VERSION ""

NS_ :

BS_:

BU_: TM

BO_ 579 VCU5: 8 Vector__XXX
 SG_ VcuHazardLampReqStatus : 50|2@0+ (1,0) [0|3] ""  TM
 SG_ VcuHazardLampReq : 51|1@0+ (1,0) [0|1] ""  TM
 SG_ VCuPresence : 0|1@0+ (1,0) [0|1] ""  TM
 SG_ BrkVacPumpStatus : 40|1@0+ (1,0) [0|1] ""  TM
 SG_ DriveMotorStatus : 53|1@0+ (1,0) [0|1] ""  TM
 SG_ HvBattSoh : 52|1@0+ (1,0) [0|1] ""  TM
 SG_ RegenAmpHr : 29|8@0+ (0.5,0) [0|125] ""  TM
 SG_ HvBattPackVolStatus : 55|2@0+ (1,0) [0|3] ""  TM
 SG_ HvBattPackVol : 37|13@0+ (0.1,0) [0|500] ""  TM
 SG_ AvgEnergyConsmption : 48|9@0+ (1,0) [0|511] "kwH/Km"  TM
 SG_ AvgEnergyConsmptionStatus : 17|2@0+ (1,0) [0|3] ""  TM
 SG_ MotorHightempStatus : 19|2@0+ (1,0) [0|3] ""  TM
 SG_ MotorHightemp : 31|2@0+ (1,0) [0|3] ""  TM
 SG_ VcuGearSelectionChangeTxt : 21|2@0+ (1,0) [0|3] ""  TM
 SG_ ImmoStatusVcu : 8|1@0+ (1,0) [0|1] ""  TM
 SG_ ClntTempVcuStatus : 23|2@0+ (1,0) [0|3] ""  TM
 SG_ ClntTempVcu : 15|7@0+ (1,-10) [-10|80] "deg"  TM
 SG_ GearForDisplayVcu : 7|4@0+ (1,0) [0|15] ""  TM
 SG_ GearForDisplayVcuStatus : 3|2@0+ (1,0) [0|3] ""  TM

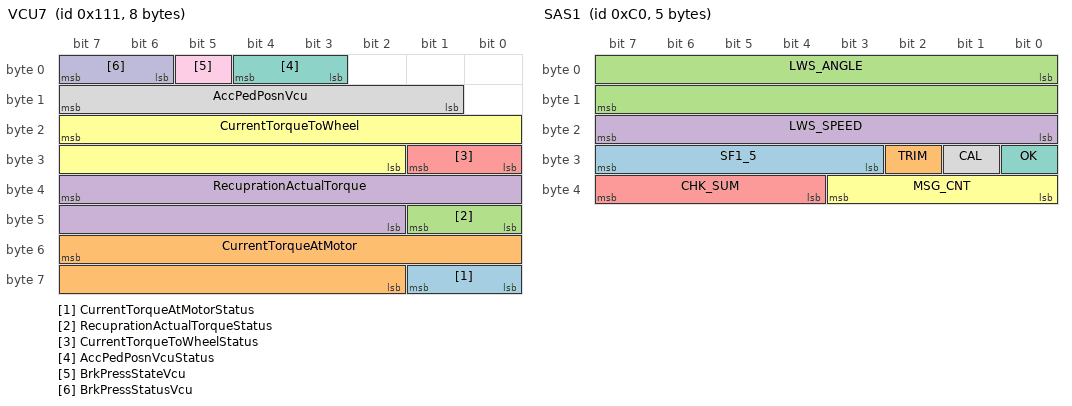
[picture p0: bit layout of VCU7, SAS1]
BO_ 273 VCU7: 8 Vector__XXX
 SG_ CurrentTorqueAtMotorStatus : 57|2@0+ (1,0) [0|3] ""  TM
 SG_ CurrentTorqueAtMotor : 55|14@0+ (0.25,-2048) [-2048|2047.75] ""  TM
 SG_ RecuprationActualTorqueStatus : 41|2@0+ (1,0) [0|3] ""  TM
 SG_ RecuprationActualTorque : 39|14@0+ (0.25,-2048) [-2048|2047.75] ""  TM
 SG_ CurrentTorqueToWheelStatus : 25|2@0+ (1,0) [0|3] ""  TM
 SG_ CurrentTorqueToWheel : 23|14@0+ (0.25,-2048) [-2048|2047.75] ""  TM
 SG_ AccPedPosnVcuStatus : 4|2@0+ (1,0) [0|3] ""  TM
 SG_ AccPedPosnVcu : 15|7@0+ (1,0) [0|100] "%"  TM
 SG_ BrkPressStateVcu : 5|1@0+ (1,0) [0|1] ""  TM
 SG_ BrkPressStatusVcu : 7|2@0+ (1,0) [0|3] ""  TM

BO_ 192 SAS1: 5 Vector__XXX
 SG_ SF1_5 : 27|5@1+ (1,0) [0|31] ""  TM
 SG_ TRIM : 26|1@1+ (1,0) [0|1] ""  TM
 SG_ LWS_ANGLE : 0|16@1- (0.1,0) [-780|779.9] "degree"  TM
 SG_ LWS_SPEED : 16|8@1+ (4,0) [0|1016] "deg /sec"  TM
 SG_ CHK_SUM : 36|4@1+ (1,0) [0|15] ""  TM
 SG_ MSG_CNT : 32|4@1+ (1,0) [0|15] ""  TM
 SG_ OK : 24|1@1+ (1,0) [0|1] ""  TM
 SG_ CAL : 25|1@1+ (1,0) [0|1] ""  TM

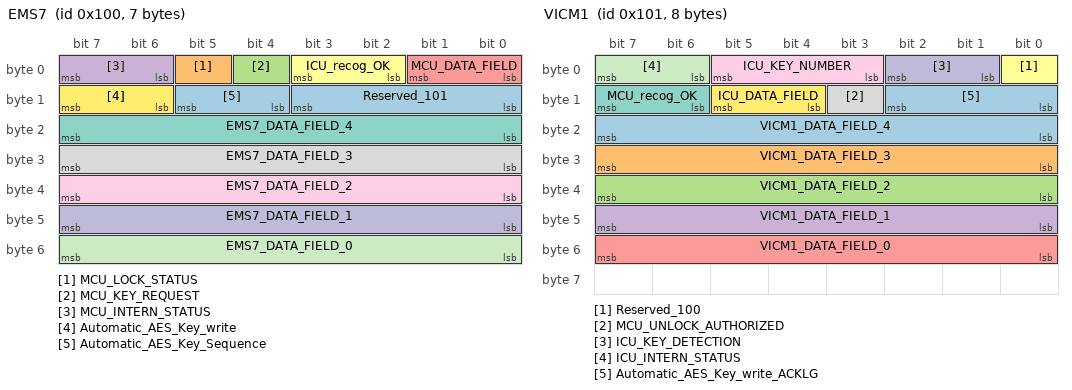
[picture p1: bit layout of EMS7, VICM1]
BO_ 256 EMS7: 7 Vector__XXX
 SG_ Reserved_101 : 11|4@0+ (1,0) [0|0] ""  TM
 SG_ MCU_LOCK_STATUS : 5|1@0+ (1,0) [0|0] ""  TM
 SG_ MCU_KEY_REQUEST : 4|1@0+ (1,0) [0|0] ""  TM
 SG_ MCU_INTERN_STATUS : 7|2@0+ (1,0) [0|0] ""  TM
 SG_ MCU_DATA_FIELD : 1|2@0+ (1,0) [0|0] ""  TM
 SG_ ICU_recog_OK : 3|2@0+ (1,0) [0|0] ""  TM
 SG_ EMS7_DATA_FIELD_4 : 23|8@0+ (1,0) [0|0] ""  TM
 SG_ EMS7_DATA_FIELD_3 : 31|8@0+ (1,0) [0|0] ""  TM
 SG_ EMS7_DATA_FIELD_2 : 39|8@0+ (1,0) [0|0] ""  TM
 SG_ EMS7_DATA_FIELD_1 : 47|8@0+ (1,0) [0|0] ""  TM
 SG_ EMS7_DATA_FIELD_0 : 55|8@0+ (1,0) [0|0] ""  TM
 SG_ Automatic_AES_Key_write : 15|2@0+ (1,0) [0|0] ""  TM
 SG_ Automatic_AES_Key_Sequence : 13|2@0+ (1,0) [0|0] ""  TM

BO_ 257 VICM1: 8 Vector__XXX
 SG_ VICM1_DATA_FIELD_4 : 23|8@0+ (1,0) [0|0] ""  TM
 SG_ VICM1_DATA_FIELD_3 : 31|8@0+ (1,0) [0|0] ""  TM
 SG_ VICM1_DATA_FIELD_2 : 39|8@0+ (1,0) [0|0] ""  TM
 SG_ VICM1_DATA_FIELD_1 : 47|8@0+ (1,0) [0|0] ""  TM
 SG_ VICM1_DATA_FIELD_0 : 55|8@0+ (1,0) [0|0] ""  TM
 SG_ Reserved_100 : 0|1@0+ (1,0) [0|0] ""  TM
 SG_ MCU_recog_OK : 15|2@0+ (1,0) [0|0] ""  TM
 SG_ MCU_UNLOCK_AUTHORIZED : 11|1@0+ (1,0) [0|0] ""  TM
 SG_ ICU_KEY_NUMBER : 5|3@0+ (1,0) [0|0] ""  TM
 SG_ ICU_KEY_DETECTION : 2|2@0+ (1,0) [0|0] ""  TM
 SG_ ICU_INTERN_STATUS : 7|2@0+ (1,0) [0|0] ""  TM
 SG_ ICU_DATA_FIELD : 13|2@0+ (1,0) [0|0] ""  TM
 SG_ Automatic_AES_Key_write_ACKLG : 10|3@0+ (1,0) [0|0] ""  TM

BO_ 259 SRS1: 8 Vector__XXX
 SG_ CrashOutputSignalStatus : 31|2@0+ (1,0) [0|3] ""  TM
 SG_ MSG_CNT_5 : 51|4@0+ (1,0) [0|15] ""  TM
 SG_ CRC_5 : 63|8@0+ (1,0) [0|255] ""  TM
 SG_ RrMiddleSeatBeltSwitchState : 28|1@0+ (1,0) [0|1] ""  TM
 SG_ RrDrvSeatBeltSwitchState : 27|1@0+ (1,0) [0|1] ""  TM
 SG_ RrPassSeatBeltSwitchState : 29|1@0+ (1,0) [0|1] ""  TM
 SG_ FrPassSeatBeltSwitchState : 26|1@0+ (1,0) [0|1] ""  TM
 SG_ FrDrvSeatBeltSwitchState : 25|1@0+ (1,0) [0|1] ""  TM
 SG_ FrDrvSBRChime : 23|2@0+ (1,0) [0|3] ""  TM
 SG_ FrDrvSBRIndication : 24|1@0+ (1,0) [0|1] ""  TM
 SG_ CrashoutputSignal : 7|8@0+ (1,0) [0|255] ""  TM
 SG_ RearDrvSBRChime : 9|2@0+ (1,0) [0|3] ""  TM
 SG_ RearmiddlePassSBRChime : 11|2@0+ (1,0) [0|3] ""  TM
 SG_ FrPassSBRChime : 13|2@0+ (1,0) [0|3] ""  TM
 SG_ RearPassSBRChime : 15|2@0+ (1,0) [0|3] ""  TM
 SG_ RearDrvSBRIndication : 16|1@0+ (1,0) [0|1] ""  TM
 SG_ RearmiddlePassSBRIndication : 17|1@0+ (1,0) [0|1] ""  TM
 SG_ RearPassSBRIndication : 18|1@0+ (1,0) [0|1] ""  TM
 SG_ FrPassSBRIndication : 19|1@0+ (1,0) [0|1] ""  TM
 SG_ SRSWarningLamp : 20|1@0+ (1,0) [0|1] ""  TM
 SG_ PassAirbagDeActIndi : 21|1@0+ (1,0) [0|0] ""  TM

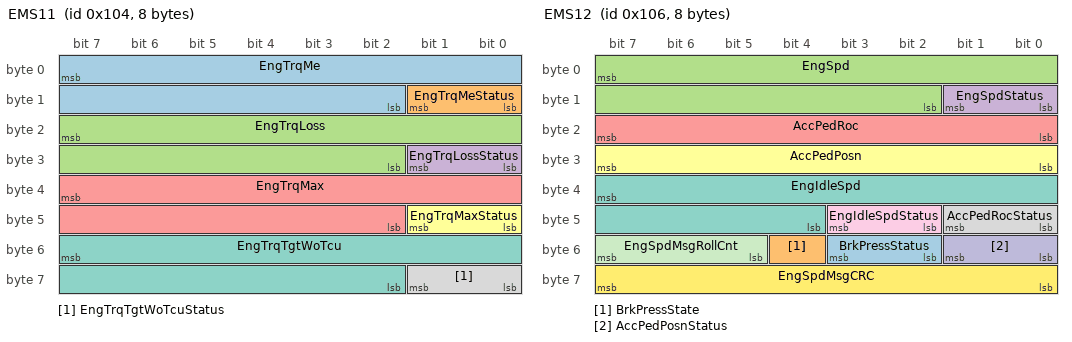
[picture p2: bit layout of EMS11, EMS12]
BO_ 260 EMS11: 8 Vector__XXX
 SG_ EngTrqMe : 7|14@0+ (0.25,-2048) [-2048|2047.75] "Nm"  TM
 SG_ EngTrqMeStatus : 9|2@0+ (1,0) [0|3] ""  TM
 SG_ EngTrqLoss : 23|14@0+ (0.25,-2048) [-2048|2047.75] "Nm"  TM
 SG_ EngTrqLossStatus : 25|2@0+ (1,0) [0|3] ""  TM
 SG_ EngTrqMax : 39|14@0+ (0.25,-2048) [-2048|2047.75] "Nm"  TM
 SG_ EngTrqMaxStatus : 41|2@0+ (1,0) [0|3] ""  TM
 SG_ EngTrqTgtWoTcu : 55|14@0+ (0.25,-2048) [-2048|2047.75] "Nm"  TM
 SG_ EngTrqTgtWoTcuStatus : 57|2@0+ (1,0) [0|3] ""  TM

BO_ 262 EMS12: 8 Vector__XXX
 SG_ BrkPressStatus : 51|2@0+ (1,0) [0|3] ""  TM
 SG_ BrkPressState : 52|1@0+ (1,0) [0|1] ""  TM
 SG_ EngSpd : 7|14@0+ (1,0) [0|16383] "rpm"  TM
 SG_ EngSpdStatus : 9|2@0+ (1,0) [0|3] ""  TM
 SG_ AccPedRoc : 23|8@0+ (16,-2000) [-2000|2000] "% / s"  TM
 SG_ AccPedPosn : 31|8@0+ (0.5,0) [0|100] "%"  TM
 SG_ EngIdleSpd : 39|12@0+ (1,0) [0|3000] "rpm"  TM
 SG_ AccPedRocStatus : 41|2@0+ (1,0) [0|3] ""  TM
 SG_ EngIdleSpdStatus : 43|2@0+ (1,0) [0|3] ""  TM
 SG_ AccPedPosnStatus : 49|2@0+ (1,0) [0|3] ""  TM
 SG_ EngSpdMsgRollCnt : 55|3@0+ (1,0) [0|7] ""  TM
 SG_ EngSpdMsgCRC : 63|8@0+ (1,0) [0|255] ""  TM

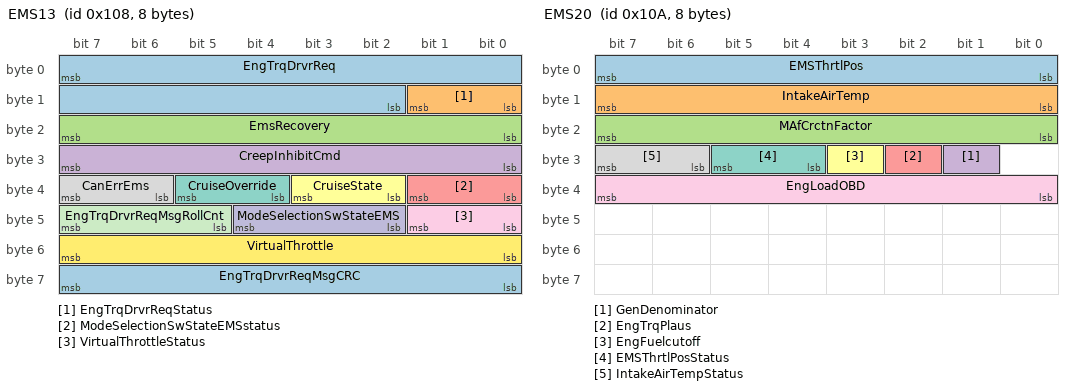
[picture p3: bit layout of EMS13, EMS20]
BO_ 264 EMS13: 8 Vector__XXX
 SG_ EngTrqDrvrReq : 7|14@0+ (0.25,-2048) [-2048|2047.75] "Nm"  TM
 SG_ EngTrqDrvrReqStatus : 9|2@0+ (1,0) [0|3] ""  TM
 SG_ EmsRecovery : 23|8@0+ (1,0) [0|255] ""  TM
 SG_ CreepInhibitCmd : 31|8@0+ (1,0) [0|255] ""  TM
 SG_ ModeSelectionSwStateEMSstatus : 33|2@0+ (1,0) [0|3] ""  TM
 SG_ CruiseState : 35|2@0+ (1,0) [0|3] ""  TM
 SG_ CruiseOverride : 37|2@0+ (1,0) [0|3] ""  TM
 SG_ CanErrEms : 39|2@0+ (1,0) [0|3] ""  TM
 SG_ VirtualThrottleStatus : 41|2@0+ (1,0) [0|3] ""  TM
 SG_ ModeSelectionSwStateEMS : 44|3@0+ (1,0) [0|7] ""  TM
 SG_ EngTrqDrvrReqMsgRollCnt : 47|3@0+ (1,0) [0|7] ""  TM
 SG_ VirtualThrottle : 55|8@0+ (0.5,0) [0|100] "%"  TM
 SG_ EngTrqDrvrReqMsgCRC : 63|8@0+ (1,0) [0|255] ""  TM

BO_ 266 EMS20: 8 Vector__XXX
 SG_ EMSThrtlPos : 7|8@0+ (0.4694836,-15.0234752) [-15.0234752|104.694843] "%"  TM
 SG_ IntakeAirTemp : 15|8@0+ (0.75,-48) [-48|143.25] "DegC"  TM
 SG_ MAfCrctnFactor : 23|8@0+ (0.00781,0) [0|1.99155] ""  TM
 SG_ GenDenominator : 25|1@0+ (1,0) [0|1] ""  TM
 SG_ EngTrqPlaus : 26|1@0+ (1,0) [0|1] ""  TM
 SG_ EngFuelcutoff : 27|1@0+ (1,0) [0|1] ""  TM
 SG_ EMSThrtlPosStatus : 29|2@0+ (1,0) [0|3] ""  TM
 SG_ IntakeAirTempStatus : 31|2@0+ (1,0) [0|3] ""  TM
 SG_ EngLoadOBD : 39|8@0+ (0.3922,0) [0|100] "%"  TM

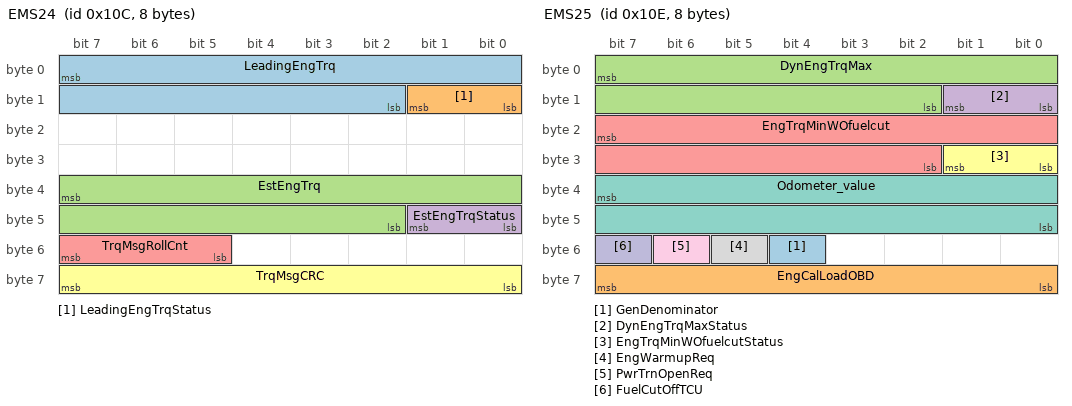
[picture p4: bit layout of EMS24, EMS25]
BO_ 268 EMS24: 8 Vector__XXX
 SG_ LeadingEngTrq : 7|14@0+ (0.25,-2048) [-2048|2047.75] "Nm"  TM
 SG_ LeadingEngTrqStatus : 9|2@0+ (1,0) [0|3] ""  TM
 SG_ EstEngTrq : 39|14@0+ (0.25,-2048) [-2048|2047.75] "Nm"  TM
 SG_ EstEngTrqStatus : 41|2@0+ (1,0) [0|3] ""  TM
 SG_ TrqMsgRollCnt : 55|3@0+ (1,0) [0|7] ""  TM
 SG_ TrqMsgCRC : 63|8@0+ (1,0) [0|255] ""  TM

BO_ 270 EMS25: 8 Vector__XXX
 SG_ GenDenominator : 52|1@0+ (1,0) [0|1] ""  TM
 SG_ EngCalLoadOBD : 63|8@0+ (0.75,0) [0|191.25] ""  TM
 SG_ DynEngTrqMax : 7|14@0+ (0.25,-2048) [-2048|2047.75] "Nm"  TM
 SG_ DynEngTrqMaxStatus : 9|2@0+ (1,0) [0|3] ""  TM
 SG_ EngTrqMinWOfuelcut : 23|14@0+ (0.25,0) [-2048|2047.75] "Nm"  TM
 SG_ EngTrqMinWOfuelcutStatus : 25|2@0+ (1,0) [0|3] ""  TM
 SG_ Odometer_value : 39|16@0+ (1,0) [0|65535] "km/Count"  TM
 SG_ EngWarmupReq : 53|1@0+ (1,0) [0|1] ""  TM
 SG_ PwrTrnOpenReq : 54|1@0+ (1,0) [0|1] ""  TM
 SG_ FuelCutOffTCU : 55|1@0+ (1,0) [0|1] ""  TM

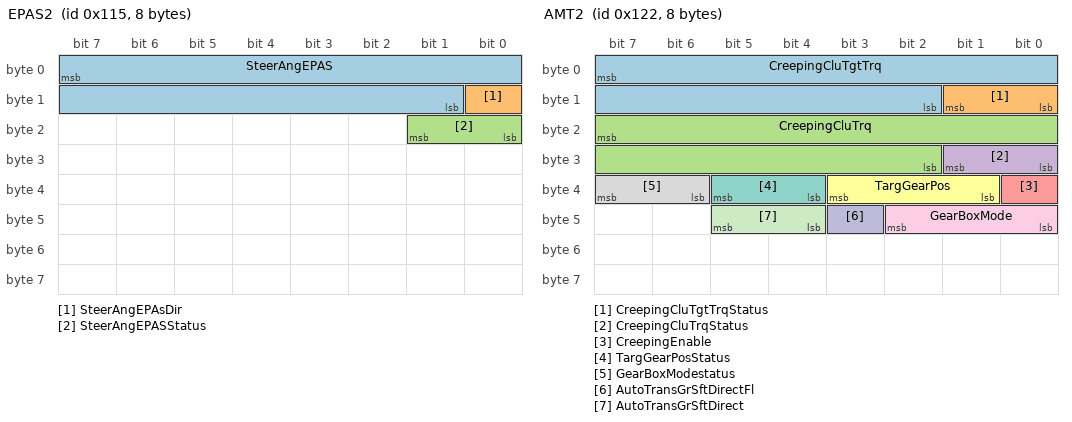
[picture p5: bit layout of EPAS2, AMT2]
BO_ 277 EPAS2: 8 Vector__XXX
 SG_ SteerAngEPAS : 7|15@0+ (0.04375,0) [0|1433.55625] " deg"  TM
 SG_ SteerAngEPAsDir : 8|1@0+ (1,0) [0|1] ""  TM
 SG_ SteerAngEPASStatus : 17|2@0+ (1,0) [0|3] ""  TM

BO_ 279 BRAKE4: 8 Vector__XXX
 SG_ SAsCcw : 20|4@0+ (1,0) [0|15] ""  TM

BO_ 288 AMT1: 8 Vector__XXX
 SG_ RESSEnableStatus : 55|2@0+ (1,0) [0|3] ""  TM
 SG_ RESSEnable : 24|1@0+ (1,0) [0|1] ""  TM
 SG_ EngTrqReq : 7|14@0+ (0.25,-2048) [-2048|2047.75] "Nm"  TM
 SG_ EngTrqReqStatus : 9|2@0+ (1,0) [0|3] ""  TM
 SG_ EngTrqReqComplement : 23|14@0+ (0.25,-2048) [-2048|2047.75] "Nm"  TM
 SG_ CluEngagedStatus : 33|2@0+ (1,0) [0|3] ""  TM
 SG_ CluEngagedTCU : 35|2@0+ (1,0) [0|3] ""  TM
 SG_ MessageCounterAmt : 39|4@0+ (1,0) [0|15] ""  TM
 SG_ TransLimpHomeActive : 40|1@0+ (1,0) [0|1] ""  TM
 SG_ EngStopReq : 41|1@0+ (1,0) [0|1] ""  TM
 SG_ CrnkEnable : 42|1@0+ (1,0) [0|1] ""  TM
 SG_ EngTrqCtrlActive : 43|1@0+ (1,0) [0|1] ""  TM
 SG_ HydraulicPumpActive : 44|1@0+ (1,0) [0|1] ""  TM
 SG_ ReqTrqValueActive : 45|1@0+ (1,0) [0|1] ""  TM
 SG_ EngTrqIncActive : 46|1@0+ (1,0) [0|1] ""  TM
 SG_ EngTrqRednActive : 47|1@0+ (1,0) [0|1] ""  TM
 SG_ CurGearTcuStatus : 49|2@0+ (1,0) [0|3] ""  TM
 SG_ CurGearTcu : 53|4@0+ (1,0) [0|15] ""  TM
 SG_ EngStopReqComplement : 63|8@0+ (1,0) [0|255] ""  TM

BO_ 290 AMT2: 8 Vector__XXX
 SG_ CreepingCluTgtTrq : 7|14@0+ (0.25,-2048) [-2048|2047.75] "Nm"  TM
 SG_ CreepingCluTgtTrqStatus : 9|2@0+ (1,0) [0|3] ""  TM
 SG_ CreepingCluTrq : 23|14@0+ (0.25,-2048) [-2048|2047.75] "Nm"  TM
 SG_ CreepingCluTrqStatus : 25|2@0+ (1,0) [0|3] ""  TM
 SG_ CreepingEnable : 32|1@0+ (1,0) [0|1] ""  TM
 SG_ TargGearPos : 35|3@0+ (1,0) [0|7] ""  TM
 SG_ TargGearPosStatus : 37|2@0+ (1,0) [0|3] ""  TM
 SG_ GearBoxModestatus : 39|2@0+ (1,0) [0|3] ""  TM
 SG_ GearBoxMode : 42|3@0+ (1,0) [0|7] ""  TM
 SG_ AutoTransGrSftDirectFl : 43|1@0+ (1,0) [0|1] ""  TM
 SG_ AutoTransGrSftDirect : 45|2@0+ (1,0) [0|3] ""  TM

BO_ 291 DCT4: 8 Vector__XXX
 SG_ ReserveTorqueRequestIntervention : 42|1@0+ (1,0) [0|1] ""  TM
 SG_ ReserveTorqueRequest : 41|6@0+ (1,0) [0|50] "Nm"  TM
 SG_ DctPepsLockState : 44|2@0+ (1,0) [0|3] ""  TM
 SG_ RESSEnableDctStatus : 46|2@0+ (1,0) [0|3] ""  TM
 SG_ RESSEnableDct : 47|1@0+ (1,0) [0|1] ""  TM
 SG_ CreepState : 32|1@0+ (1,0) [0|1] ""  TM
 SG_ TCUTxFastTrqMsgRollCnt : 51|4@0+ (1,0) [0|15] ""  TM
 SG_ TCUTxFastTrqMsgCRC : 63|8@0+ (1,0) [0|255] ""  TM
 SG_ TxmnGearRatio : 7|15@0+ (0.001,0) [0|32.767] ""  TM
 SG_ TransLimpHomeActive : 8|1@0+ (1,0) [0|1] ""  TM
 SG_ FastTrqIntrvntnStatus : 17|2@0+ (1,0) [0|3] ""  TM
 SG_ FastTrqIntrvntn : 19|2@0+ (1,0) [0|3] ""  TM
 SG_ SlowTrqIntrvntnStatus : 21|2@0+ (1,0) [0|3] ""  TM
 SG_ SlowTrqIntrvntn : 23|2@0+ (1,0) [0|3] ""  TM
 SG_ AutoTransGrSftDirect : 25|2@0+ (1,0) [0|3] ""  TM
 SG_ CurGearDctStatus : 27|2@0+ (1,0) [0|3] ""  TM
 SG_ CurGearDct : 31|4@0+ (1,0) [0|15] ""  TM
 SG_ TargGearPosDctStatus : 34|2@0+ (1,0) [0|3] ""  TM
 SG_ TargGearPosDct : 38|4@0+ (1,0) [0|15] ""  TM
 SG_ AutoTransGrSftDirectFl : 39|1@0+ (1,0) [0|1] ""  TM

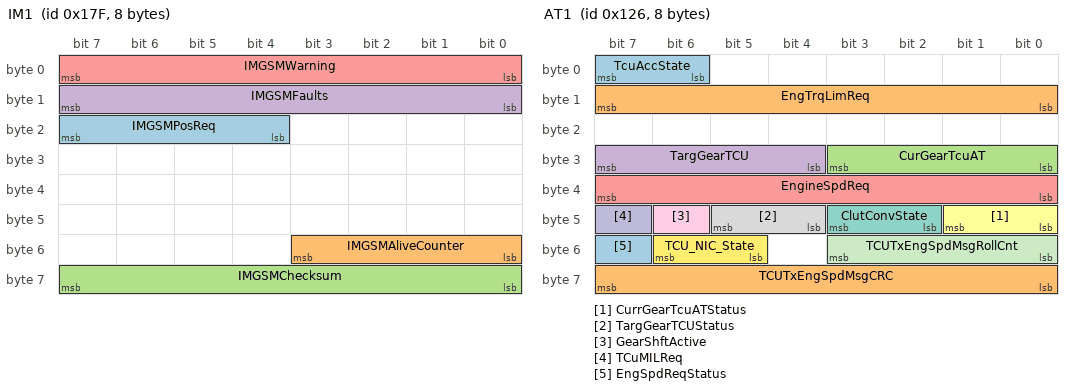
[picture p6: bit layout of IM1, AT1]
BO_ 383 IM1: 8 Vector__XXX
 SG_ IMGSMPosReq : 23|4@0+ (1,0) [0|15] ""  TM
 SG_ IMGSMAliveCounter : 51|4@0+ (1,0) [0|15] ""  TM
 SG_ IMGSMChecksum : 63|8@0+ (1,0) [0|255] ""  TM
 SG_ IMGSMFaults : 15|8@0+ (1,0) [0|255] ""  TM
 SG_ IMGSMWarning : 7|8@0+ (1,0) [0|255] ""  TM

BO_ 294 AT1: 8 Vector__XXX
 SG_ TcuAccState : 7|2@0+ (1,0) [0|3] ""  TM
 SG_ EngTrqLimReq : 15|8@0+ (3,0) [0|765] "Nm"  TM
 SG_ CurGearTcuAT : 27|4@0+ (1,0) [0|15] ""  TM
 SG_ TargGearTCU : 31|4@0+ (1,0) [0|15] ""  TM
 SG_ EngineSpdReq : 39|8@0+ (10,500) [500|3050] "RPM"  TM
 SG_ CurrGearTcuATStatus : 41|2@0+ (1,0) [0|3] ""  TM
 SG_ ClutConvState : 43|2@0+ (1,0) [0|3] ""  TM
 SG_ TargGearTCUStatus : 45|2@0+ (1,0) [0|3] ""  TM
 SG_ GearShftActive : 46|1@0+ (1,0) [0|1] ""  TM
 SG_ TCuMILReq : 47|1@0+ (1,0) [0|1] ""  TM
 SG_ TCUTxEngSpdMsgRollCnt : 51|4@0+ (1,0) [0|15] ""  TM
 SG_ TCU_NIC_State : 54|2@0+ (1,0) [0|3] ""  TM
 SG_ EngSpdReqStatus : 55|1@0+ (1,0) [0|1] ""  TM
 SG_ TCUTxEngSpdMsgCRC : 63|8@0+ (1,0) [0|255] ""  TM

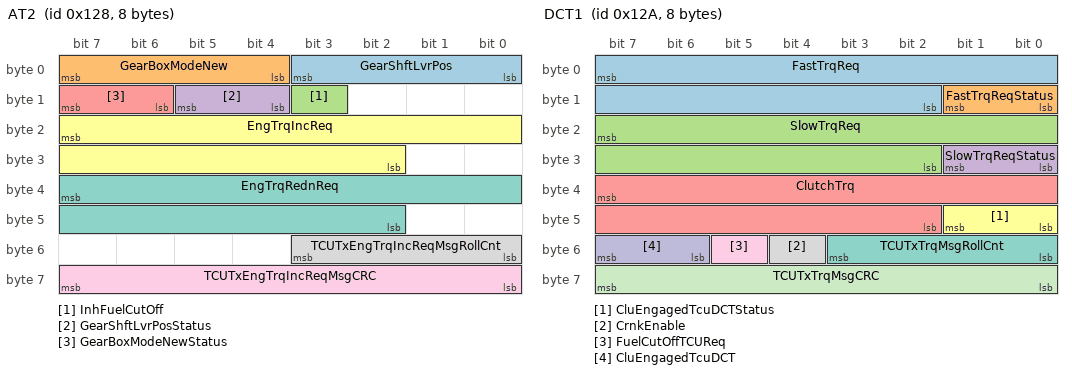
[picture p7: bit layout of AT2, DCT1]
BO_ 296 AT2: 8 Vector__XXX
 SG_ GearShftLvrPos : 3|4@0+ (1,0) [0|15] ""  TM
 SG_ GearBoxModeNew : 7|4@0+ (1,0) [0|15] ""  TM
 SG_ InhFuelCutOff : 11|1@0+ (1,0) [0|1] ""  TM
 SG_ GearShftLvrPosStatus : 13|2@0+ (1,0) [0|3] ""  TM
 SG_ GearBoxModeNewStatus : 15|2@0+ (1,0) [0|3] ""  TM
 SG_ EngTrqIncReq : 23|14@0+ (0.25,-2048) [-2048|2047.75] "Nm"  TM
 SG_ EngTrqRednReq : 39|14@0+ (0.25,-2048) [-2048|2047.75] "Nm"  TM
 SG_ TCUTxEngTrqIncReqMsgRollCnt : 51|4@0+ (1,0) [0|15] ""  TM
 SG_ TCUTxEngTrqIncReqMsgCRC : 63|8@0+ (1,0) [0|255] ""  TM

BO_ 298 DCT1: 8 Vector__XXX
 SG_ FastTrqReq : 7|14@0+ (0.25,-2048) [-2048|2047.75] "Nm"  TM
 SG_ FastTrqReqStatus : 9|2@0+ (1,0) [0|3] ""  TM
 SG_ SlowTrqReq : 23|14@0+ (0.25,-2048) [-2048|2047.75] "Nm"  TM
 SG_ SlowTrqReqStatus : 25|2@0+ (1,0) [0|3] ""  TM
 SG_ ClutchTrq : 39|14@0+ (0.25,-2048) [-2048|2047.75] "Nm"  TM
 SG_ CluEngagedTcuDCTStatus : 41|2@0+ (1,0) [0|3] ""  TM
 SG_ TCUTxTrqMsgRollCnt : 51|4@0+ (1,0) [0|15] ""  TM
 SG_ CrnkEnable : 52|1@0+ (1,0) [0|1] ""  TM
 SG_ FuelCutOffTCUReq : 53|1@0+ (1,0) [0|1] ""  TM
 SG_ CluEngagedTcuDCT : 55|2@0+ (1,0) [0|3] ""  TM
 SG_ TCUTxTrqMsgCRC : 63|8@0+ (1,0) [0|255] ""  TM

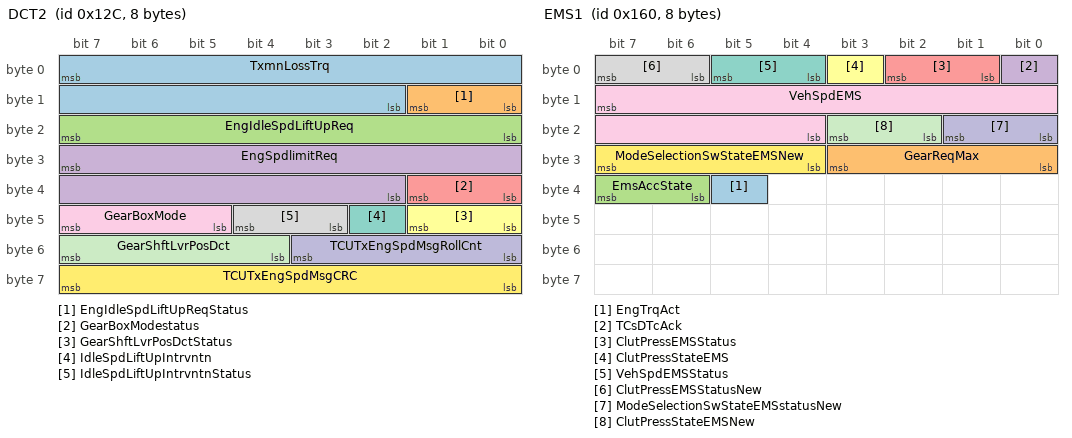
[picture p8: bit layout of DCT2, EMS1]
BO_ 300 DCT2: 8 Vector__XXX
 SG_ TxmnLossTrq : 7|14@0+ (0.25,-2048) [-2048|2047.75] "Nm"  TM
 SG_ EngIdleSpdLiftUpReqStatus : 9|2@0+ (1,0) [0|3] ""  TM
 SG_ EngIdleSpdLiftUpReq : 23|8@0+ (10,0) [0|2000] "rpm"  TM
 SG_ EngSpdlimitReq : 31|14@0+ (1,0) [0|16383] "rpm"  TM
 SG_ GearBoxModestatus : 33|2@0+ (1,0) [0|3] ""  TM
 SG_ GearShftLvrPosDctStatus : 41|2@0+ (1,0) [0|3] ""  TM
 SG_ IdleSpdLiftUpIntrvntn : 42|1@0+ (1,0) [0|1] ""  TM
 SG_ IdleSpdLiftUpIntrvntnStatus : 44|2@0+ (1,0) [0|3] ""  TM
 SG_ GearBoxMode : 47|3@0+ (1,0) [0|7] ""  TM
 SG_ TCUTxEngSpdMsgRollCnt : 51|4@0+ (1,0) [0|15] ""  TM
 SG_ GearShftLvrPosDct : 55|4@0+ (1,0) [0|15] ""  TM
 SG_ TCUTxEngSpdMsgCRC : 63|8@0+ (1,0) [0|255] ""  TM

BO_ 352 EMS1: 8 Vector__XXX
 SG_ EngTrqAct : 37|1@0+ (1,0) [0|1] ""  TM
 SG_ GearReqMax : 27|4@0+ (1,0) [0|15] ""  TM
 SG_ EmsAccState : 39|2@0+ (1,0) [0|3] ""  TM
 SG_ TCsDTcAck : 0|1@0+ (1,0) [0|1] ""  TM
 SG_ ClutPressEMSStatus : 2|2@0+ (1,0) [0|3] ""  TM
 SG_ ClutPressStateEMS : 3|1@0+ (1,0) [0|1] ""  TM
 SG_ VehSpdEMSStatus : 5|2@0+ (1,0) [0|3] ""  TM
 SG_ ClutPressEMSStatusNew : 7|2@0+ (1,0) [0|3] ""  TM
 SG_ VehSpdEMS : 15|12@0+ (0.03125,0) [0|127.96875] "m/s"  TM
 SG_ ModeSelectionSwStateEMSstatusNew : 17|2@0+ (1,0) [0|3] ""  TM
 SG_ ClutPressStateEMSNew : 19|2@0+ (1,0) [0|3] ""  TM
 SG_ ModeSelectionSwStateEMSNew : 31|4@0+ (1,0) [0|15] ""  TM

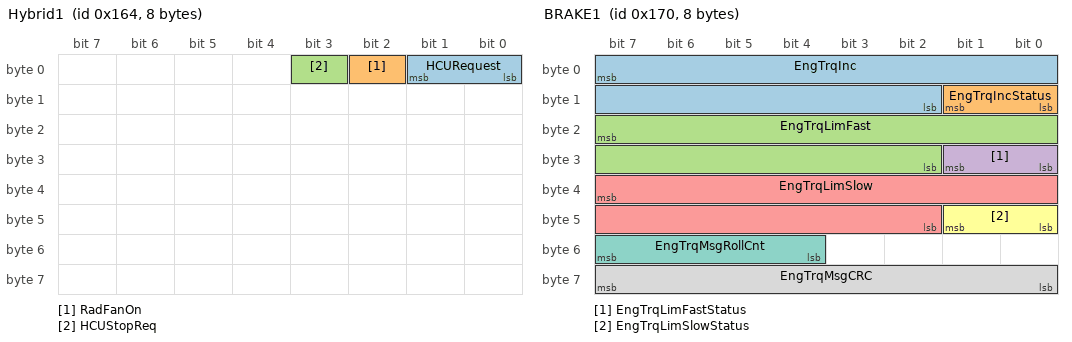
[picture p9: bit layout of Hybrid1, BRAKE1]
BO_ 356 Hybrid1: 8 Vector__XXX
 SG_ HCURequest : 1|2@0+ (1,0) [0|3] ""  TM
 SG_ RadFanOn : 2|1@0+ (1,0) [0|1] ""  TM
 SG_ HCUStopReq : 3|1@0+ (1,0) [0|1] ""  TM

BO_ 359 EEM1: 8 Vector__XXX
 SG_ AltTrq : 7|8@0+ (0.1,0) [0|20] "Nm"  TM

BO_ 368 BRAKE1: 8 Vector__XXX
 SG_ EngTrqInc : 7|14@0+ (0.25,-2048) [-2048|2047.75] "Nm"  TM
 SG_ EngTrqIncStatus : 9|2@0+ (1,0) [0|3] ""  TM
 SG_ EngTrqLimFast : 23|14@0+ (0.25,-2048) [-2048|2047.75] "Nm"  TM
 SG_ EngTrqLimFastStatus : 25|2@0+ (1,0) [0|3] ""  TM
 SG_ EngTrqLimSlow : 39|14@0+ (0.25,-2048) [-2048|2047.75] "Nm"  TM
 SG_ EngTrqLimSlowStatus : 41|2@0+ (1,0) [0|3] ""  TM
 SG_ EngTrqMsgRollCnt : 55|4@0+ (1,0) [0|15] ""  TM
 SG_ EngTrqMsgCRC : 63|8@0+ (1,0) [0|255] ""  TM

CM_ SG_ 579 VcuHazardLampReqStatus "Hazard lamp operation status from VCU to BCM";
CM_ SG_ 579 VcuHazardLampReq "Hazard lamp operation request from VCU to BCM";
CM_ SG_ 579 VCuPresence "ECU presence signal to the partner ECU";
CM_ SG_ 579 BrkVacPumpStatus "This function displays status of the Brake Vaccum Pump Malfunctioning";
CM_ SG_ 579 DriveMotorStatus "This function displays status of the Drive Motor Malfunctioning";
CM_ SG_ 579 HvBattSoh "HV Battery State of Health";
CM_ SG_ 579 RegenAmpHr "Regeneration Battery Charge";
CM_ SG_ 579 HvBattPackVolStatus "HV Battery Pack Voltage Status";
CM_ SG_ 579 HvBattPackVol "HV Battery Pack Voltage";
CM_ SG_ 579 AvgEnergyConsmption "Average Energy Consumption";
CM_ SG_ 579 AvgEnergyConsmptionStatus "Average Energy Consumption Status";
CM_ SG_ 579 MotorHightempStatus "This information is used to determine the Motor High Temp Status";
CM_ SG_ 579 MotorHightemp "This feature provides the traction motor High Temperature Status to the user.";
CM_ SG_ 579 VcuGearSelectionChangeTxt "Indicate the VCU Gear Selection Message";
CM_ SG_ 579 ImmoStatusVcu "This gives status of VCU whether mobilized or immobilized.";
CM_ SG_ 579 ClntTempVcuStatus "This information is used to determine the  Battery coolant temperature signal status. 
";
CM_ SG_ 579 ClntTempVcu "This information is used   to display or indicate the coolant temperature 
";
CM_ SG_ 579 GearForDisplayVcu "Gear For Display";
CM_ SG_ 579 GearForDisplayVcuStatus "Gear For Display Status";
CM_ SG_ 273 CurrentTorqueAtMotorStatus "Status signal of Current Torque At Motor";
CM_ SG_ 273 CurrentTorqueAtMotor "Current Torque At Motor values";
CM_ SG_ 273 RecuprationActualTorqueStatus "Recupration Request Status";
CM_ SG_ 273 RecuprationActualTorque "Recupration Torque values";
CM_ SG_ 273 CurrentTorqueToWheelStatus "Status signal of Current Torque To Wheel signal";
CM_ SG_ 273 CurrentTorqueToWheel "Current Torque To Wheel values";
CM_ SG_ 273 AccPedPosnVcuStatus "This information is used to determine the accelerator pedal position signal status";
CM_ SG_ 273 AccPedPosnVcu "This information is used to determine the accelerator pedal position";
CM_ SG_ 273 BrkPressStateVcu "This inofmation tells whether brake is pressed  or not ";
CM_ SG_ 273 BrkPressStatusVcu "This information is used to determine the  Brake press status signal status. ";
CM_ SG_ 192 SF1_5 "Bosch Internal";
CM_ SG_ 192 TRIM "Triming status of steering angle sensor [Bosch internal]";
CM_ SG_ 192 LWS_ANGLE "Current steering wheel angle
";
CM_ SG_ 192 LWS_SPEED "Steering wheel rotation speed
";
CM_ SG_ 192 CHK_SUM "Check sum for SAS Messages
";
CM_ SG_ 192 MSG_CNT "Message Counter for SAS Message
";
CM_ SG_ 192 OK "The signal indicates the failure status of the steering angle sensor
";
CM_ SG_ 192 CAL "Calibration status of the steering angle sensor
";
CM_ SG_ 256 MCU_LOCK_STATUS "MCU_LOCK_STATUS is given for information.
The MCU repeats the Immobiliser Authentication process every TDelayStopped but MCU will stay in UNLOCKED state (only when the previous authentication is successful)";
CM_ SG_ 256 MCU_KEY_REQUEST "MCU_KEY_REQUEST is checked by ICU
This data is set to force a new key detection by immobilizer ICU.
At IGN ON, this data is not expected as the ICU will directly start key detection before MCU is awake.";
CM_ SG_ 256 MCU_INTERN_STATUS "MCU_INTERN_STATUS is checked by ICU.
Only the value 11b and 01b are allowed to perform MCU-ICU authentication. Other value means
that the MCU is blank or not OK to work.";
CM_ SG_ 256 MCU_DATA_FIELD "MCU_DATA_FIELD is checked by ICU
2 values indicate which of the 2 expected frames is sent, RNmcu or R5icu.
1 value indicates that the field is empty because in CAN frames, no data relative to a running authentication is sent.
";
CM_ SG_ 256 ICU_recog_OK "ICU_recog_OK is for information.
It is not available before end of authentication.
ICU won’t manage this information during authentication.";
CM_ SG_ 256 EMS7_DATA_FIELD_4 "(DATA_FIELD_4 : RNmcu_4 or R5icu _4 or Sk0- Sk3 else blanked)";
CM_ SG_ 256 EMS7_DATA_FIELD_3 "(DATA_FIELD_3: RNmcu _3 or R5icu _3 or Sk4-Sk7 else blanked)";
CM_ SG_ 256 EMS7_DATA_FIELD_2 "(DATA_FIELD_2: RNmcu _2 or R5icu _2 or Sk8-Sk11 else blanked)";
CM_ SG_ 256 EMS7_DATA_FIELD_1 "(DATA_FIELD_1: RNmcu _1 or R5icu _1 or Sk12-Sk15 else blanked)";
CM_ SG_ 256 EMS7_DATA_FIELD_0 "(DATA_FIELD_0: RNmcu _0 or R5icu _0 or else blanked conditions)";
CM_ SG_ 257 VICM1_DATA_FIELD_4 "(DATA_FIELD_4 : RNicu _4 or R5mcu_4 or Sk0- Sk3 else blanked)";
CM_ SG_ 257 VICM1_DATA_FIELD_3 "(DATA_FIELD_3: RNicu _3 or R5mcu _3 or Sk4-Sk7 else blanked)";
CM_ SG_ 257 VICM1_DATA_FIELD_2 "(DATA_FIELD_2: RNicu _2 or R5mcu _2 or Sk8-Sk11 else blanked)";
CM_ SG_ 257 VICM1_DATA_FIELD_1 "(DATA_FIELD_1: RNicu _1 or R5mcu _1 or Sk12-Sk15 else blanked)";
CM_ SG_ 257 VICM1_DATA_FIELD_0 "(DATA_FIELD_0: RNicu _0 or R5mcu _0 or else blanked conditions)";
CM_ SG_ 257 MCU_recog_OK "MCU_recog_OK is checked by MCU
This information is used in 2nd frame to confirm that MCU answer for authentication was ok
(equivalent to R5icu was the one expected by ICU).
If ICU is not ok, its final answer won’t allow mutual authentication for MCU.";
CM_ SG_ 257 MCU_UNLOCK_AUTHORIZED "MCU_UNLOCK_AUTHORIZED is checked by MCU
This information is used in 2nd frame to confirm that MCU is allowed to be unlocked.
It can be considerate as the main answer from the ICU to authentication request.
DATA_FIELD are checked by MCU";
CM_ SG_ 257 ICU_KEY_NUMBER "ICU_KEY_NUMBER is given for information.MCU is allowed to test immobilizer number of learned key.Value higher or equal to 1 is expected to be sure that the immobilizer is in a proper status.";
CM_ SG_ 257 ICU_KEY_DETECTION "ICU_KEY_DETECTION, in second ICU frame, is checked by MCU
When MCU_ICU authentication started, key detection can be already performed or still running.";
CM_ SG_ 257 ICU_INTERN_STATUS "ICU_INTERN_STATUS is checked by MCU.
Only the value 11b and 01b are allowed for the MCU-ICU authentication. Other value means
that the ICU is blank or not ok to work.";
CM_ SG_ 257 ICU_DATA_FIELD "ICU_DATA_FIELD is checked by MCU
2 values indicate which of the 2 expected frames is sent (RNicu or R5mcu).
value (00b) indicates that the field is empty because authentication failed,";
CM_ SG_ 259 CrashOutputSignalStatus "Plausibility status of signal 'CrashOutputSignal'";
CM_ SG_ 259 MSG_CNT_5 "MRC for CrashOutputSignals";
CM_ SG_ 259 CRC_5 "CRC for CrashOutput signals";
CM_ SG_ 259 RrMiddleSeatBeltSwitchState "This function displays status of Rear Middle seatbelt buckle switch";
CM_ SG_ 259 RrDrvSeatBeltSwitchState "This function displays status of Rear Driver seatbelt buckle switch";
CM_ SG_ 259 RrPassSeatBeltSwitchState "This function displays status of Rear Passenger seatbelt buckle switch";
CM_ SG_ 259 FrPassSeatBeltSwitchState "This function displays status of Front Passenger seatbelt buckle switch";
CM_ SG_ 259 FrDrvSeatBeltSwitchState "This function displays status of Front Driver seatbelt buckle switch";
CM_ SG_ 259 FrDrvSBRChime "Chime request signal  to IC Display for driver";
CM_ SG_ 259 FrDrvSBRIndication "Visual Indication request signal to SBR Display  for driver";
CM_ SG_ 259 CrashoutputSignal "CrashOutput signal in the event of no Crash";
CM_ SG_ 259 RearDrvSBRChime "Chime request signal to IC Display for Rear Driver passenger";
CM_ SG_ 259 RearmiddlePassSBRChime "Chime request signal  to IC Display for rear middle passenger";
CM_ SG_ 259 FrPassSBRChime "Chime request signal to IC Display  for passenger";
CM_ SG_ 259 RearPassSBRChime "Chime request signal to IC Display for rear passenger";
CM_ SG_ 259 RearDrvSBRIndication "Visual Indication request signal to SBR Display for Rear Driver passengerr";
CM_ SG_ 259 RearmiddlePassSBRIndication "Visual Indication request signal to SBR Display for Rear middle Driver passengerr";
CM_ SG_ 259 RearPassSBRIndication "Visual Indication request signal to SBR Display for rear passenger";
CM_ SG_ 259 FrPassSBRIndication "Visual indication request signal to SBR display for passenger.";
CM_ SG_ 259 SRSWarningLamp "AWL Warning Lamp signal Request to IC";
CM_ SG_ 259 PassAirbagDeActIndi "PAD Indication signal request to SBR Display";
CM_ SG_ 260 EngTrqMe "Current engine torque, reduced by engine drag torque (friction) and torque consumption of auxiliary devices, but without inertia correction.
";
CM_ SG_ 260 EngTrqMeStatus "Current engine torque, status info";
CM_ SG_ 260 EngTrqLoss "used to know torque loss by accessories";
CM_ SG_ 260 EngTrqLossStatus "Engine torque requested by driver, status info
";
CM_ SG_ 260 EngTrqMax "allowable maximum torque at flywheel at specific operating point, delivered by the engine";
CM_ SG_ 260 EngTrqMaxStatus "quality/status information to EngTrqLimSlow";
CM_ SG_ 260 EngTrqTgtWoTcu "This signal indicates what should be the target torque after the gear shift.";
CM_ SG_ 260 EngTrqTgtWoTcuStatus "quality/status information to EngTrqTgtWoTcu";
CM_ SG_ 262 BrkPressStatus "status information of Brake pedal";
CM_ SG_ 262 BrkPressState "This inofmation tells whether brake is pressed  or not ";
CM_ SG_ 262 EngSpd "Crank shaft speed of engine";
CM_ SG_ 262 EngSpdStatus "Crank shaft speed of engine, status
";
CM_ SG_ 262 AccPedRoc "accelerator pedal position rate of change
gradient of APM signal";
CM_ SG_ 262 AccPedPosn "accelerator pedal position.";
CM_ SG_ 262 EngIdleSpd "engine idle speed is Engine RPM signal at 0% acclerator pedal condition";
CM_ SG_ 262 AccPedRocStatus "Accelerator pedal rate of change, status
";
CM_ SG_ 262 EngIdleSpdStatus "Crank shaft speed of engine status
";
CM_ SG_ 262 AccPedPosnStatus "Accelerator pedal position, status info
";
CM_ SG_ 262 EngSpdMsgRollCnt "rolling counter for message 0x106";
CM_ SG_ 262 EngSpdMsgCRC "CRC for the message 0x106";
CM_ SG_ 264 EngTrqDrvrReq "engine torque at flywheel, requested by driver";
CM_ SG_ 264 EngTrqDrvrReqStatus "engine torque at flywheel, requested by driver ,status information";
CM_ SG_ 264 EmsRecovery "EMS recovery command ";
CM_ SG_ 264 CreepInhibitCmd " Inhibit creeping function under certain conditions";
CM_ SG_ 264 ModeSelectionSwStateEMSstatus "Status of ModeSelectionSwStateEMS";
CM_ SG_ 264 CruiseState "Cruise control active / Cruise control failed";
CM_ SG_ 264 CruiseOverride "cruise override command ";
CM_ SG_ 264 CanErrEms "EMS CAN error state";
CM_ SG_ 264 VirtualThrottleStatus "This information is used to determine the virtual throttle position status";
CM_ SG_ 264 ModeSelectionSwStateEMS "User Selected Drive Mode Switch information for Latchable &  Non Latchable Switch type Interface for drive mode function";
CM_ SG_ 264 EngTrqDrvrReqMsgRollCnt "rolling counter for message 0x108";
CM_ SG_ 264 VirtualThrottle "This information is used to determine the virtual throttle position";
CM_ SG_ 264 EngTrqDrvrReqMsgCRC "CRC for the message 0x108";
CM_ SG_ 266 EMSThrtlPos "This Signal specifies the Intake Throttle Position";
CM_ SG_ 266 IntakeAirTemp "This Signal specifies the Intake Air Temperature";
CM_ SG_ 266 MAfCrctnFactor "Air Mass flow correction factor for Altitude";
CM_ SG_ 266 GenDenominator "This signal is used for IUPR calculation on TCU side";
CM_ SG_ 266 EngTrqPlaus "This Signal specifies whether there is any error in the Troque measurement / Calculation or not";
CM_ SG_ 266 EngFuelcutoff "Indication that Engine is fuel cut off state";
CM_ SG_ 266 EMSThrtlPosStatus "This Signal specifies the Intake throttle position status";
CM_ SG_ 266 IntakeAirTempStatus "This Signal specifies the Intake Air Temperature";
CM_ SG_ 266 EngLoadOBD "Engine calculated load";
CM_ SG_ 268 LeadingEngTrq "Leading torque mainly includes driver demand , cruise control ,creep torque and shall exculde TCU torque request.";
CM_ SG_ 268 LeadingEngTrqStatus "status information to LeadingEngTrq";
CM_ SG_ 268 EstEngTrq "estimated effective torque  based on current airpath conditions , applied ignition angle and current engine losses";
CM_ SG_ 268 EstEngTrqStatus "status information of EstEngTrq";
CM_ SG_ 268 TrqMsgRollCnt "rolling counter to monitor message (number will be finalised after discussion)";
CM_ SG_ 268 TrqMsgCRC "CRC for the message (number will be finalised after discussion)";
CM_ SG_ 270 GenDenominator "This signal is used for IUPR calculation on TCU side";
CM_ SG_ 270 EngCalLoadOBD "Engine calculated load";
CM_ SG_ 270 DynEngTrqMax "the maximum engine effective torque at crankshaft taking into account current environmental conditions and engine conditions but also the air path dynamic and considering the optimal ignition angle";
CM_ SG_ 270 DynEngTrqMaxStatus "status information";
CM_ SG_ 270 EngTrqMinWOfuelcut "minimum engine torque  with Out fuel cutoff";
CM_ SG_ 270 EngTrqMinWOfuelcutStatus "status information";
CM_ SG_ 270 Odometer_value "This signal is used for to compute distance (e.g. distance travelled with MIL on, distance traveled since last clear DTC)";
CM_ SG_ 270 EngWarmupReq "Engine warm support from EMS";
CM_ SG_ 270 PwrTrnOpenReq " EMS request to open drivetrain (Open clutch or clutches ) ,In case of ?Start and Stop? functionality,";
CM_ SG_ 270 FuelCutOffTCU "flag authorizing the TCU to request a fuel cut-off";
CM_ BO_ 277 "Frame to be enabled through DID for X0,X1 ";
CM_ SG_ 277 SteerAngEPAS "Steering Angle information can be used only for comfort function";
CM_ SG_ 277 SteerAngEPAsDir "Steering wheel angle direction";
CM_ SG_ 277 SteerAngEPASStatus "Steering Angle information can be used only for comfort function,Status info";
CM_ SG_ 279 SAsCcw "The signal indicates SAS command code word.
";
CM_ SG_ 288 RESSEnableStatus "Indicate the status";
CM_ SG_ 288 RESSEnable "This signal indicates that the from TCU point of viewit is ok start engine in remote condition";
CM_ SG_ 288 EngTrqReq "Requested engine torque ";
CM_ SG_ 288 EngTrqReqStatus "Requested engine torque ,status information";
CM_ SG_ 288 EngTrqReqComplement "Complement of the requested engine torque value";
CM_ SG_ 288 CluEngagedStatus "Clutch engaged,Status info";
CM_ SG_ 288 CluEngagedTCU "This signal is used to prevent  jerk ";
CM_ SG_ 288 MessageCounterAmt "Message counter from 0-15
";
CM_ SG_ 288 TransLimpHomeActive "System limp home mode state";
CM_ SG_ 288 EngStopReq "engine stop request ";
CM_ SG_ 288 CrnkEnable "cranking enable flag";
CM_ SG_ 288 EngTrqCtrlActive "engine torque control flag";
CM_ SG_ 288 HydraulicPumpActive "hydraulic pump relay flag";
CM_ SG_ 288 ReqTrqValueActive "request torque value in phase 2 during gearshift";
CM_ SG_ 288 EngTrqIncActive "engine torque request in gearshift phase 3";
CM_ SG_ 288 EngTrqRednActive "engine torque request in gearshift phase 1";
CM_ SG_ 288 CurGearTcuStatus "Indicates the gear engaged,Status";
CM_ SG_ 288 CurGearTcu "indicates the gear engaged
This signal is sent when the gear in the transmission is actually engaged. This signal is used in the EMS to prevent jerk aged. This signal is used in the EMS to prevent jerk ";
CM_ SG_ 288 EngStopReqComplement "Complement of Engine stop request signal";
CM_ SG_ 290 CreepingCluTgtTrq "creeping clutch target torqus";
CM_ SG_ 290 CreepingCluTgtTrqStatus "creeping clutch target torque,Status";
CM_ SG_ 290 CreepingCluTrq "creeping clutch torque";
CM_ SG_ 290 CreepingCluTrqStatus "creeping clutch torque,Status";
CM_ SG_ 290 CreepingEnable "creeping phase state";
CM_ SG_ 290 TargGearPos "This signal indicates that Target gear the AT will use next 
";
CM_ SG_ 290 TargGearPosStatus "status information of TargGearPos
";
CM_ SG_ 290 GearBoxModestatus "Status Information of GearBoxMode Signal";
CM_ SG_ 290 GearBoxMode "automatic gear shift program active for EMS";
CM_ SG_ 290 AutoTransGrSftDirectFl "Automatic Transmission Gear Shift Direction Failure.";
CM_ SG_ 290 AutoTransGrSftDirect "Automatic Transmission Gear Shift Direction";
CM_ SG_ 291 ReserveTorqueRequestIntervention "Torque reserve request Intervention";
CM_ SG_ 291 ReserveTorqueRequest "Torque reserve request functionality";
CM_ SG_ 291 DctPepsLockState "new signal with information about TCU lock status";
CM_ SG_ 291 RESSEnableDctStatus "Indicate the status";
CM_ SG_ 291 RESSEnableDct "This signal indicates that the from TCU point of viewit is ok start engine in remote condition";
CM_ SG_ 291 CreepState "This is required for EMS to understand creep is active or inactive.";
CM_ SG_ 291 TCUTxFastTrqMsgRollCnt "Rolling counter for the entire TCU Tx torque messages  which consists of  FastTrqReq, SlowTrqReq,  ClutchTrq,  TxmnLossTrq";
CM_ SG_ 291 TCUTxFastTrqMsgCRC "CRC for entire TCU Tx torque messages  which consists of  FastTrqReq, SlowTrqReq,  ClutchTrq,  TxmnLossTrq";
CM_ SG_ 291 TxmnGearRatio "Current overall Gear Ratio";
CM_ SG_ 291 TransLimpHomeActive "System limp home mode state";
CM_ SG_ 291 FastTrqIntrvntnStatus "status information";
CM_ SG_ 291 FastTrqIntrvntn "indicates the type of 'Fast torque intervention' requested by TCU ";
CM_ SG_ 291 SlowTrqIntrvntnStatus "status information";
CM_ SG_ 291 SlowTrqIntrvntn "indicates the type of 'Slow  torque intervention' requested by TCU ";
CM_ SG_ 291 AutoTransGrSftDirect "Automatic Transmission Gear Shift Direction";
CM_ SG_ 291 CurGearDctStatus "Indicates the gear engaged,Status";
CM_ SG_ 291 CurGearDct "indicates the gear engaged
This signal is sent when the gear in the transmission is actually engaged. This signal is used in the EMS to prevent jerk";
CM_ SG_ 291 TargGearPosDctStatus "status information of TargGearPos
";
CM_ SG_ 291 TargGearPosDct "indicates the target gear in which DCT will shift engaged. This signal is used in the EMS to prevent jerk 
";
CM_ SG_ 291 AutoTransGrSftDirectFl "Automatic Transmission Gear Shift Direction Failure.";
CM_ SG_ 383 IMGSMPosReq "Driver Transmission Range Request made via the Gear Selector (GSM)";
CM_ SG_ 383 IMGSMAliveCounter "Rolling counter for the entire GSM Tx messages";
CM_ SG_ 383 IMGSMChecksum "CRC for entire GSM Tx messages";
CM_ SG_ 383 IMGSMFaults "Refer FN/FD for bit-mapped signals";
CM_ SG_ 383 IMGSMWarning "Refer FN/FD for bit-mapped signals";
CM_ SG_ 294 TcuAccState "It indicates status of TCU for ACC functionality";
CM_ SG_ 294 EngTrqLimReq "TCU Engine Torque Limit";
CM_ SG_ 294 CurGearTcuAT "indicates the gear engaged
This signal is sent when the gear in the transmission is actually engaged. This signal is used in the EMS to prevent jerk ";
CM_ SG_ 294 TargGearTCU "indicates the gear engaged
This signal is sent when the gear in the transmission is actually engaged. This signal is used in the EMS to prevent jerk ";
CM_ SG_ 294 EngineSpdReq "Engine speed target value";
CM_ SG_ 294 ClutConvState "Clutch Converter State";
CM_ SG_ 294 GearShftActive "Gear Shift in Progress";
CM_ SG_ 294 TCuMILReq "MIL on request";
CM_ SG_ 294 TCUTxEngSpdMsgRollCnt "Rolloing counter for the entire message in AT1";
CM_ SG_ 294 TCU_NIC_State "This signal provides TCU Neutral control  State";
CM_ SG_ 294 EngSpdReqStatus "Engine speed Request Status";
CM_ SG_ 294 TCUTxEngSpdMsgCRC "CRC for the entire message of AT1";
CM_ SG_ 296 GearShftLvrPos "Gear Shifter position";
CM_ SG_ 296 GearBoxModeNew "TCU Active Drive Mode feedback Signal for drive mode";
CM_ SG_ 296 InhFuelCutOff "Engine Fuel Cut Off Status";
CM_ SG_ 296 GearShftLvrPosStatus "Gear Shifter position Status";
CM_ SG_ 296 GearBoxModeNewStatus "Status of TCU Active Drive Mode feedback Signal";
CM_ SG_ 296 EngTrqIncReq "Engine Torque Increment Request";
CM_ SG_ 296 EngTrqRednReq "TCU Engine Torque Reduction Request";
CM_ SG_ 296 TCUTxEngTrqIncReqMsgRollCnt "Rolling counter for entire message of AT2
";
CM_ SG_ 296 TCUTxEngTrqIncReqMsgCRC "CRC for entire message of AT2";
CM_ SG_ 298 FastTrqReq "requested engine torque (by TCU to adjust gear shift)";
CM_ SG_ 298 FastTrqReqStatus "status information";
CM_ SG_ 298 SlowTrqReq "requested engine torque (by TCU to adjust gear shift)";
CM_ SG_ 298 SlowTrqReqStatus "status information";
CM_ SG_ 298 ClutchTrq "synthesis of clutches transmittted torque .";
CM_ SG_ 298 CluEngagedTcuDCTStatus "This CAN signal is used to indicate clutch state status ";
CM_ SG_ 298 TCUTxTrqMsgRollCnt "Rolling counter for the entire TCU Tx torque messages  which consists of  FastTrqReq, 
 SlowTrqReq,  ClutchTrq,  TxmnLossTrq";
CM_ SG_ 298 CrnkEnable "TCU will send this signal when transmission is ok to crank the vehicle. This will use by EMS to crank  the vehicle.";
CM_ SG_ 298 FuelCutOffTCUReq "The TCU  providing a flag explicitly requesting a fuel cut-off.";
CM_ SG_ 298 CluEngagedTcuDCT "This CAN signal is used to indicate clutch state.";
CM_ SG_ 298 TCUTxTrqMsgCRC "CRC for entire TCU Tx torque messages  which consists of  FastTrqReq, 
 SlowTrqReq,  ClutchTrq,  TxmnLossTrq";
CM_ SG_ 300 TxmnLossTrq "information about addition load on engine due to transmission";
CM_ SG_ 300 EngIdleSpdLiftUpReqStatus "status information";
CM_ SG_ 300 EngIdleSpdLiftUpReq "Engine idle speed lift up request";
CM_ SG_ 300 EngSpdlimitReq " Engine speed limitation request from TCU";
CM_ SG_ 300 GearBoxModestatus "Status Information of GearBoxMode Signal";
CM_ SG_ 300 GearShftLvrPosDctStatus "Gear Shifter position Status";
CM_ SG_ 300 IdleSpdLiftUpIntrvntn "Idle speed lift up intervention information";
CM_ SG_ 300 IdleSpdLiftUpIntrvntnStatus "status information";
CM_ SG_ 300 GearBoxMode "automatic gear shift program active for EMS";
CM_ SG_ 300 TCUTxEngSpdMsgRollCnt "CRC for entire message which consists of Engine idle speed lift up request EngIdleSpdLiftUpReq and status EngIdleSpdLiftUpReqStatus, Engine speed limitation request  EngSpdlimitReq";
CM_ SG_ 300 GearShftLvrPosDct "Gear Shifter position";
CM_ SG_ 300 TCUTxEngSpdMsgCRC "CRC for entire message which consists of Engine idle speed lift up request EngIdleSpdLiftUpReq and status EngIdleSpdLiftUpReqStatus, Engine speed limitation request  EngSpdlimitReq";
CM_ SG_ 352 EngTrqAct "Engine Torque Acknowledgement";
CM_ SG_ 352 GearReqMax "this signal is used to request a downshift during cruise control if the vehicle speed error becomes too large";
CM_ SG_ 352 EmsAccState "It indicates status of EMS for ACC functionality";
CM_ SG_ 352 TCsDTcAck "TCS/DTC Acknowledgement to indicate Torque control by EMS is possible or not";
CM_ SG_ 352 ClutPressEMSStatus "status information of ClutchEngaged";
CM_ SG_ 352 ClutPressStateEMS "This inofmation tells whether clutch is pressed (90%) or not ";
CM_ SG_ 352 VehSpdEMSStatus "VehSpdEMSStatusIt indicates the vehicle speed status information";
CM_ SG_ 352 ClutPressEMSStatusNew "status information of ClutchEngaged";
CM_ SG_ 352 VehSpdEMS "This information is the vehicle speed information from EMS";
CM_ SG_ 352 ModeSelectionSwStateEMSstatusNew "Status of ModeSelectionSwStateEMS";
CM_ SG_ 352 ClutPressStateEMSNew "This inofmation tells whether clutch is pressed (90%) or not ";
CM_ SG_ 352 ModeSelectionSwStateEMSNew "User Selected Drive Mode Switch information for Latchable &  Non Latchable Switch type Interface for drive mode function";
CM_ SG_ 356 HCURequest "Hybrid control ECU status";
CM_ SG_ 356 RadFanOn "This signal will help HCU to control motor temperature, if it exceddes set limit (above 105degC)";
CM_ SG_ 356 HCUStopReq "This information is used  to indicate whether request from Hybrid ECU for Engine stop reques";
CM_ SG_ 359 AltTrq "Altrnator Torque Limit Input Signal from EEM ecu";
CM_ SG_ 368 EngTrqInc "Target engine torque increases in Nm.
Signal will be used by EMS ECU for DTC function from ABS and ESP
";
CM_ SG_ 368 EngTrqIncStatus "status information of EngTrqInc
";
CM_ SG_ 368 EngTrqLimFast "target engine torque limit (fast) in NM.
Signal will be used by EMS ECU for ESP/TCS function from ESP
";
CM_ SG_ 368 EngTrqLimFastStatus "status information of EngTrqLimFast
";
CM_ SG_ 368 EngTrqLimSlow "target engine torque limit (slow) in NM.
Signal will be used by EMS ECU for ESP/TCS function from ESP
";
CM_ SG_ 368 EngTrqLimSlowStatus "status information of EngTrqLimSlow
";
CM_ SG_ 368 EngTrqMsgRollCnt "Rolling counter for the message which consists of EngTrqInc, EngTrqLimFast, EngTrqLimSlow";
CM_ SG_ 368 EngTrqMsgCRC "CRC for entire message which consists of EngTrqInc, EngTrqLimFast, EngTrqLimSlo";
BA_DEF_ SG_  "Remarks" STRING ;
BA_DEF_ SG_  "NWM_WakeupAllowed" ENUM  "No","Yes";
BA_DEF_ SG_  "GenSigTimeoutTime_HU_Mid_X451" INT 0 65535;
BA_DEF_ SG_  "GenSigTimeoutTime_HU_High_X451" INT 0 65535;
BA_DEF_ SG_  "GenSigTimeoutTime_HU_B" INT 0 65535;
BA_DEF_ SG_  "GenSigTimeoutTime_HU_A" INT 0 65535;
BA_DEF_ SG_  "GenSigTimeoutTime_BCM_Mid" INT 0 65535;
BA_DEF_ SG_  "GenSigTimeoutMsg_HU_Mid_X451" INT 0 65535;
BA_DEF_ SG_  "GenSigTimeoutMsg_HU_High_X451" INT 0 65535;
BA_DEF_ SG_  "GenSigTimeoutMsg_HU_B" INT 0 65535;
BA_DEF_ SG_  "GenSigTimeoutMsg_HU_A" INT 0 65535;
BA_DEF_ SG_  "GenSigStartValue" INT 0 0;
BA_DEF_ SG_  "GenSigSendType" ENUM  "Cyclic","OnWrite","OnWriteWithRepetition","OnChange","OnChangeWithRepetition","IfActive","IfActiveWithRepetition","NoSigSendType","NotUsed","NotUsed","NotUsed","NotUsed","NotUsed";
BA_DEF_ SG_  "GenSigInactiveValue" INT 0 0;
BA_DEF_ SG_  "GenSigEnvVarType" ENUM  "int","float","undef";
BA_DEF_ SG_  "GenSigCycleTimeActive" INT 0 0;
BA_DEF_ SG_  "GenSigCycleTime" INT 0 0;
BA_DEF_ SG_  "GenSigTimeoutMsg_HU_High_X445" INT 0 65535;
BA_DEF_ SG_  "GenSigTimeoutMsg_HU_Mid_X445" INT 0 65535;
BA_DEF_ SG_  "GenSigTimeoutTime_HU_High_X445" INT 0 65535;
BA_DEF_ SG_  "GenSigTimeoutTime_HU_Mid_X445" INT 0 65535;
BA_DEF_ SG_  "GenSigTimeoutMsg_IVI" INT 0 65535;
BA_DEF_ SG_  "GenSigTimeoutTime_IVI" INT 0 65535;
BA_DEF_ BO_  "NmMessage" ENUM  "no","yes";
BA_DEF_ BO_  "NmAsrMessage" ENUM  "<n.a.>","No","Yes";
BA_DEF_ BO_  "MessageTimeout" INT 0 65535;
BA_DEF_ BO_  "Me" INT 0 0;
BA_DEF_ BO_  "GenMsgStartDelayTime" INT 0 0;
BA_DEF_ BO_  "GenMsgSendType" ENUM  "Cyclic","NotUsed","NotUsed","NotUsed","NotUsed","NotUsed","NotUsed","IfActive","NoMsgSendType","NotUsed";
BA_DEF_ BO_  "GenMsgNrOfRepetition" INT 0 0;
BA_DEF_ BO_  "GenMsgILSupport" ENUM  "No","Yes";
BA_DEF_ BO_  "GenMsgDelayTime" INT 0 0;
BA_DEF_ BO_  "GenMsgCycleTimeFast" INT 0 0;
BA_DEF_ BO_  "GenMsgCycleTime" INT 0 0;
BA_DEF_ BO_  "DiagUudtResponse" ENUM  "false","true";
BA_DEF_ BO_  "DiagUsdtResponse" ENUM  "false","true";
BA_DEF_ BO_  "DiagState" ENUM  "No","Yes";
BA_DEF_ BO_  "DiagResponse" ENUM  "No","Yes";
BA_DEF_ BO_  "DiagRequest" ENUM  "No","Yes";
BA_DEF_ BO_  "MsgType" ENUM  "Application","NM","NMH";
BA_DEF_ SG_  "SystemSignalLongSymbol" STRING ;
BA_DEF_DEF_  "Remarks" "null";
BA_DEF_DEF_  "NWM_WakeupAllowed" "No";
BA_DEF_DEF_  "GenSigTimeoutTime_HU_Mid_X451" 500;
BA_DEF_DEF_  "GenSigTimeoutTime_HU_High_X451" 500;
BA_DEF_DEF_  "GenSigTimeoutTime_HU_B" 500;
BA_DEF_DEF_  "GenSigTimeoutTime_HU_A" 500;
BA_DEF_DEF_  "GenSigTimeoutTime_BCM_Mid" 0;
BA_DEF_DEF_  "GenSigTimeoutMsg_HU_Mid_X451" 500;
BA_DEF_DEF_  "GenSigTimeoutMsg_HU_High_X451" 500;
BA_DEF_DEF_  "GenSigTimeoutMsg_HU_B" 500;
BA_DEF_DEF_  "GenSigTimeoutMsg_HU_A" 500;
BA_DEF_DEF_  "GenSigStartValue" 0;
BA_DEF_DEF_  "GenSigSendType" "Cyclic";
BA_DEF_DEF_  "GenSigInactiveValue" 0;
BA_DEF_DEF_  "GenSigEnvVarType" "undef";
BA_DEF_DEF_  "GenSigCycleTimeActive" 0;
BA_DEF_DEF_  "GenSigCycleTime" 0;
BA_DEF_DEF_  "GenSigTimeoutMsg_HU_High_X445" 500;
BA_DEF_DEF_  "GenSigTimeoutMsg_HU_Mid_X445" 500;
BA_DEF_DEF_  "GenSigTimeoutTime_HU_High_X445" 500;
BA_DEF_DEF_  "GenSigTimeoutTime_HU_Mid_X445" 500;
BA_DEF_DEF_  "GenSigTimeoutMsg_IVI" 500;
BA_DEF_DEF_  "GenSigTimeoutTime_IVI" 500;
BA_DEF_DEF_  "NmMessage" "no";
BA_DEF_DEF_  "NmAsrMessage" "<n.a.>";
BA_DEF_DEF_  "MessageTimeout" 500;
BA_DEF_DEF_  "Me" 0;
BA_DEF_DEF_  "GenMsgStartDelayTime" 0;
BA_DEF_DEF_  "GenMsgSendType" "Cyclic";
BA_DEF_DEF_  "GenMsgNrOfRepetition" 0;
BA_DEF_DEF_  "GenMsgILSupport" "Yes";
BA_DEF_DEF_  "GenMsgDelayTime" 0;
BA_DEF_DEF_  "GenMsgCycleTimeFast" 0;
BA_DEF_DEF_  "GenMsgCycleTime" 0;
BA_DEF_DEF_  "DiagUudtResponse" "false";
BA_DEF_DEF_  "DiagUsdtResponse" "false";
BA_DEF_DEF_  "DiagState" "No";
BA_DEF_DEF_  "DiagResponse" "No";
BA_DEF_DEF_  "DiagRequest" "No";
BA_DEF_DEF_  "MsgType" "Application";
BA_DEF_DEF_  "SystemSignalLongSymbol" "";
BA_ "GenMsgCycleTime" BO_ 579 100;
BA_ "GenMsgCycleTime" BO_ 273 10;
BA_ "GenMsgCycleTime" BO_ 192 10;
BA_ "MessageTimeout" BO_ 256 0;
BA_ "GenMsgSendType" BO_ 256 8;
BA_ "MessageTimeout" BO_ 257 0;
BA_ "GenMsgSendType" BO_ 257 8;
BA_ "GenMsgNrOfRepetition" BO_ 259 4;
BA_ "GenMsgCycleTimeFast" BO_ 259 20;
BA_ "GenMsgCycleTime" BO_ 259 100;
BA_ "GenMsgCycleTime" BO_ 260 10;
BA_ "GenMsgStartDelayTime" BO_ 262 3;
BA_ "GenMsgCycleTime" BO_ 262 10;
BA_ "GenMsgStartDelayTime" BO_ 264 6;
BA_ "GenMsgCycleTime" BO_ 264 10;
BA_ "GenMsgCycleTime" BO_ 266 10;
BA_ "GenMsgCycleTime" BO_ 268 10;
BA_ "GenMsgCycleTime" BO_ 270 10;
BA_ "GenMsgCycleTime" BO_ 277 10;
BA_ "GenMsgCycleTime" BO_ 279 10;
BA_ "GenMsgCycleTime" BO_ 288 10;
BA_ "GenMsgStartDelayTime" BO_ 290 5;
BA_ "GenMsgCycleTime" BO_ 290 10;
BA_ "GenMsgCycleTime" BO_ 291 10;
BA_ "GenMsgCycleTime" BO_ 383 20;
BA_ "GenMsgCycleTime" BO_ 294 10;
BA_ "GenMsgCycleTime" BO_ 296 10;
BA_ "GenMsgCycleTime" BO_ 298 10;
BA_ "GenMsgCycleTime" BO_ 300 10;
BA_ "GenMsgStartDelayTime" BO_ 352 9;
BA_ "GenMsgCycleTime" BO_ 352 20;
BA_ "GenMsgCycleTime" BO_ 356 20;
BA_ "GenMsgCycleTime" BO_ 359 20;
BA_ "GenMsgCycleTime" BO_ 368 20;
BA_ "GenSigSendType" SG_ 579 VcuHazardLampReqStatus 7;
BA_ "GenSigCycleTimeActive" SG_ 579 VcuHazardLampReqStatus 100;
BA_ "GenSigCycleTime" SG_ 579 VcuHazardLampReqStatus 100;
BA_ "GenSigSendType" SG_ 579 VcuHazardLampReq 7;
BA_ "GenSigCycleTimeActive" SG_ 579 VcuHazardLampReq 100;
BA_ "GenSigCycleTime" SG_ 579 VcuHazardLampReq 100;
BA_ "GenSigSendType" SG_ 579 VCuPresence 7;
BA_ "GenSigCycleTimeActive" SG_ 579 VCuPresence 100;
BA_ "GenSigCycleTime" SG_ 579 VCuPresence 100;
BA_ "GenSigTimeoutTime_HU_Mid_X451" SG_ 579 BrkVacPumpStatus 0;
BA_ "GenSigTimeoutTime_HU_High_X451" SG_ 579 BrkVacPumpStatus 0;
BA_ "GenSigTimeoutTime_HU_B" SG_ 579 BrkVacPumpStatus 0;
BA_ "GenSigTimeoutTime_HU_A" SG_ 579 BrkVacPumpStatus 0;
BA_ "GenSigTimeoutMsg_HU_Mid_X451" SG_ 579 BrkVacPumpStatus 0;
BA_ "GenSigTimeoutMsg_HU_High_X451" SG_ 579 BrkVacPumpStatus 0;
BA_ "GenSigTimeoutMsg_HU_B" SG_ 579 BrkVacPumpStatus 0;
BA_ "GenSigTimeoutMsg_HU_A" SG_ 579 BrkVacPumpStatus 0;
BA_ "GenSigSendType" SG_ 579 BrkVacPumpStatus 7;
BA_ "GenSigCycleTimeActive" SG_ 579 BrkVacPumpStatus 100;
BA_ "GenSigCycleTime" SG_ 579 BrkVacPumpStatus 100;
BA_ "GenSigTimeoutMsg_HU_High_X445" SG_ 579 BrkVacPumpStatus 0;
BA_ "GenSigTimeoutMsg_HU_Mid_X445" SG_ 579 BrkVacPumpStatus 0;
BA_ "GenSigTimeoutTime_HU_High_X445" SG_ 579 BrkVacPumpStatus 0;
BA_ "GenSigTimeoutTime_HU_Mid_X445" SG_ 579 BrkVacPumpStatus 0;
BA_ "GenSigSendType" SG_ 579 DriveMotorStatus 7;
BA_ "GenSigCycleTimeActive" SG_ 579 DriveMotorStatus 100;
BA_ "GenSigCycleTime" SG_ 579 DriveMotorStatus 100;
BA_ "GenSigSendType" SG_ 579 HvBattSoh 7;
BA_ "GenSigCycleTimeActive" SG_ 579 HvBattSoh 100;
BA_ "GenSigCycleTime" SG_ 579 HvBattSoh 100;
BA_ "GenSigTimeoutTime_HU_Mid_X451" SG_ 579 RegenAmpHr 0;
BA_ "GenSigTimeoutTime_HU_High_X451" SG_ 579 RegenAmpHr 0;
BA_ "GenSigTimeoutTime_HU_B" SG_ 579 RegenAmpHr 0;
BA_ "GenSigTimeoutTime_HU_A" SG_ 579 RegenAmpHr 0;
BA_ "GenSigTimeoutMsg_HU_Mid_X451" SG_ 579 RegenAmpHr 0;
BA_ "GenSigTimeoutMsg_HU_High_X451" SG_ 579 RegenAmpHr 0;
BA_ "GenSigTimeoutMsg_HU_B" SG_ 579 RegenAmpHr 0;
BA_ "GenSigTimeoutMsg_HU_A" SG_ 579 RegenAmpHr 0;
BA_ "GenSigSendType" SG_ 579 RegenAmpHr 7;
BA_ "GenSigCycleTimeActive" SG_ 579 RegenAmpHr 100;
BA_ "GenSigCycleTime" SG_ 579 RegenAmpHr 100;
BA_ "GenSigTimeoutMsg_HU_High_X445" SG_ 579 RegenAmpHr 0;
BA_ "GenSigTimeoutMsg_HU_Mid_X445" SG_ 579 RegenAmpHr 0;
BA_ "GenSigTimeoutTime_HU_High_X445" SG_ 579 RegenAmpHr 0;
BA_ "GenSigTimeoutTime_HU_Mid_X445" SG_ 579 RegenAmpHr 0;
BA_ "GenSigSendType" SG_ 579 HvBattPackVolStatus 7;
BA_ "GenSigCycleTimeActive" SG_ 579 HvBattPackVolStatus 100;
BA_ "GenSigCycleTime" SG_ 579 HvBattPackVolStatus 100;
BA_ "GenSigSendType" SG_ 579 HvBattPackVol 7;
BA_ "GenSigCycleTimeActive" SG_ 579 HvBattPackVol 100;
BA_ "GenSigCycleTime" SG_ 579 HvBattPackVol 100;
BA_ "GenSigTimeoutTime_HU_Mid_X451" SG_ 579 AvgEnergyConsmption 0;
BA_ "GenSigTimeoutTime_HU_High_X451" SG_ 579 AvgEnergyConsmption 0;
BA_ "GenSigTimeoutTime_HU_B" SG_ 579 AvgEnergyConsmption 0;
BA_ "GenSigTimeoutTime_HU_A" SG_ 579 AvgEnergyConsmption 0;
BA_ "GenSigTimeoutMsg_HU_Mid_X451" SG_ 579 AvgEnergyConsmption 0;
BA_ "GenSigTimeoutMsg_HU_High_X451" SG_ 579 AvgEnergyConsmption 0;
BA_ "GenSigTimeoutMsg_HU_B" SG_ 579 AvgEnergyConsmption 0;
BA_ "GenSigTimeoutMsg_HU_A" SG_ 579 AvgEnergyConsmption 0;
BA_ "GenSigSendType" SG_ 579 AvgEnergyConsmption 7;
BA_ "GenSigCycleTimeActive" SG_ 579 AvgEnergyConsmption 100;
BA_ "GenSigCycleTime" SG_ 579 AvgEnergyConsmption 100;
BA_ "GenSigTimeoutTime_HU_Mid_X451" SG_ 579 AvgEnergyConsmptionStatus 0;
BA_ "GenSigTimeoutTime_HU_High_X451" SG_ 579 AvgEnergyConsmptionStatus 0;
BA_ "GenSigTimeoutTime_HU_B" SG_ 579 AvgEnergyConsmptionStatus 0;
BA_ "GenSigTimeoutTime_HU_A" SG_ 579 AvgEnergyConsmptionStatus 0;
BA_ "GenSigTimeoutMsg_HU_Mid_X451" SG_ 579 AvgEnergyConsmptionStatus 0;
BA_ "GenSigTimeoutMsg_HU_High_X451" SG_ 579 AvgEnergyConsmptionStatus 0;
BA_ "GenSigTimeoutMsg_HU_B" SG_ 579 AvgEnergyConsmptionStatus 0;
BA_ "GenSigTimeoutMsg_HU_A" SG_ 579 AvgEnergyConsmptionStatus 0;
BA_ "GenSigSendType" SG_ 579 AvgEnergyConsmptionStatus 7;
BA_ "GenSigCycleTimeActive" SG_ 579 AvgEnergyConsmptionStatus 100;
BA_ "GenSigCycleTime" SG_ 579 AvgEnergyConsmptionStatus 100;
BA_ "GenSigTimeoutTime_HU_Mid_X451" SG_ 579 MotorHightempStatus 0;
BA_ "GenSigTimeoutTime_HU_High_X451" SG_ 579 MotorHightempStatus 0;
BA_ "GenSigTimeoutTime_HU_B" SG_ 579 MotorHightempStatus 0;
BA_ "GenSigTimeoutTime_HU_A" SG_ 579 MotorHightempStatus 0;
BA_ "GenSigTimeoutMsg_HU_Mid_X451" SG_ 579 MotorHightempStatus 0;
BA_ "GenSigTimeoutMsg_HU_High_X451" SG_ 579 MotorHightempStatus 0;
BA_ "GenSigTimeoutMsg_HU_B" SG_ 579 MotorHightempStatus 0;
BA_ "GenSigTimeoutMsg_HU_A" SG_ 579 MotorHightempStatus 0;
BA_ "GenSigSendType" SG_ 579 MotorHightempStatus 7;
BA_ "GenSigCycleTimeActive" SG_ 579 MotorHightempStatus 100;
BA_ "GenSigCycleTime" SG_ 579 MotorHightempStatus 100;
BA_ "GenSigTimeoutTime_HU_Mid_X451" SG_ 579 MotorHightemp 0;
BA_ "GenSigTimeoutTime_HU_High_X451" SG_ 579 MotorHightemp 0;
BA_ "GenSigTimeoutTime_HU_B" SG_ 579 MotorHightemp 0;
BA_ "GenSigTimeoutTime_HU_A" SG_ 579 MotorHightemp 0;
BA_ "GenSigTimeoutMsg_HU_Mid_X451" SG_ 579 MotorHightemp 0;
BA_ "GenSigTimeoutMsg_HU_High_X451" SG_ 579 MotorHightemp 0;
BA_ "GenSigTimeoutMsg_HU_B" SG_ 579 MotorHightemp 0;
BA_ "GenSigTimeoutMsg_HU_A" SG_ 579 MotorHightemp 0;
BA_ "GenSigSendType" SG_ 579 MotorHightemp 7;
BA_ "GenSigCycleTimeActive" SG_ 579 MotorHightemp 100;
BA_ "GenSigCycleTime" SG_ 579 MotorHightemp 100;
BA_ "GenSigTimeoutTime_HU_Mid_X451" SG_ 579 VcuGearSelectionChangeTxt 0;
BA_ "GenSigTimeoutTime_HU_High_X451" SG_ 579 VcuGearSelectionChangeTxt 0;
BA_ "GenSigTimeoutTime_HU_B" SG_ 579 VcuGearSelectionChangeTxt 0;
BA_ "GenSigTimeoutTime_HU_A" SG_ 579 VcuGearSelectionChangeTxt 0;
BA_ "GenSigTimeoutMsg_HU_Mid_X451" SG_ 579 VcuGearSelectionChangeTxt 0;
BA_ "GenSigTimeoutMsg_HU_High_X451" SG_ 579 VcuGearSelectionChangeTxt 0;
BA_ "GenSigTimeoutMsg_HU_B" SG_ 579 VcuGearSelectionChangeTxt 0;
BA_ "GenSigTimeoutMsg_HU_A" SG_ 579 VcuGearSelectionChangeTxt 0;
BA_ "GenSigStartValue" SG_ 579 VcuGearSelectionChangeTxt 1;
BA_ "GenSigSendType" SG_ 579 VcuGearSelectionChangeTxt 7;
BA_ "GenSigCycleTimeActive" SG_ 579 VcuGearSelectionChangeTxt 100;
BA_ "GenSigCycleTime" SG_ 579 VcuGearSelectionChangeTxt 100;
BA_ "GenSigTimeoutTime_HU_Mid_X451" SG_ 579 ImmoStatusVcu 0;
BA_ "GenSigTimeoutTime_HU_High_X451" SG_ 579 ImmoStatusVcu 0;
BA_ "GenSigTimeoutTime_HU_B" SG_ 579 ImmoStatusVcu 0;
BA_ "GenSigTimeoutTime_HU_A" SG_ 579 ImmoStatusVcu 0;
BA_ "GenSigTimeoutMsg_HU_Mid_X451" SG_ 579 ImmoStatusVcu 0;
BA_ "GenSigTimeoutMsg_HU_High_X451" SG_ 579 ImmoStatusVcu 0;
BA_ "GenSigTimeoutMsg_HU_B" SG_ 579 ImmoStatusVcu 0;
BA_ "GenSigTimeoutMsg_HU_A" SG_ 579 ImmoStatusVcu 0;
BA_ "GenSigSendType" SG_ 579 ImmoStatusVcu 7;
BA_ "GenSigCycleTimeActive" SG_ 579 ImmoStatusVcu 100;
BA_ "GenSigCycleTime" SG_ 579 ImmoStatusVcu 100;
BA_ "GenSigTimeoutTime_HU_Mid_X451" SG_ 579 ClntTempVcuStatus 0;
BA_ "GenSigTimeoutTime_HU_High_X451" SG_ 579 ClntTempVcuStatus 0;
BA_ "GenSigTimeoutTime_HU_B" SG_ 579 ClntTempVcuStatus 0;
BA_ "GenSigTimeoutTime_HU_A" SG_ 579 ClntTempVcuStatus 0;
BA_ "GenSigTimeoutMsg_HU_Mid_X451" SG_ 579 ClntTempVcuStatus 0;
BA_ "GenSigTimeoutMsg_HU_High_X451" SG_ 579 ClntTempVcuStatus 0;
BA_ "GenSigTimeoutMsg_HU_B" SG_ 579 ClntTempVcuStatus 0;
BA_ "GenSigTimeoutMsg_HU_A" SG_ 579 ClntTempVcuStatus 0;
BA_ "GenSigSendType" SG_ 579 ClntTempVcuStatus 7;
BA_ "GenSigCycleTimeActive" SG_ 579 ClntTempVcuStatus 100;
BA_ "GenSigCycleTime" SG_ 579 ClntTempVcuStatus 100;
BA_ "GenSigTimeoutTime_HU_Mid_X451" SG_ 579 ClntTempVcu 0;
BA_ "GenSigTimeoutTime_HU_High_X451" SG_ 579 ClntTempVcu 0;
BA_ "GenSigTimeoutTime_HU_B" SG_ 579 ClntTempVcu 0;
BA_ "GenSigTimeoutTime_HU_A" SG_ 579 ClntTempVcu 0;
BA_ "GenSigTimeoutMsg_HU_Mid_X451" SG_ 579 ClntTempVcu 0;
BA_ "GenSigTimeoutMsg_HU_High_X451" SG_ 579 ClntTempVcu 0;
BA_ "GenSigTimeoutMsg_HU_B" SG_ 579 ClntTempVcu 0;
BA_ "GenSigTimeoutMsg_HU_A" SG_ 579 ClntTempVcu 0;
BA_ "GenSigStartValue" SG_ 579 ClntTempVcu 10;
BA_ "GenSigSendType" SG_ 579 ClntTempVcu 7;
BA_ "GenSigCycleTimeActive" SG_ 579 ClntTempVcu 100;
BA_ "GenSigCycleTime" SG_ 579 ClntTempVcu 100;
BA_ "GenSigTimeoutTime_HU_Mid_X451" SG_ 579 GearForDisplayVcu 0;
BA_ "GenSigTimeoutTime_HU_High_X451" SG_ 579 GearForDisplayVcu 0;
BA_ "GenSigTimeoutTime_HU_B" SG_ 579 GearForDisplayVcu 0;
BA_ "GenSigTimeoutTime_HU_A" SG_ 579 GearForDisplayVcu 0;
BA_ "GenSigTimeoutMsg_HU_Mid_X451" SG_ 579 GearForDisplayVcu 0;
BA_ "GenSigTimeoutMsg_HU_High_X451" SG_ 579 GearForDisplayVcu 0;
BA_ "GenSigTimeoutMsg_HU_B" SG_ 579 GearForDisplayVcu 0;
BA_ "GenSigTimeoutMsg_HU_A" SG_ 579 GearForDisplayVcu 0;
BA_ "GenSigStartValue" SG_ 579 GearForDisplayVcu 1;
BA_ "GenSigSendType" SG_ 579 GearForDisplayVcu 7;
BA_ "GenSigCycleTimeActive" SG_ 579 GearForDisplayVcu 100;
BA_ "GenSigCycleTime" SG_ 579 GearForDisplayVcu 100;
BA_ "GenSigTimeoutTime_HU_Mid_X451" SG_ 579 GearForDisplayVcuStatus 0;
BA_ "GenSigTimeoutTime_HU_High_X451" SG_ 579 GearForDisplayVcuStatus 0;
BA_ "GenSigTimeoutTime_HU_B" SG_ 579 GearForDisplayVcuStatus 0;
BA_ "GenSigTimeoutTime_HU_A" SG_ 579 GearForDisplayVcuStatus 0;
BA_ "GenSigTimeoutMsg_HU_Mid_X451" SG_ 579 GearForDisplayVcuStatus 0;
BA_ "GenSigTimeoutMsg_HU_High_X451" SG_ 579 GearForDisplayVcuStatus 0;
BA_ "GenSigTimeoutMsg_HU_B" SG_ 579 GearForDisplayVcuStatus 0;
BA_ "GenSigTimeoutMsg_HU_A" SG_ 579 GearForDisplayVcuStatus 0;
BA_ "GenSigSendType" SG_ 579 GearForDisplayVcuStatus 7;
BA_ "GenSigCycleTimeActive" SG_ 579 GearForDisplayVcuStatus 100;
BA_ "GenSigCycleTime" SG_ 579 GearForDisplayVcuStatus 100;
BA_ "GenSigTimeoutTime_HU_Mid_X451" SG_ 273 CurrentTorqueAtMotorStatus 0;
BA_ "GenSigTimeoutTime_HU_High_X451" SG_ 273 CurrentTorqueAtMotorStatus 0;
BA_ "GenSigTimeoutTime_HU_B" SG_ 273 CurrentTorqueAtMotorStatus 0;
BA_ "GenSigTimeoutTime_HU_A" SG_ 273 CurrentTorqueAtMotorStatus 0;
BA_ "GenSigTimeoutMsg_HU_Mid_X451" SG_ 273 CurrentTorqueAtMotorStatus 0;
BA_ "GenSigTimeoutMsg_HU_High_X451" SG_ 273 CurrentTorqueAtMotorStatus 0;
BA_ "GenSigTimeoutMsg_HU_B" SG_ 273 CurrentTorqueAtMotorStatus 0;
BA_ "GenSigTimeoutMsg_HU_A" SG_ 273 CurrentTorqueAtMotorStatus 0;
BA_ "GenSigSendType" SG_ 273 CurrentTorqueAtMotorStatus 7;
BA_ "GenSigCycleTimeActive" SG_ 273 CurrentTorqueAtMotorStatus 10;
BA_ "GenSigCycleTime" SG_ 273 CurrentTorqueAtMotorStatus 10;
BA_ "GenSigTimeoutTime_HU_Mid_X451" SG_ 273 CurrentTorqueAtMotor 0;
BA_ "GenSigTimeoutTime_HU_High_X451" SG_ 273 CurrentTorqueAtMotor 0;
BA_ "GenSigTimeoutTime_HU_B" SG_ 273 CurrentTorqueAtMotor 0;
BA_ "GenSigTimeoutTime_HU_A" SG_ 273 CurrentTorqueAtMotor 0;
BA_ "GenSigTimeoutMsg_HU_Mid_X451" SG_ 273 CurrentTorqueAtMotor 0;
BA_ "GenSigTimeoutMsg_HU_High_X451" SG_ 273 CurrentTorqueAtMotor 0;
BA_ "GenSigTimeoutMsg_HU_B" SG_ 273 CurrentTorqueAtMotor 0;
BA_ "GenSigTimeoutMsg_HU_A" SG_ 273 CurrentTorqueAtMotor 0;
BA_ "GenSigStartValue" SG_ 273 CurrentTorqueAtMotor 8192;
BA_ "GenSigSendType" SG_ 273 CurrentTorqueAtMotor 7;
BA_ "GenSigCycleTimeActive" SG_ 273 CurrentTorqueAtMotor 10;
BA_ "GenSigCycleTime" SG_ 273 CurrentTorqueAtMotor 10;
BA_ "GenSigTimeoutTime_HU_Mid_X451" SG_ 273 RecuprationActualTorqueStatus 0;
BA_ "GenSigTimeoutTime_HU_High_X451" SG_ 273 RecuprationActualTorqueStatus 0;
BA_ "GenSigTimeoutTime_HU_B" SG_ 273 RecuprationActualTorqueStatus 0;
BA_ "GenSigTimeoutTime_HU_A" SG_ 273 RecuprationActualTorqueStatus 0;
BA_ "GenSigTimeoutMsg_HU_Mid_X451" SG_ 273 RecuprationActualTorqueStatus 0;
BA_ "GenSigTimeoutMsg_HU_High_X451" SG_ 273 RecuprationActualTorqueStatus 0;
BA_ "GenSigTimeoutMsg_HU_B" SG_ 273 RecuprationActualTorqueStatus 0;
BA_ "GenSigTimeoutMsg_HU_A" SG_ 273 RecuprationActualTorqueStatus 0;
BA_ "GenSigSendType" SG_ 273 RecuprationActualTorqueStatus 7;
BA_ "GenSigCycleTimeActive" SG_ 273 RecuprationActualTorqueStatus 10;
BA_ "GenSigCycleTime" SG_ 273 RecuprationActualTorqueStatus 10;
BA_ "GenSigTimeoutTime_HU_Mid_X451" SG_ 273 RecuprationActualTorque 0;
BA_ "GenSigTimeoutTime_HU_High_X451" SG_ 273 RecuprationActualTorque 0;
BA_ "GenSigTimeoutTime_HU_B" SG_ 273 RecuprationActualTorque 0;
BA_ "GenSigTimeoutTime_HU_A" SG_ 273 RecuprationActualTorque 0;
BA_ "GenSigTimeoutMsg_HU_Mid_X451" SG_ 273 RecuprationActualTorque 0;
BA_ "GenSigTimeoutMsg_HU_High_X451" SG_ 273 RecuprationActualTorque 0;
BA_ "GenSigTimeoutMsg_HU_B" SG_ 273 RecuprationActualTorque 0;
BA_ "GenSigTimeoutMsg_HU_A" SG_ 273 RecuprationActualTorque 0;
BA_ "GenSigStartValue" SG_ 273 RecuprationActualTorque 8192;
BA_ "GenSigSendType" SG_ 273 RecuprationActualTorque 7;
BA_ "GenSigCycleTimeActive" SG_ 273 RecuprationActualTorque 10;
BA_ "GenSigCycleTime" SG_ 273 RecuprationActualTorque 10;
BA_ "GenSigTimeoutTime_HU_Mid_X451" SG_ 273 CurrentTorqueToWheelStatus 0;
BA_ "GenSigTimeoutTime_HU_High_X451" SG_ 273 CurrentTorqueToWheelStatus 0;
BA_ "GenSigTimeoutTime_HU_B" SG_ 273 CurrentTorqueToWheelStatus 0;
BA_ "GenSigTimeoutTime_HU_A" SG_ 273 CurrentTorqueToWheelStatus 0;
BA_ "GenSigTimeoutMsg_HU_Mid_X451" SG_ 273 CurrentTorqueToWheelStatus 0;
BA_ "GenSigTimeoutMsg_HU_High_X451" SG_ 273 CurrentTorqueToWheelStatus 0;
BA_ "GenSigTimeoutMsg_HU_B" SG_ 273 CurrentTorqueToWheelStatus 0;
BA_ "GenSigTimeoutMsg_HU_A" SG_ 273 CurrentTorqueToWheelStatus 0;
BA_ "GenSigSendType" SG_ 273 CurrentTorqueToWheelStatus 7;
BA_ "GenSigCycleTimeActive" SG_ 273 CurrentTorqueToWheelStatus 10;
BA_ "GenSigCycleTime" SG_ 273 CurrentTorqueToWheelStatus 10;
BA_ "GenSigTimeoutTime_HU_Mid_X451" SG_ 273 CurrentTorqueToWheel 0;
BA_ "GenSigTimeoutTime_HU_High_X451" SG_ 273 CurrentTorqueToWheel 0;
BA_ "GenSigTimeoutTime_HU_B" SG_ 273 CurrentTorqueToWheel 0;
BA_ "GenSigTimeoutTime_HU_A" SG_ 273 CurrentTorqueToWheel 0;
BA_ "GenSigTimeoutMsg_HU_Mid_X451" SG_ 273 CurrentTorqueToWheel 0;
BA_ "GenSigTimeoutMsg_HU_High_X451" SG_ 273 CurrentTorqueToWheel 0;
BA_ "GenSigTimeoutMsg_HU_B" SG_ 273 CurrentTorqueToWheel 0;
BA_ "GenSigTimeoutMsg_HU_A" SG_ 273 CurrentTorqueToWheel 0;
BA_ "GenSigStartValue" SG_ 273 CurrentTorqueToWheel 8192;
BA_ "GenSigSendType" SG_ 273 CurrentTorqueToWheel 7;
BA_ "GenSigCycleTimeActive" SG_ 273 CurrentTorqueToWheel 10;
BA_ "GenSigCycleTime" SG_ 273 CurrentTorqueToWheel 10;
BA_ "GenSigTimeoutTime_HU_Mid_X451" SG_ 273 AccPedPosnVcuStatus 0;
BA_ "GenSigTimeoutTime_HU_High_X451" SG_ 273 AccPedPosnVcuStatus 0;
BA_ "GenSigTimeoutTime_HU_B" SG_ 273 AccPedPosnVcuStatus 0;
BA_ "GenSigTimeoutTime_HU_A" SG_ 273 AccPedPosnVcuStatus 0;
BA_ "GenSigTimeoutMsg_HU_Mid_X451" SG_ 273 AccPedPosnVcuStatus 0;
BA_ "GenSigTimeoutMsg_HU_High_X451" SG_ 273 AccPedPosnVcuStatus 0;
BA_ "GenSigTimeoutMsg_HU_B" SG_ 273 AccPedPosnVcuStatus 0;
BA_ "GenSigTimeoutMsg_HU_A" SG_ 273 AccPedPosnVcuStatus 0;
BA_ "GenSigSendType" SG_ 273 AccPedPosnVcuStatus 7;
BA_ "GenSigCycleTimeActive" SG_ 273 AccPedPosnVcuStatus 10;
BA_ "GenSigCycleTime" SG_ 273 AccPedPosnVcuStatus 10;
BA_ "GenSigTimeoutTime_HU_Mid_X451" SG_ 273 AccPedPosnVcu 0;
BA_ "GenSigTimeoutTime_HU_High_X451" SG_ 273 AccPedPosnVcu 0;
BA_ "GenSigTimeoutTime_HU_B" SG_ 273 AccPedPosnVcu 0;
BA_ "GenSigTimeoutTime_HU_A" SG_ 273 AccPedPosnVcu 0;
BA_ "GenSigTimeoutMsg_HU_Mid_X451" SG_ 273 AccPedPosnVcu 0;
BA_ "GenSigTimeoutMsg_HU_High_X451" SG_ 273 AccPedPosnVcu 0;
BA_ "GenSigTimeoutMsg_HU_B" SG_ 273 AccPedPosnVcu 0;
BA_ "GenSigTimeoutMsg_HU_A" SG_ 273 AccPedPosnVcu 0;
BA_ "GenSigSendType" SG_ 273 AccPedPosnVcu 7;
BA_ "GenSigCycleTimeActive" SG_ 273 AccPedPosnVcu 10;
BA_ "GenSigCycleTime" SG_ 273 AccPedPosnVcu 10;
BA_ "GenSigTimeoutTime_HU_Mid_X451" SG_ 273 BrkPressStateVcu 0;
BA_ "GenSigTimeoutTime_HU_High_X451" SG_ 273 BrkPressStateVcu 0;
BA_ "GenSigTimeoutTime_HU_B" SG_ 273 BrkPressStateVcu 0;
BA_ "GenSigStartValue" SG_ 273 BrkPressStateVcu 1;
BA_ "GenSigSendType" SG_ 273 BrkPressStateVcu 7;
BA_ "GenSigCycleTimeActive" SG_ 273 BrkPressStateVcu 10;
BA_ "GenSigCycleTime" SG_ 273 BrkPressStateVcu 10;
BA_ "GenSigSendType" SG_ 273 BrkPressStatusVcu 7;
BA_ "GenSigCycleTimeActive" SG_ 273 BrkPressStatusVcu 10;
BA_ "GenSigCycleTime" SG_ 273 BrkPressStatusVcu 10;
BA_ "GenSigTimeoutTime_HU_B" SG_ 192 SF1_5 0;
BA_ "GenSigTimeoutTime_HU_A" SG_ 192 SF1_5 0;
BA_ "GenSigTimeoutMsg_HU_B" SG_ 192 SF1_5 0;
BA_ "GenSigTimeoutMsg_HU_A" SG_ 192 SF1_5 0;
BA_ "GenSigSendType" SG_ 192 SF1_5 7;
BA_ "GenSigCycleTimeActive" SG_ 192 SF1_5 10;
BA_ "GenSigCycleTime" SG_ 192 SF1_5 10;
BA_ "GenSigTimeoutTime_HU_B" SG_ 192 TRIM 0;
BA_ "GenSigTimeoutTime_HU_A" SG_ 192 TRIM 0;
BA_ "GenSigTimeoutMsg_HU_B" SG_ 192 TRIM 0;
BA_ "GenSigTimeoutMsg_HU_A" SG_ 192 TRIM 0;
BA_ "GenSigStartValue" SG_ 192 TRIM 1;
BA_ "GenSigSendType" SG_ 192 TRIM 7;
BA_ "GenSigCycleTimeActive" SG_ 192 TRIM 10;
BA_ "GenSigCycleTime" SG_ 192 TRIM 10;
BA_ "GenSigSendType" SG_ 192 LWS_ANGLE 7;
BA_ "GenSigCycleTimeActive" SG_ 192 LWS_ANGLE 10;
BA_ "GenSigCycleTime" SG_ 192 LWS_ANGLE 10;
BA_ "GenSigTimeoutTime_HU_B" SG_ 192 LWS_SPEED 0;
BA_ "GenSigTimeoutTime_HU_A" SG_ 192 LWS_SPEED 0;
BA_ "GenSigTimeoutMsg_HU_B" SG_ 192 LWS_SPEED 0;
BA_ "GenSigTimeoutMsg_HU_A" SG_ 192 LWS_SPEED 0;
BA_ "GenSigSendType" SG_ 192 LWS_SPEED 7;
BA_ "GenSigCycleTimeActive" SG_ 192 LWS_SPEED 10;
BA_ "GenSigCycleTime" SG_ 192 LWS_SPEED 10;
BA_ "GenSigTimeoutTime_HU_B" SG_ 192 CHK_SUM 0;
BA_ "GenSigTimeoutTime_HU_A" SG_ 192 CHK_SUM 0;
BA_ "GenSigTimeoutMsg_HU_B" SG_ 192 CHK_SUM 0;
BA_ "GenSigTimeoutMsg_HU_A" SG_ 192 CHK_SUM 0;
BA_ "GenSigSendType" SG_ 192 CHK_SUM 7;
BA_ "GenSigCycleTimeActive" SG_ 192 CHK_SUM 10;
BA_ "GenSigCycleTime" SG_ 192 CHK_SUM 10;
BA_ "GenSigTimeoutTime_HU_B" SG_ 192 MSG_CNT 0;
BA_ "GenSigTimeoutTime_HU_A" SG_ 192 MSG_CNT 0;
BA_ "GenSigTimeoutMsg_HU_B" SG_ 192 MSG_CNT 0;
BA_ "GenSigTimeoutMsg_HU_A" SG_ 192 MSG_CNT 0;
BA_ "GenSigSendType" SG_ 192 MSG_CNT 7;
BA_ "GenSigCycleTimeActive" SG_ 192 MSG_CNT 10;
BA_ "GenSigCycleTime" SG_ 192 MSG_CNT 10;
BA_ "GenSigTimeoutTime_HU_B" SG_ 192 OK 0;
BA_ "GenSigTimeoutTime_HU_A" SG_ 192 OK 0;
BA_ "GenSigTimeoutMsg_HU_B" SG_ 192 OK 0;
BA_ "GenSigTimeoutMsg_HU_A" SG_ 192 OK 0;
BA_ "GenSigSendType" SG_ 192 OK 7;
BA_ "GenSigCycleTimeActive" SG_ 192 OK 10;
BA_ "GenSigCycleTime" SG_ 192 OK 10;
BA_ "GenSigTimeoutTime_HU_B" SG_ 192 CAL 0;
BA_ "GenSigTimeoutTime_HU_A" SG_ 192 CAL 0;
BA_ "GenSigTimeoutMsg_HU_B" SG_ 192 CAL 0;
BA_ "GenSigTimeoutMsg_HU_A" SG_ 192 CAL 0;
BA_ "GenSigSendType" SG_ 192 CAL 7;
BA_ "GenSigCycleTimeActive" SG_ 192 CAL 10;
BA_ "GenSigCycleTime" SG_ 192 CAL 10;
BA_ "GenSigTimeoutTime_HU_Mid_X451" SG_ 256 Reserved_101 0;
BA_ "GenSigTimeoutTime_HU_High_X451" SG_ 256 Reserved_101 0;
BA_ "GenSigTimeoutTime_HU_B" SG_ 256 Reserved_101 0;
BA_ "GenSigTimeoutTime_HU_A" SG_ 256 Reserved_101 0;
BA_ "GenSigTimeoutMsg_HU_Mid_X451" SG_ 256 Reserved_101 0;
BA_ "GenSigTimeoutMsg_HU_High_X451" SG_ 256 Reserved_101 0;
BA_ "GenSigTimeoutMsg_HU_B" SG_ 256 Reserved_101 0;
BA_ "GenSigTimeoutMsg_HU_A" SG_ 256 Reserved_101 0;
BA_ "GenSigSendType" SG_ 256 Reserved_101 1;
BA_ "GenSigTimeoutMsg_HU_High_X445" SG_ 256 Reserved_101 0;
BA_ "GenSigTimeoutMsg_HU_Mid_X445" SG_ 256 Reserved_101 0;
BA_ "GenSigTimeoutTime_HU_High_X445" SG_ 256 Reserved_101 0;
BA_ "GenSigTimeoutTime_HU_Mid_X445" SG_ 256 Reserved_101 0;
BA_ "GenSigTimeoutMsg_IVI" SG_ 256 Reserved_101 0;
BA_ "GenSigTimeoutTime_IVI" SG_ 256 Reserved_101 0;
BA_ "GenSigTimeoutTime_HU_Mid_X451" SG_ 256 MCU_LOCK_STATUS 0;
BA_ "GenSigTimeoutTime_HU_High_X451" SG_ 256 MCU_LOCK_STATUS 0;
BA_ "GenSigTimeoutTime_HU_B" SG_ 256 MCU_LOCK_STATUS 0;
BA_ "GenSigTimeoutTime_HU_A" SG_ 256 MCU_LOCK_STATUS 0;
BA_ "GenSigTimeoutMsg_HU_Mid_X451" SG_ 256 MCU_LOCK_STATUS 0;
BA_ "GenSigTimeoutMsg_HU_High_X451" SG_ 256 MCU_LOCK_STATUS 0;
BA_ "GenSigTimeoutMsg_HU_B" SG_ 256 MCU_LOCK_STATUS 0;
BA_ "GenSigTimeoutMsg_HU_A" SG_ 256 MCU_LOCK_STATUS 0;
BA_ "GenSigSendType" SG_ 256 MCU_LOCK_STATUS 1;
BA_ "GenSigTimeoutMsg_HU_High_X445" SG_ 256 MCU_LOCK_STATUS 0;
BA_ "GenSigTimeoutMsg_HU_Mid_X445" SG_ 256 MCU_LOCK_STATUS 0;
BA_ "GenSigTimeoutTime_HU_High_X445" SG_ 256 MCU_LOCK_STATUS 0;
BA_ "GenSigTimeoutTime_HU_Mid_X445" SG_ 256 MCU_LOCK_STATUS 0;
BA_ "GenSigTimeoutMsg_IVI" SG_ 256 MCU_LOCK_STATUS 0;
BA_ "GenSigTimeoutTime_IVI" SG_ 256 MCU_LOCK_STATUS 0;
BA_ "GenSigTimeoutTime_HU_Mid_X451" SG_ 256 MCU_KEY_REQUEST 0;
BA_ "GenSigTimeoutTime_HU_High_X451" SG_ 256 MCU_KEY_REQUEST 0;
BA_ "GenSigTimeoutTime_HU_B" SG_ 256 MCU_KEY_REQUEST 0;
BA_ "GenSigTimeoutTime_HU_A" SG_ 256 MCU_KEY_REQUEST 0;
BA_ "GenSigTimeoutMsg_HU_Mid_X451" SG_ 256 MCU_KEY_REQUEST 0;
BA_ "GenSigTimeoutMsg_HU_High_X451" SG_ 256 MCU_KEY_REQUEST 0;
BA_ "GenSigTimeoutMsg_HU_B" SG_ 256 MCU_KEY_REQUEST 0;
BA_ "GenSigTimeoutMsg_HU_A" SG_ 256 MCU_KEY_REQUEST 0;
BA_ "GenSigSendType" SG_ 256 MCU_KEY_REQUEST 1;
BA_ "GenSigTimeoutMsg_HU_High_X445" SG_ 256 MCU_KEY_REQUEST 0;
BA_ "GenSigTimeoutMsg_HU_Mid_X445" SG_ 256 MCU_KEY_REQUEST 0;
BA_ "GenSigTimeoutTime_HU_High_X445" SG_ 256 MCU_KEY_REQUEST 0;
BA_ "GenSigTimeoutTime_HU_Mid_X445" SG_ 256 MCU_KEY_REQUEST 0;
BA_ "GenSigTimeoutMsg_IVI" SG_ 256 MCU_KEY_REQUEST 0;
BA_ "GenSigTimeoutTime_IVI" SG_ 256 MCU_KEY_REQUEST 0;
BA_ "GenSigTimeoutTime_HU_Mid_X451" SG_ 256 MCU_INTERN_STATUS 0;
BA_ "GenSigTimeoutTime_HU_High_X451" SG_ 256 MCU_INTERN_STATUS 0;
BA_ "GenSigTimeoutTime_HU_B" SG_ 256 MCU_INTERN_STATUS 0;
BA_ "GenSigTimeoutTime_HU_A" SG_ 256 MCU_INTERN_STATUS 0;
BA_ "GenSigTimeoutMsg_HU_Mid_X451" SG_ 256 MCU_INTERN_STATUS 0;
BA_ "GenSigTimeoutMsg_HU_High_X451" SG_ 256 MCU_INTERN_STATUS 0;
BA_ "GenSigTimeoutMsg_HU_B" SG_ 256 MCU_INTERN_STATUS 0;
BA_ "GenSigTimeoutMsg_HU_A" SG_ 256 MCU_INTERN_STATUS 0;
BA_ "GenSigSendType" SG_ 256 MCU_INTERN_STATUS 1;
BA_ "GenSigTimeoutMsg_HU_High_X445" SG_ 256 MCU_INTERN_STATUS 0;
BA_ "GenSigTimeoutMsg_HU_Mid_X445" SG_ 256 MCU_INTERN_STATUS 0;
BA_ "GenSigTimeoutTime_HU_High_X445" SG_ 256 MCU_INTERN_STATUS 0;
BA_ "GenSigTimeoutTime_HU_Mid_X445" SG_ 256 MCU_INTERN_STATUS 0;
BA_ "GenSigTimeoutMsg_IVI" SG_ 256 MCU_INTERN_STATUS 0;
BA_ "GenSigTimeoutTime_IVI" SG_ 256 MCU_INTERN_STATUS 0;
BA_ "GenSigTimeoutTime_HU_Mid_X451" SG_ 256 MCU_DATA_FIELD 0;
BA_ "GenSigTimeoutTime_HU_High_X451" SG_ 256 MCU_DATA_FIELD 0;
BA_ "GenSigTimeoutTime_HU_B" SG_ 256 MCU_DATA_FIELD 0;
BA_ "GenSigTimeoutTime_HU_A" SG_ 256 MCU_DATA_FIELD 0;
BA_ "GenSigTimeoutMsg_HU_Mid_X451" SG_ 256 MCU_DATA_FIELD 0;
BA_ "GenSigTimeoutMsg_HU_High_X451" SG_ 256 MCU_DATA_FIELD 0;
BA_ "GenSigTimeoutMsg_HU_B" SG_ 256 MCU_DATA_FIELD 0;
BA_ "GenSigTimeoutMsg_HU_A" SG_ 256 MCU_DATA_FIELD 0;
BA_ "GenSigSendType" SG_ 256 MCU_DATA_FIELD 1;
BA_ "GenSigTimeoutMsg_HU_High_X445" SG_ 256 MCU_DATA_FIELD 0;
BA_ "GenSigTimeoutMsg_HU_Mid_X445" SG_ 256 MCU_DATA_FIELD 0;
BA_ "GenSigTimeoutTime_HU_High_X445" SG_ 256 MCU_DATA_FIELD 0;
BA_ "GenSigTimeoutTime_HU_Mid_X445" SG_ 256 MCU_DATA_FIELD 0;
BA_ "GenSigTimeoutMsg_IVI" SG_ 256 MCU_DATA_FIELD 0;
BA_ "GenSigTimeoutTime_IVI" SG_ 256 MCU_DATA_FIELD 0;
BA_ "GenSigTimeoutTime_HU_Mid_X451" SG_ 256 ICU_recog_OK 0;
BA_ "GenSigTimeoutTime_HU_High_X451" SG_ 256 ICU_recog_OK 0;
BA_ "GenSigTimeoutTime_HU_B" SG_ 256 ICU_recog_OK 0;
BA_ "GenSigTimeoutTime_HU_A" SG_ 256 ICU_recog_OK 0;
BA_ "GenSigTimeoutMsg_HU_Mid_X451" SG_ 256 ICU_recog_OK 0;
BA_ "GenSigTimeoutMsg_HU_High_X451" SG_ 256 ICU_recog_OK 0;
BA_ "GenSigTimeoutMsg_HU_B" SG_ 256 ICU_recog_OK 0;
BA_ "GenSigTimeoutMsg_HU_A" SG_ 256 ICU_recog_OK 0;
BA_ "GenSigSendType" SG_ 256 ICU_recog_OK 1;
BA_ "GenSigTimeoutMsg_HU_High_X445" SG_ 256 ICU_recog_OK 0;
BA_ "GenSigTimeoutMsg_HU_Mid_X445" SG_ 256 ICU_recog_OK 0;
BA_ "GenSigTimeoutTime_HU_High_X445" SG_ 256 ICU_recog_OK 0;
BA_ "GenSigTimeoutTime_HU_Mid_X445" SG_ 256 ICU_recog_OK 0;
BA_ "GenSigTimeoutMsg_IVI" SG_ 256 ICU_recog_OK 0;
BA_ "GenSigTimeoutTime_IVI" SG_ 256 ICU_recog_OK 0;
BA_ "GenSigTimeoutTime_HU_Mid_X451" SG_ 256 EMS7_DATA_FIELD_4 0;
BA_ "GenSigTimeoutTime_HU_High_X451" SG_ 256 EMS7_DATA_FIELD_4 0;
BA_ "GenSigTimeoutTime_HU_B" SG_ 256 EMS7_DATA_FIELD_4 0;
BA_ "GenSigTimeoutTime_HU_A" SG_ 256 EMS7_DATA_FIELD_4 0;
BA_ "GenSigTimeoutMsg_HU_Mid_X451" SG_ 256 EMS7_DATA_FIELD_4 0;
BA_ "GenSigTimeoutMsg_HU_High_X451" SG_ 256 EMS7_DATA_FIELD_4 0;
BA_ "GenSigTimeoutMsg_HU_B" SG_ 256 EMS7_DATA_FIELD_4 0;
BA_ "GenSigTimeoutMsg_HU_A" SG_ 256 EMS7_DATA_FIELD_4 0;
BA_ "GenSigSendType" SG_ 256 EMS7_DATA_FIELD_4 1;
BA_ "GenSigTimeoutMsg_HU_High_X445" SG_ 256 EMS7_DATA_FIELD_4 0;
BA_ "GenSigTimeoutMsg_HU_Mid_X445" SG_ 256 EMS7_DATA_FIELD_4 0;
BA_ "GenSigTimeoutTime_HU_High_X445" SG_ 256 EMS7_DATA_FIELD_4 0;
BA_ "GenSigTimeoutTime_HU_Mid_X445" SG_ 256 EMS7_DATA_FIELD_4 0;
BA_ "GenSigTimeoutMsg_IVI" SG_ 256 EMS7_DATA_FIELD_4 0;
BA_ "GenSigTimeoutTime_IVI" SG_ 256 EMS7_DATA_FIELD_4 0;
BA_ "GenSigTimeoutTime_HU_Mid_X451" SG_ 256 EMS7_DATA_FIELD_3 0;
BA_ "GenSigTimeoutTime_HU_High_X451" SG_ 256 EMS7_DATA_FIELD_3 0;
BA_ "GenSigTimeoutTime_HU_B" SG_ 256 EMS7_DATA_FIELD_3 0;
BA_ "GenSigTimeoutTime_HU_A" SG_ 256 EMS7_DATA_FIELD_3 0;
BA_ "GenSigTimeoutMsg_HU_Mid_X451" SG_ 256 EMS7_DATA_FIELD_3 0;
BA_ "GenSigTimeoutMsg_HU_High_X451" SG_ 256 EMS7_DATA_FIELD_3 0;
BA_ "GenSigTimeoutMsg_HU_B" SG_ 256 EMS7_DATA_FIELD_3 0;
BA_ "GenSigTimeoutMsg_HU_A" SG_ 256 EMS7_DATA_FIELD_3 0;
BA_ "GenSigSendType" SG_ 256 EMS7_DATA_FIELD_3 1;
BA_ "GenSigTimeoutMsg_HU_High_X445" SG_ 256 EMS7_DATA_FIELD_3 0;
BA_ "GenSigTimeoutMsg_HU_Mid_X445" SG_ 256 EMS7_DATA_FIELD_3 0;
BA_ "GenSigTimeoutTime_HU_High_X445" SG_ 256 EMS7_DATA_FIELD_3 0;
BA_ "GenSigTimeoutTime_HU_Mid_X445" SG_ 256 EMS7_DATA_FIELD_3 0;
BA_ "GenSigTimeoutMsg_IVI" SG_ 256 EMS7_DATA_FIELD_3 0;
BA_ "GenSigTimeoutTime_IVI" SG_ 256 EMS7_DATA_FIELD_3 0;
BA_ "GenSigTimeoutTime_HU_Mid_X451" SG_ 256 EMS7_DATA_FIELD_2 0;
BA_ "GenSigTimeoutTime_HU_High_X451" SG_ 256 EMS7_DATA_FIELD_2 0;
BA_ "GenSigTimeoutTime_HU_B" SG_ 256 EMS7_DATA_FIELD_2 0;
BA_ "GenSigTimeoutTime_HU_A" SG_ 256 EMS7_DATA_FIELD_2 0;
BA_ "GenSigTimeoutMsg_HU_Mid_X451" SG_ 256 EMS7_DATA_FIELD_2 0;
BA_ "GenSigTimeoutMsg_HU_High_X451" SG_ 256 EMS7_DATA_FIELD_2 0;
BA_ "GenSigTimeoutMsg_HU_B" SG_ 256 EMS7_DATA_FIELD_2 0;
BA_ "GenSigTimeoutMsg_HU_A" SG_ 256 EMS7_DATA_FIELD_2 0;
BA_ "GenSigSendType" SG_ 256 EMS7_DATA_FIELD_2 1;
BA_ "GenSigTimeoutMsg_HU_High_X445" SG_ 256 EMS7_DATA_FIELD_2 0;
BA_ "GenSigTimeoutMsg_HU_Mid_X445" SG_ 256 EMS7_DATA_FIELD_2 0;
BA_ "GenSigTimeoutTime_HU_High_X445" SG_ 256 EMS7_DATA_FIELD_2 0;
BA_ "GenSigTimeoutTime_HU_Mid_X445" SG_ 256 EMS7_DATA_FIELD_2 0;
BA_ "GenSigTimeoutMsg_IVI" SG_ 256 EMS7_DATA_FIELD_2 0;
BA_ "GenSigTimeoutTime_IVI" SG_ 256 EMS7_DATA_FIELD_2 0;
BA_ "GenSigTimeoutTime_HU_Mid_X451" SG_ 256 EMS7_DATA_FIELD_1 0;
BA_ "GenSigTimeoutTime_HU_High_X451" SG_ 256 EMS7_DATA_FIELD_1 0;
BA_ "GenSigTimeoutTime_HU_B" SG_ 256 EMS7_DATA_FIELD_1 0;
BA_ "GenSigTimeoutTime_HU_A" SG_ 256 EMS7_DATA_FIELD_1 0;
BA_ "GenSigTimeoutMsg_HU_Mid_X451" SG_ 256 EMS7_DATA_FIELD_1 0;
BA_ "GenSigTimeoutMsg_HU_High_X451" SG_ 256 EMS7_DATA_FIELD_1 0;
BA_ "GenSigTimeoutMsg_HU_B" SG_ 256 EMS7_DATA_FIELD_1 0;
BA_ "GenSigTimeoutMsg_HU_A" SG_ 256 EMS7_DATA_FIELD_1 0;
BA_ "GenSigSendType" SG_ 256 EMS7_DATA_FIELD_1 1;
BA_ "GenSigTimeoutMsg_HU_High_X445" SG_ 256 EMS7_DATA_FIELD_1 0;
BA_ "GenSigTimeoutMsg_HU_Mid_X445" SG_ 256 EMS7_DATA_FIELD_1 0;
BA_ "GenSigTimeoutTime_HU_High_X445" SG_ 256 EMS7_DATA_FIELD_1 0;
BA_ "GenSigTimeoutTime_HU_Mid_X445" SG_ 256 EMS7_DATA_FIELD_1 0;
BA_ "GenSigTimeoutMsg_IVI" SG_ 256 EMS7_DATA_FIELD_1 0;
BA_ "GenSigTimeoutTime_IVI" SG_ 256 EMS7_DATA_FIELD_1 0;
BA_ "GenSigTimeoutTime_HU_Mid_X451" SG_ 256 EMS7_DATA_FIELD_0 0;
BA_ "GenSigTimeoutTime_HU_High_X451" SG_ 256 EMS7_DATA_FIELD_0 0;
BA_ "GenSigTimeoutTime_HU_B" SG_ 256 EMS7_DATA_FIELD_0 0;
BA_ "GenSigTimeoutTime_HU_A" SG_ 256 EMS7_DATA_FIELD_0 0;
BA_ "GenSigTimeoutMsg_HU_Mid_X451" SG_ 256 EMS7_DATA_FIELD_0 0;
BA_ "GenSigTimeoutMsg_HU_High_X451" SG_ 256 EMS7_DATA_FIELD_0 0;
BA_ "GenSigTimeoutMsg_HU_B" SG_ 256 EMS7_DATA_FIELD_0 0;
BA_ "GenSigTimeoutMsg_HU_A" SG_ 256 EMS7_DATA_FIELD_0 0;
BA_ "GenSigSendType" SG_ 256 EMS7_DATA_FIELD_0 1;
BA_ "GenSigTimeoutMsg_HU_High_X445" SG_ 256 EMS7_DATA_FIELD_0 0;
BA_ "GenSigTimeoutMsg_HU_Mid_X445" SG_ 256 EMS7_DATA_FIELD_0 0;
BA_ "GenSigTimeoutTime_HU_High_X445" SG_ 256 EMS7_DATA_FIELD_0 0;
BA_ "GenSigTimeoutTime_HU_Mid_X445" SG_ 256 EMS7_DATA_FIELD_0 0;
BA_ "GenSigTimeoutMsg_IVI" SG_ 256 EMS7_DATA_FIELD_0 0;
BA_ "GenSigTimeoutTime_IVI" SG_ 256 EMS7_DATA_FIELD_0 0;
BA_ "GenSigTimeoutTime_HU_Mid_X451" SG_ 256 Automatic_AES_Key_write 0;
BA_ "GenSigTimeoutTime_HU_High_X451" SG_ 256 Automatic_AES_Key_write 0;
BA_ "GenSigTimeoutTime_HU_B" SG_ 256 Automatic_AES_Key_write 0;
BA_ "GenSigTimeoutTime_HU_A" SG_ 256 Automatic_AES_Key_write 0;
BA_ "GenSigTimeoutMsg_HU_Mid_X451" SG_ 256 Automatic_AES_Key_write 0;
BA_ "GenSigTimeoutMsg_HU_High_X451" SG_ 256 Automatic_AES_Key_write 0;
BA_ "GenSigTimeoutMsg_HU_B" SG_ 256 Automatic_AES_Key_write 0;
BA_ "GenSigTimeoutMsg_HU_A" SG_ 256 Automatic_AES_Key_write 0;
BA_ "GenSigSendType" SG_ 256 Automatic_AES_Key_write 1;
BA_ "GenSigTimeoutMsg_HU_High_X445" SG_ 256 Automatic_AES_Key_write 0;
BA_ "GenSigTimeoutMsg_HU_Mid_X445" SG_ 256 Automatic_AES_Key_write 0;
BA_ "GenSigTimeoutTime_HU_High_X445" SG_ 256 Automatic_AES_Key_write 0;
BA_ "GenSigTimeoutTime_HU_Mid_X445" SG_ 256 Automatic_AES_Key_write 0;
BA_ "GenSigTimeoutMsg_IVI" SG_ 256 Automatic_AES_Key_write 0;
BA_ "GenSigTimeoutTime_IVI" SG_ 256 Automatic_AES_Key_write 0;
BA_ "GenSigTimeoutTime_HU_Mid_X451" SG_ 256 Automatic_AES_Key_Sequence 0;
BA_ "GenSigTimeoutTime_HU_High_X451" SG_ 256 Automatic_AES_Key_Sequence 0;
BA_ "GenSigTimeoutTime_HU_B" SG_ 256 Automatic_AES_Key_Sequence 0;
BA_ "GenSigTimeoutTime_HU_A" SG_ 256 Automatic_AES_Key_Sequence 0;
BA_ "GenSigTimeoutMsg_HU_Mid_X451" SG_ 256 Automatic_AES_Key_Sequence 0;
BA_ "GenSigTimeoutMsg_HU_High_X451" SG_ 256 Automatic_AES_Key_Sequence 0;
BA_ "GenSigTimeoutMsg_HU_B" SG_ 256 Automatic_AES_Key_Sequence 0;
BA_ "GenSigTimeoutMsg_HU_A" SG_ 256 Automatic_AES_Key_Sequence 0;
BA_ "GenSigSendType" SG_ 256 Automatic_AES_Key_Sequence 1;
BA_ "GenSigTimeoutMsg_HU_High_X445" SG_ 256 Automatic_AES_Key_Sequence 0;
BA_ "GenSigTimeoutMsg_HU_Mid_X445" SG_ 256 Automatic_AES_Key_Sequence 0;
BA_ "GenSigTimeoutTime_HU_High_X445" SG_ 256 Automatic_AES_Key_Sequence 0;
BA_ "GenSigTimeoutTime_HU_Mid_X445" SG_ 256 Automatic_AES_Key_Sequence 0;
BA_ "GenSigTimeoutMsg_IVI" SG_ 256 Automatic_AES_Key_Sequence 0;
BA_ "GenSigTimeoutTime_IVI" SG_ 256 Automatic_AES_Key_Sequence 0;
BA_ "GenSigTimeoutTime_HU_Mid_X451" SG_ 257 VICM1_DATA_FIELD_4 0;
BA_ "GenSigTimeoutTime_HU_High_X451" SG_ 257 VICM1_DATA_FIELD_4 0;
BA_ "GenSigTimeoutTime_HU_B" SG_ 257 VICM1_DATA_FIELD_4 0;
BA_ "GenSigTimeoutTime_HU_A" SG_ 257 VICM1_DATA_FIELD_4 0;
BA_ "GenSigTimeoutMsg_HU_Mid_X451" SG_ 257 VICM1_DATA_FIELD_4 0;
BA_ "GenSigTimeoutMsg_HU_High_X451" SG_ 257 VICM1_DATA_FIELD_4 0;
BA_ "GenSigTimeoutMsg_HU_B" SG_ 257 VICM1_DATA_FIELD_4 0;
BA_ "GenSigTimeoutMsg_HU_A" SG_ 257 VICM1_DATA_FIELD_4 0;
BA_ "GenSigSendType" SG_ 257 VICM1_DATA_FIELD_4 1;
BA_ "GenSigTimeoutMsg_HU_High_X445" SG_ 257 VICM1_DATA_FIELD_4 0;
BA_ "GenSigTimeoutMsg_HU_Mid_X445" SG_ 257 VICM1_DATA_FIELD_4 0;
BA_ "GenSigTimeoutTime_HU_High_X445" SG_ 257 VICM1_DATA_FIELD_4 0;
BA_ "GenSigTimeoutTime_HU_Mid_X445" SG_ 257 VICM1_DATA_FIELD_4 0;
BA_ "GenSigTimeoutMsg_IVI" SG_ 257 VICM1_DATA_FIELD_4 0;
BA_ "GenSigTimeoutTime_IVI" SG_ 257 VICM1_DATA_FIELD_4 0;
BA_ "GenSigTimeoutTime_HU_Mid_X451" SG_ 257 VICM1_DATA_FIELD_3 0;
BA_ "GenSigTimeoutTime_HU_High_X451" SG_ 257 VICM1_DATA_FIELD_3 0;
BA_ "GenSigTimeoutTime_HU_B" SG_ 257 VICM1_DATA_FIELD_3 0;
BA_ "GenSigTimeoutTime_HU_A" SG_ 257 VICM1_DATA_FIELD_3 0;
BA_ "GenSigTimeoutMsg_HU_Mid_X451" SG_ 257 VICM1_DATA_FIELD_3 0;
BA_ "GenSigTimeoutMsg_HU_High_X451" SG_ 257 VICM1_DATA_FIELD_3 0;
BA_ "GenSigTimeoutMsg_HU_B" SG_ 257 VICM1_DATA_FIELD_3 0;
BA_ "GenSigTimeoutMsg_HU_A" SG_ 257 VICM1_DATA_FIELD_3 0;
BA_ "GenSigSendType" SG_ 257 VICM1_DATA_FIELD_3 1;
BA_ "GenSigTimeoutMsg_HU_High_X445" SG_ 257 VICM1_DATA_FIELD_3 0;
BA_ "GenSigTimeoutMsg_HU_Mid_X445" SG_ 257 VICM1_DATA_FIELD_3 0;
BA_ "GenSigTimeoutTime_HU_High_X445" SG_ 257 VICM1_DATA_FIELD_3 0;
BA_ "GenSigTimeoutTime_HU_Mid_X445" SG_ 257 VICM1_DATA_FIELD_3 0;
BA_ "GenSigTimeoutMsg_IVI" SG_ 257 VICM1_DATA_FIELD_3 0;
BA_ "GenSigTimeoutTime_IVI" SG_ 257 VICM1_DATA_FIELD_3 0;
BA_ "GenSigTimeoutTime_HU_Mid_X451" SG_ 257 VICM1_DATA_FIELD_2 0;
BA_ "GenSigTimeoutTime_HU_High_X451" SG_ 257 VICM1_DATA_FIELD_2 0;
BA_ "GenSigTimeoutTime_HU_B" SG_ 257 VICM1_DATA_FIELD_2 0;
BA_ "GenSigTimeoutTime_HU_A" SG_ 257 VICM1_DATA_FIELD_2 0;
BA_ "GenSigTimeoutMsg_HU_Mid_X451" SG_ 257 VICM1_DATA_FIELD_2 0;
BA_ "GenSigTimeoutMsg_HU_High_X451" SG_ 257 VICM1_DATA_FIELD_2 0;
BA_ "GenSigTimeoutMsg_HU_B" SG_ 257 VICM1_DATA_FIELD_2 0;
BA_ "GenSigTimeoutMsg_HU_A" SG_ 257 VICM1_DATA_FIELD_2 0;
BA_ "GenSigSendType" SG_ 257 VICM1_DATA_FIELD_2 1;
BA_ "GenSigTimeoutMsg_HU_High_X445" SG_ 257 VICM1_DATA_FIELD_2 0;
BA_ "GenSigTimeoutMsg_HU_Mid_X445" SG_ 257 VICM1_DATA_FIELD_2 0;
BA_ "GenSigTimeoutTime_HU_High_X445" SG_ 257 VICM1_DATA_FIELD_2 0;
BA_ "GenSigTimeoutTime_HU_Mid_X445" SG_ 257 VICM1_DATA_FIELD_2 0;
BA_ "GenSigTimeoutMsg_IVI" SG_ 257 VICM1_DATA_FIELD_2 0;
BA_ "GenSigTimeoutTime_IVI" SG_ 257 VICM1_DATA_FIELD_2 0;
BA_ "GenSigTimeoutTime_HU_Mid_X451" SG_ 257 VICM1_DATA_FIELD_1 0;
BA_ "GenSigTimeoutTime_HU_High_X451" SG_ 257 VICM1_DATA_FIELD_1 0;
BA_ "GenSigTimeoutTime_HU_B" SG_ 257 VICM1_DATA_FIELD_1 0;
BA_ "GenSigTimeoutTime_HU_A" SG_ 257 VICM1_DATA_FIELD_1 0;
BA_ "GenSigTimeoutMsg_HU_Mid_X451" SG_ 257 VICM1_DATA_FIELD_1 0;
BA_ "GenSigTimeoutMsg_HU_High_X451" SG_ 257 VICM1_DATA_FIELD_1 0;
BA_ "GenSigTimeoutMsg_HU_B" SG_ 257 VICM1_DATA_FIELD_1 0;
BA_ "GenSigTimeoutMsg_HU_A" SG_ 257 VICM1_DATA_FIELD_1 0;
BA_ "GenSigSendType" SG_ 257 VICM1_DATA_FIELD_1 1;
BA_ "GenSigTimeoutMsg_HU_High_X445" SG_ 257 VICM1_DATA_FIELD_1 0;
BA_ "GenSigTimeoutMsg_HU_Mid_X445" SG_ 257 VICM1_DATA_FIELD_1 0;
BA_ "GenSigTimeoutTime_HU_High_X445" SG_ 257 VICM1_DATA_FIELD_1 0;
BA_ "GenSigTimeoutTime_HU_Mid_X445" SG_ 257 VICM1_DATA_FIELD_1 0;
BA_ "GenSigTimeoutMsg_IVI" SG_ 257 VICM1_DATA_FIELD_1 0;
BA_ "GenSigTimeoutTime_IVI" SG_ 257 VICM1_DATA_FIELD_1 0;
BA_ "GenSigTimeoutTime_HU_Mid_X451" SG_ 257 VICM1_DATA_FIELD_0 0;
BA_ "GenSigTimeoutTime_HU_High_X451" SG_ 257 VICM1_DATA_FIELD_0 0;
BA_ "GenSigTimeoutTime_HU_B" SG_ 257 VICM1_DATA_FIELD_0 0;
BA_ "GenSigTimeoutTime_HU_A" SG_ 257 VICM1_DATA_FIELD_0 0;
BA_ "GenSigTimeoutMsg_HU_Mid_X451" SG_ 257 VICM1_DATA_FIELD_0 0;
BA_ "GenSigTimeoutMsg_HU_High_X451" SG_ 257 VICM1_DATA_FIELD_0 0;
BA_ "GenSigTimeoutMsg_HU_B" SG_ 257 VICM1_DATA_FIELD_0 0;
BA_ "GenSigTimeoutMsg_HU_A" SG_ 257 VICM1_DATA_FIELD_0 0;
BA_ "GenSigSendType" SG_ 257 VICM1_DATA_FIELD_0 1;
BA_ "GenSigTimeoutMsg_HU_High_X445" SG_ 257 VICM1_DATA_FIELD_0 0;
BA_ "GenSigTimeoutMsg_HU_Mid_X445" SG_ 257 VICM1_DATA_FIELD_0 0;
BA_ "GenSigTimeoutTime_HU_High_X445" SG_ 257 VICM1_DATA_FIELD_0 0;
BA_ "GenSigTimeoutTime_HU_Mid_X445" SG_ 257 VICM1_DATA_FIELD_0 0;
BA_ "GenSigTimeoutMsg_IVI" SG_ 257 VICM1_DATA_FIELD_0 0;
BA_ "GenSigTimeoutTime_IVI" SG_ 257 VICM1_DATA_FIELD_0 0;
BA_ "GenSigTimeoutTime_HU_Mid_X451" SG_ 257 Reserved_100 0;
BA_ "GenSigTimeoutTime_HU_High_X451" SG_ 257 Reserved_100 0;
BA_ "GenSigTimeoutTime_HU_B" SG_ 257 Reserved_100 0;
BA_ "GenSigTimeoutTime_HU_A" SG_ 257 Reserved_100 0;
BA_ "GenSigTimeoutMsg_HU_Mid_X451" SG_ 257 Reserved_100 0;
BA_ "GenSigTimeoutMsg_HU_High_X451" SG_ 257 Reserved_100 0;
BA_ "GenSigTimeoutMsg_HU_B" SG_ 257 Reserved_100 0;
BA_ "GenSigTimeoutMsg_HU_A" SG_ 257 Reserved_100 0;
BA_ "GenSigSendType" SG_ 257 Reserved_100 1;
BA_ "GenSigTimeoutMsg_HU_High_X445" SG_ 257 Reserved_100 0;
BA_ "GenSigTimeoutMsg_HU_Mid_X445" SG_ 257 Reserved_100 0;
BA_ "GenSigTimeoutTime_HU_High_X445" SG_ 257 Reserved_100 0;
BA_ "GenSigTimeoutTime_HU_Mid_X445" SG_ 257 Reserved_100 0;
BA_ "GenSigTimeoutMsg_IVI" SG_ 257 Reserved_100 0;
BA_ "GenSigTimeoutTime_IVI" SG_ 257 Reserved_100 0;
BA_ "GenSigTimeoutTime_HU_Mid_X451" SG_ 257 MCU_recog_OK 0;
BA_ "GenSigTimeoutTime_HU_High_X451" SG_ 257 MCU_recog_OK 0;
BA_ "GenSigTimeoutTime_HU_B" SG_ 257 MCU_recog_OK 0;
BA_ "GenSigTimeoutTime_HU_A" SG_ 257 MCU_recog_OK 0;
BA_ "GenSigTimeoutMsg_HU_Mid_X451" SG_ 257 MCU_recog_OK 0;
BA_ "GenSigTimeoutMsg_HU_High_X451" SG_ 257 MCU_recog_OK 0;
BA_ "GenSigTimeoutMsg_HU_B" SG_ 257 MCU_recog_OK 0;
BA_ "GenSigTimeoutMsg_HU_A" SG_ 257 MCU_recog_OK 0;
BA_ "GenSigSendType" SG_ 257 MCU_recog_OK 1;
BA_ "GenSigTimeoutMsg_HU_High_X445" SG_ 257 MCU_recog_OK 0;
BA_ "GenSigTimeoutMsg_HU_Mid_X445" SG_ 257 MCU_recog_OK 0;
BA_ "GenSigTimeoutTime_HU_High_X445" SG_ 257 MCU_recog_OK 0;
BA_ "GenSigTimeoutTime_HU_Mid_X445" SG_ 257 MCU_recog_OK 0;
BA_ "GenSigTimeoutMsg_IVI" SG_ 257 MCU_recog_OK 0;
BA_ "GenSigTimeoutTime_IVI" SG_ 257 MCU_recog_OK 0;
BA_ "GenSigTimeoutTime_HU_Mid_X451" SG_ 257 MCU_UNLOCK_AUTHORIZED 0;
BA_ "GenSigTimeoutTime_HU_High_X451" SG_ 257 MCU_UNLOCK_AUTHORIZED 0;
BA_ "GenSigTimeoutTime_HU_B" SG_ 257 MCU_UNLOCK_AUTHORIZED 0;
BA_ "GenSigTimeoutTime_HU_A" SG_ 257 MCU_UNLOCK_AUTHORIZED 0;
BA_ "GenSigTimeoutMsg_HU_Mid_X451" SG_ 257 MCU_UNLOCK_AUTHORIZED 0;
BA_ "GenSigTimeoutMsg_HU_High_X451" SG_ 257 MCU_UNLOCK_AUTHORIZED 0;
BA_ "GenSigTimeoutMsg_HU_B" SG_ 257 MCU_UNLOCK_AUTHORIZED 0;
BA_ "GenSigTimeoutMsg_HU_A" SG_ 257 MCU_UNLOCK_AUTHORIZED 0;
BA_ "GenSigSendType" SG_ 257 MCU_UNLOCK_AUTHORIZED 1;
BA_ "GenSigTimeoutMsg_HU_High_X445" SG_ 257 MCU_UNLOCK_AUTHORIZED 0;
BA_ "GenSigTimeoutMsg_HU_Mid_X445" SG_ 257 MCU_UNLOCK_AUTHORIZED 0;
BA_ "GenSigTimeoutTime_HU_High_X445" SG_ 257 MCU_UNLOCK_AUTHORIZED 0;
BA_ "GenSigTimeoutTime_HU_Mid_X445" SG_ 257 MCU_UNLOCK_AUTHORIZED 0;
BA_ "GenSigTimeoutMsg_IVI" SG_ 257 MCU_UNLOCK_AUTHORIZED 0;
BA_ "GenSigTimeoutTime_IVI" SG_ 257 MCU_UNLOCK_AUTHORIZED 0;
BA_ "GenSigTimeoutTime_HU_Mid_X451" SG_ 257 ICU_KEY_NUMBER 0;
BA_ "GenSigTimeoutTime_HU_High_X451" SG_ 257 ICU_KEY_NUMBER 0;
BA_ "GenSigTimeoutTime_HU_B" SG_ 257 ICU_KEY_NUMBER 0;
BA_ "GenSigTimeoutTime_HU_A" SG_ 257 ICU_KEY_NUMBER 0;
BA_ "GenSigTimeoutMsg_HU_Mid_X451" SG_ 257 ICU_KEY_NUMBER 0;
BA_ "GenSigTimeoutMsg_HU_High_X451" SG_ 257 ICU_KEY_NUMBER 0;
BA_ "GenSigTimeoutMsg_HU_B" SG_ 257 ICU_KEY_NUMBER 0;
BA_ "GenSigTimeoutMsg_HU_A" SG_ 257 ICU_KEY_NUMBER 0;
BA_ "GenSigSendType" SG_ 257 ICU_KEY_NUMBER 1;
BA_ "GenSigTimeoutMsg_HU_High_X445" SG_ 257 ICU_KEY_NUMBER 0;
BA_ "GenSigTimeoutMsg_HU_Mid_X445" SG_ 257 ICU_KEY_NUMBER 0;
BA_ "GenSigTimeoutTime_HU_High_X445" SG_ 257 ICU_KEY_NUMBER 0;
BA_ "GenSigTimeoutTime_HU_Mid_X445" SG_ 257 ICU_KEY_NUMBER 0;
BA_ "GenSigTimeoutMsg_IVI" SG_ 257 ICU_KEY_NUMBER 0;
BA_ "GenSigTimeoutTime_IVI" SG_ 257 ICU_KEY_NUMBER 0;
BA_ "GenSigTimeoutTime_HU_Mid_X451" SG_ 257 ICU_KEY_DETECTION 0;
BA_ "GenSigTimeoutTime_HU_High_X451" SG_ 257 ICU_KEY_DETECTION 0;
BA_ "GenSigTimeoutTime_HU_B" SG_ 257 ICU_KEY_DETECTION 0;
BA_ "GenSigTimeoutTime_HU_A" SG_ 257 ICU_KEY_DETECTION 0;
BA_ "GenSigTimeoutMsg_HU_Mid_X451" SG_ 257 ICU_KEY_DETECTION 0;
BA_ "GenSigTimeoutMsg_HU_High_X451" SG_ 257 ICU_KEY_DETECTION 0;
BA_ "GenSigTimeoutMsg_HU_B" SG_ 257 ICU_KEY_DETECTION 0;
BA_ "GenSigTimeoutMsg_HU_A" SG_ 257 ICU_KEY_DETECTION 0;
BA_ "GenSigSendType" SG_ 257 ICU_KEY_DETECTION 1;
BA_ "GenSigTimeoutMsg_HU_High_X445" SG_ 257 ICU_KEY_DETECTION 0;
BA_ "GenSigTimeoutMsg_HU_Mid_X445" SG_ 257 ICU_KEY_DETECTION 0;
BA_ "GenSigTimeoutTime_HU_High_X445" SG_ 257 ICU_KEY_DETECTION 0;
BA_ "GenSigTimeoutTime_HU_Mid_X445" SG_ 257 ICU_KEY_DETECTION 0;
BA_ "GenSigTimeoutMsg_IVI" SG_ 257 ICU_KEY_DETECTION 0;
BA_ "GenSigTimeoutTime_IVI" SG_ 257 ICU_KEY_DETECTION 0;
BA_ "GenSigTimeoutTime_HU_Mid_X451" SG_ 257 ICU_INTERN_STATUS 0;
BA_ "GenSigTimeoutTime_HU_High_X451" SG_ 257 ICU_INTERN_STATUS 0;
BA_ "GenSigTimeoutTime_HU_B" SG_ 257 ICU_INTERN_STATUS 0;
BA_ "GenSigTimeoutTime_HU_A" SG_ 257 ICU_INTERN_STATUS 0;
BA_ "GenSigTimeoutMsg_HU_Mid_X451" SG_ 257 ICU_INTERN_STATUS 0;
BA_ "GenSigTimeoutMsg_HU_High_X451" SG_ 257 ICU_INTERN_STATUS 0;
BA_ "GenSigTimeoutMsg_HU_B" SG_ 257 ICU_INTERN_STATUS 0;
BA_ "GenSigTimeoutMsg_HU_A" SG_ 257 ICU_INTERN_STATUS 0;
BA_ "GenSigSendType" SG_ 257 ICU_INTERN_STATUS 1;
BA_ "GenSigTimeoutMsg_HU_High_X445" SG_ 257 ICU_INTERN_STATUS 0;
BA_ "GenSigTimeoutMsg_HU_Mid_X445" SG_ 257 ICU_INTERN_STATUS 0;
BA_ "GenSigTimeoutTime_HU_High_X445" SG_ 257 ICU_INTERN_STATUS 0;
BA_ "GenSigTimeoutTime_HU_Mid_X445" SG_ 257 ICU_INTERN_STATUS 0;
BA_ "GenSigTimeoutMsg_IVI" SG_ 257 ICU_INTERN_STATUS 0;
BA_ "GenSigTimeoutTime_IVI" SG_ 257 ICU_INTERN_STATUS 0;
BA_ "GenSigTimeoutTime_HU_Mid_X451" SG_ 257 ICU_DATA_FIELD 0;
BA_ "GenSigTimeoutTime_HU_High_X451" SG_ 257 ICU_DATA_FIELD 0;
BA_ "GenSigTimeoutTime_HU_B" SG_ 257 ICU_DATA_FIELD 0;
BA_ "GenSigTimeoutTime_HU_A" SG_ 257 ICU_DATA_FIELD 0;
BA_ "GenSigTimeoutMsg_HU_Mid_X451" SG_ 257 ICU_DATA_FIELD 0;
BA_ "GenSigTimeoutMsg_HU_High_X451" SG_ 257 ICU_DATA_FIELD 0;
BA_ "GenSigTimeoutMsg_HU_B" SG_ 257 ICU_DATA_FIELD 0;
BA_ "GenSigTimeoutMsg_HU_A" SG_ 257 ICU_DATA_FIELD 0;
BA_ "GenSigSendType" SG_ 257 ICU_DATA_FIELD 1;
BA_ "GenSigTimeoutMsg_HU_High_X445" SG_ 257 ICU_DATA_FIELD 0;
BA_ "GenSigTimeoutMsg_HU_Mid_X445" SG_ 257 ICU_DATA_FIELD 0;
BA_ "GenSigTimeoutTime_HU_High_X445" SG_ 257 ICU_DATA_FIELD 0;
BA_ "GenSigTimeoutTime_HU_Mid_X445" SG_ 257 ICU_DATA_FIELD 0;
BA_ "GenSigTimeoutMsg_IVI" SG_ 257 ICU_DATA_FIELD 0;
BA_ "GenSigTimeoutTime_IVI" SG_ 257 ICU_DATA_FIELD 0;
BA_ "GenSigTimeoutTime_HU_Mid_X451" SG_ 257 Automatic_AES_Key_write_ACKLG 0;
BA_ "GenSigTimeoutTime_HU_High_X451" SG_ 257 Automatic_AES_Key_write_ACKLG 0;
BA_ "GenSigTimeoutTime_HU_B" SG_ 257 Automatic_AES_Key_write_ACKLG 0;
BA_ "GenSigTimeoutTime_HU_A" SG_ 257 Automatic_AES_Key_write_ACKLG 0;
BA_ "GenSigTimeoutMsg_HU_Mid_X451" SG_ 257 Automatic_AES_Key_write_ACKLG 0;
BA_ "GenSigTimeoutMsg_HU_High_X451" SG_ 257 Automatic_AES_Key_write_ACKLG 0;
BA_ "GenSigTimeoutMsg_HU_B" SG_ 257 Automatic_AES_Key_write_ACKLG 0;
BA_ "GenSigTimeoutMsg_HU_A" SG_ 257 Automatic_AES_Key_write_ACKLG 0;
BA_ "GenSigSendType" SG_ 257 Automatic_AES_Key_write_ACKLG 1;
BA_ "GenSigTimeoutMsg_HU_High_X445" SG_ 257 Automatic_AES_Key_write_ACKLG 0;
BA_ "GenSigTimeoutMsg_HU_Mid_X445" SG_ 257 Automatic_AES_Key_write_ACKLG 0;
BA_ "GenSigTimeoutTime_HU_High_X445" SG_ 257 Automatic_AES_Key_write_ACKLG 0;
BA_ "GenSigTimeoutTime_HU_Mid_X445" SG_ 257 Automatic_AES_Key_write_ACKLG 0;
BA_ "GenSigTimeoutMsg_IVI" SG_ 257 Automatic_AES_Key_write_ACKLG 0;
BA_ "GenSigTimeoutTime_IVI" SG_ 257 Automatic_AES_Key_write_ACKLG 0;
BA_ "GenSigSendType" SG_ 259 CrashOutputSignalStatus 7;
BA_ "GenSigCycleTimeActive" SG_ 259 CrashOutputSignalStatus 100;
BA_ "GenSigCycleTime" SG_ 259 CrashOutputSignalStatus 100;
BA_ "GenSigSendType" SG_ 259 MSG_CNT_5 7;
BA_ "GenSigCycleTimeActive" SG_ 259 MSG_CNT_5 100;
BA_ "GenSigCycleTime" SG_ 259 MSG_CNT_5 100;
BA_ "GenSigSendType" SG_ 259 CRC_5 7;
BA_ "GenSigCycleTimeActive" SG_ 259 CRC_5 100;
BA_ "GenSigCycleTime" SG_ 259 CRC_5 100;
BA_ "GenSigSendType" SG_ 259 RrMiddleSeatBeltSwitchState 7;
BA_ "GenSigCycleTimeActive" SG_ 259 RrMiddleSeatBeltSwitchState 100;
BA_ "GenSigCycleTime" SG_ 259 RrMiddleSeatBeltSwitchState 100;
BA_ "GenSigSendType" SG_ 259 RrDrvSeatBeltSwitchState 7;
BA_ "GenSigCycleTimeActive" SG_ 259 RrDrvSeatBeltSwitchState 100;
BA_ "GenSigCycleTime" SG_ 259 RrDrvSeatBeltSwitchState 100;
BA_ "GenSigSendType" SG_ 259 RrPassSeatBeltSwitchState 7;
BA_ "GenSigCycleTimeActive" SG_ 259 RrPassSeatBeltSwitchState 100;
BA_ "GenSigCycleTime" SG_ 259 RrPassSeatBeltSwitchState 100;
BA_ "GenSigSendType" SG_ 259 FrPassSeatBeltSwitchState 7;
BA_ "GenSigCycleTimeActive" SG_ 259 FrPassSeatBeltSwitchState 100;
BA_ "GenSigCycleTime" SG_ 259 FrPassSeatBeltSwitchState 100;
BA_ "GenSigSendType" SG_ 259 FrDrvSeatBeltSwitchState 7;
BA_ "GenSigCycleTimeActive" SG_ 259 FrDrvSeatBeltSwitchState 100;
BA_ "GenSigCycleTime" SG_ 259 FrDrvSeatBeltSwitchState 100;
BA_ "GenSigSendType" SG_ 259 FrDrvSBRChime 7;
BA_ "GenSigCycleTimeActive" SG_ 259 FrDrvSBRChime 100;
BA_ "GenSigCycleTime" SG_ 259 FrDrvSBRChime 100;
BA_ "GenSigSendType" SG_ 259 FrDrvSBRIndication 7;
BA_ "GenSigCycleTimeActive" SG_ 259 FrDrvSBRIndication 100;
BA_ "GenSigCycleTime" SG_ 259 FrDrvSBRIndication 100;
BA_ "GenSigSendType" SG_ 259 CrashoutputSignal 7;
BA_ "GenSigCycleTimeActive" SG_ 259 CrashoutputSignal 100;
BA_ "GenSigCycleTime" SG_ 259 CrashoutputSignal 100;
BA_ "GenSigSendType" SG_ 259 RearDrvSBRChime 7;
BA_ "GenSigCycleTimeActive" SG_ 259 RearDrvSBRChime 100;
BA_ "GenSigCycleTime" SG_ 259 RearDrvSBRChime 100;
BA_ "GenSigSendType" SG_ 259 RearmiddlePassSBRChime 7;
BA_ "GenSigCycleTimeActive" SG_ 259 RearmiddlePassSBRChime 100;
BA_ "GenSigCycleTime" SG_ 259 RearmiddlePassSBRChime 100;
BA_ "GenSigSendType" SG_ 259 FrPassSBRChime 7;
BA_ "GenSigCycleTimeActive" SG_ 259 FrPassSBRChime 100;
BA_ "GenSigCycleTime" SG_ 259 FrPassSBRChime 100;
BA_ "GenSigSendType" SG_ 259 RearPassSBRChime 7;
BA_ "GenSigCycleTimeActive" SG_ 259 RearPassSBRChime 100;
BA_ "GenSigCycleTime" SG_ 259 RearPassSBRChime 100;
BA_ "GenSigSendType" SG_ 259 RearDrvSBRIndication 7;
BA_ "GenSigCycleTimeActive" SG_ 259 RearDrvSBRIndication 100;
BA_ "GenSigCycleTime" SG_ 259 RearDrvSBRIndication 100;
BA_ "GenSigSendType" SG_ 259 RearmiddlePassSBRIndication 7;
BA_ "GenSigCycleTimeActive" SG_ 259 RearmiddlePassSBRIndication 100;
BA_ "GenSigCycleTime" SG_ 259 RearmiddlePassSBRIndication 100;
BA_ "GenSigSendType" SG_ 259 RearPassSBRIndication 7;
BA_ "GenSigCycleTimeActive" SG_ 259 RearPassSBRIndication 100;
BA_ "GenSigCycleTime" SG_ 259 RearPassSBRIndication 100;
BA_ "GenSigSendType" SG_ 259 FrPassSBRIndication 7;
BA_ "GenSigCycleTimeActive" SG_ 259 FrPassSBRIndication 100;
BA_ "GenSigCycleTime" SG_ 259 FrPassSBRIndication 100;
BA_ "GenSigStartValue" SG_ 259 SRSWarningLamp 1;
BA_ "GenSigSendType" SG_ 259 SRSWarningLamp 7;
BA_ "GenSigCycleTimeActive" SG_ 259 SRSWarningLamp 100;
BA_ "GenSigCycleTime" SG_ 259 SRSWarningLamp 100;
BA_ "GenSigStartValue" SG_ 259 PassAirbagDeActIndi 1;
BA_ "GenSigSendType" SG_ 259 PassAirbagDeActIndi 7;
BA_ "GenSigCycleTimeActive" SG_ 259 PassAirbagDeActIndi 100;
BA_ "GenSigCycleTime" SG_ 259 PassAirbagDeActIndi 100;
BA_ "GenSigStartValue" SG_ 260 EngTrqMe 8192;
BA_ "GenSigSendType" SG_ 260 EngTrqMe 7;
BA_ "GenSigCycleTimeActive" SG_ 260 EngTrqMe 10;
BA_ "GenSigCycleTime" SG_ 260 EngTrqMe 10;
BA_ "GenSigSendType" SG_ 260 EngTrqMeStatus 7;
BA_ "GenSigCycleTimeActive" SG_ 260 EngTrqMeStatus 10;
BA_ "GenSigCycleTime" SG_ 260 EngTrqMeStatus 10;
BA_ "GenSigTimeoutTime_HU_B" SG_ 260 EngTrqLoss 0;
BA_ "GenSigTimeoutTime_HU_A" SG_ 260 EngTrqLoss 0;
BA_ "GenSigTimeoutMsg_HU_B" SG_ 260 EngTrqLoss 0;
BA_ "GenSigTimeoutMsg_HU_A" SG_ 260 EngTrqLoss 0;
BA_ "GenSigStartValue" SG_ 260 EngTrqLoss 8192;
BA_ "GenSigSendType" SG_ 260 EngTrqLoss 7;
BA_ "GenSigCycleTimeActive" SG_ 260 EngTrqLoss 10;
BA_ "GenSigCycleTime" SG_ 260 EngTrqLoss 10;
BA_ "GenSigTimeoutTime_HU_B" SG_ 260 EngTrqLossStatus 0;
BA_ "GenSigTimeoutTime_HU_A" SG_ 260 EngTrqLossStatus 0;
BA_ "GenSigTimeoutMsg_HU_B" SG_ 260 EngTrqLossStatus 0;
BA_ "GenSigTimeoutMsg_HU_A" SG_ 260 EngTrqLossStatus 0;
BA_ "GenSigSendType" SG_ 260 EngTrqLossStatus 7;
BA_ "GenSigCycleTimeActive" SG_ 260 EngTrqLossStatus 10;
BA_ "GenSigCycleTime" SG_ 260 EngTrqLossStatus 10;
BA_ "GenSigStartValue" SG_ 260 EngTrqMax 8192;
BA_ "GenSigSendType" SG_ 260 EngTrqMax 7;
BA_ "GenSigCycleTimeActive" SG_ 260 EngTrqMax 10;
BA_ "GenSigCycleTime" SG_ 260 EngTrqMax 10;
BA_ "GenSigSendType" SG_ 260 EngTrqMaxStatus 7;
BA_ "GenSigCycleTimeActive" SG_ 260 EngTrqMaxStatus 10;
BA_ "GenSigCycleTime" SG_ 260 EngTrqMaxStatus 10;
BA_ "GenSigTimeoutTime_HU_Mid_X451" SG_ 260 EngTrqTgtWoTcu 0;
BA_ "GenSigTimeoutTime_HU_High_X451" SG_ 260 EngTrqTgtWoTcu 0;
BA_ "GenSigTimeoutTime_HU_B" SG_ 260 EngTrqTgtWoTcu 0;
BA_ "GenSigTimeoutTime_HU_A" SG_ 260 EngTrqTgtWoTcu 0;
BA_ "GenSigTimeoutMsg_HU_Mid_X451" SG_ 260 EngTrqTgtWoTcu 0;
BA_ "GenSigTimeoutMsg_HU_High_X451" SG_ 260 EngTrqTgtWoTcu 0;
BA_ "GenSigTimeoutMsg_HU_B" SG_ 260 EngTrqTgtWoTcu 0;
BA_ "GenSigTimeoutMsg_HU_A" SG_ 260 EngTrqTgtWoTcu 0;
BA_ "GenSigSendType" SG_ 260 EngTrqTgtWoTcu 7;
BA_ "GenSigCycleTimeActive" SG_ 260 EngTrqTgtWoTcu 10;
BA_ "GenSigCycleTime" SG_ 260 EngTrqTgtWoTcu 10;
BA_ "GenSigTimeoutTime_HU_Mid_X451" SG_ 260 EngTrqTgtWoTcuStatus 0;
BA_ "GenSigTimeoutTime_HU_High_X451" SG_ 260 EngTrqTgtWoTcuStatus 0;
BA_ "GenSigTimeoutTime_HU_B" SG_ 260 EngTrqTgtWoTcuStatus 0;
BA_ "GenSigTimeoutTime_HU_A" SG_ 260 EngTrqTgtWoTcuStatus 0;
BA_ "GenSigTimeoutMsg_HU_Mid_X451" SG_ 260 EngTrqTgtWoTcuStatus 0;
BA_ "GenSigTimeoutMsg_HU_High_X451" SG_ 260 EngTrqTgtWoTcuStatus 0;
BA_ "GenSigTimeoutMsg_HU_B" SG_ 260 EngTrqTgtWoTcuStatus 0;
BA_ "GenSigTimeoutMsg_HU_A" SG_ 260 EngTrqTgtWoTcuStatus 0;
BA_ "GenSigSendType" SG_ 260 EngTrqTgtWoTcuStatus 7;
BA_ "GenSigCycleTimeActive" SG_ 260 EngTrqTgtWoTcuStatus 10;
BA_ "GenSigCycleTime" SG_ 260 EngTrqTgtWoTcuStatus 10;
BA_ "GenSigSendType" SG_ 262 BrkPressStatus 7;
BA_ "GenSigCycleTimeActive" SG_ 262 BrkPressStatus 10;
BA_ "GenSigCycleTime" SG_ 262 BrkPressStatus 10;
BA_ "GenSigSendType" SG_ 262 BrkPressState 7;
BA_ "GenSigCycleTimeActive" SG_ 262 BrkPressState 10;
BA_ "GenSigCycleTime" SG_ 262 BrkPressState 10;
BA_ "GenSigSendType" SG_ 262 EngSpd 7;
BA_ "GenSigCycleTimeActive" SG_ 262 EngSpd 10;
BA_ "GenSigCycleTime" SG_ 262 EngSpd 10;
BA_ "GenSigSendType" SG_ 262 EngSpdStatus 7;
BA_ "GenSigCycleTimeActive" SG_ 262 EngSpdStatus 10;
BA_ "GenSigCycleTime" SG_ 262 EngSpdStatus 10;
BA_ "GenSigStartValue" SG_ 262 AccPedRoc 125;
BA_ "GenSigSendType" SG_ 262 AccPedRoc 7;
BA_ "GenSigCycleTimeActive" SG_ 262 AccPedRoc 10;
BA_ "GenSigCycleTime" SG_ 262 AccPedRoc 10;
BA_ "GenSigSendType" SG_ 262 AccPedPosn 7;
BA_ "GenSigCycleTimeActive" SG_ 262 AccPedPosn 10;
BA_ "GenSigCycleTime" SG_ 262 AccPedPosn 10;
BA_ "GenSigSendType" SG_ 262 EngIdleSpd 7;
BA_ "GenSigCycleTimeActive" SG_ 262 EngIdleSpd 10;
BA_ "GenSigCycleTime" SG_ 262 EngIdleSpd 10;
BA_ "GenSigSendType" SG_ 262 AccPedRocStatus 7;
BA_ "GenSigCycleTimeActive" SG_ 262 AccPedRocStatus 10;
BA_ "GenSigCycleTime" SG_ 262 AccPedRocStatus 10;
BA_ "GenSigSendType" SG_ 262 EngIdleSpdStatus 7;
BA_ "GenSigCycleTimeActive" SG_ 262 EngIdleSpdStatus 10;
BA_ "GenSigCycleTime" SG_ 262 EngIdleSpdStatus 10;
BA_ "GenSigSendType" SG_ 262 AccPedPosnStatus 7;
BA_ "GenSigCycleTimeActive" SG_ 262 AccPedPosnStatus 10;
BA_ "GenSigCycleTime" SG_ 262 AccPedPosnStatus 10;
BA_ "GenSigTimeoutTime_HU_B" SG_ 262 EngSpdMsgRollCnt 0;
BA_ "GenSigTimeoutTime_HU_A" SG_ 262 EngSpdMsgRollCnt 0;
BA_ "GenSigTimeoutMsg_HU_B" SG_ 262 EngSpdMsgRollCnt 0;
BA_ "GenSigTimeoutMsg_HU_A" SG_ 262 EngSpdMsgRollCnt 0;
BA_ "GenSigSendType" SG_ 262 EngSpdMsgRollCnt 7;
BA_ "GenSigCycleTimeActive" SG_ 262 EngSpdMsgRollCnt 10;
BA_ "GenSigCycleTime" SG_ 262 EngSpdMsgRollCnt 10;
BA_ "GenSigTimeoutTime_HU_B" SG_ 262 EngSpdMsgCRC 0;
BA_ "GenSigTimeoutTime_HU_A" SG_ 262 EngSpdMsgCRC 0;
BA_ "GenSigTimeoutMsg_HU_B" SG_ 262 EngSpdMsgCRC 0;
BA_ "GenSigTimeoutMsg_HU_A" SG_ 262 EngSpdMsgCRC 0;
BA_ "GenSigSendType" SG_ 262 EngSpdMsgCRC 7;
BA_ "GenSigCycleTimeActive" SG_ 262 EngSpdMsgCRC 10;
BA_ "GenSigCycleTime" SG_ 262 EngSpdMsgCRC 10;
BA_ "GenSigTimeoutTime_HU_B" SG_ 264 EngTrqDrvrReq 0;
BA_ "GenSigTimeoutTime_HU_A" SG_ 264 EngTrqDrvrReq 0;
BA_ "GenSigTimeoutMsg_HU_B" SG_ 264 EngTrqDrvrReq 0;
BA_ "GenSigTimeoutMsg_HU_A" SG_ 264 EngTrqDrvrReq 0;
BA_ "GenSigStartValue" SG_ 264 EngTrqDrvrReq 8192;
BA_ "GenSigSendType" SG_ 264 EngTrqDrvrReq 7;
BA_ "GenSigCycleTimeActive" SG_ 264 EngTrqDrvrReq 10;
BA_ "GenSigCycleTime" SG_ 264 EngTrqDrvrReq 10;
BA_ "GenSigTimeoutTime_HU_B" SG_ 264 EngTrqDrvrReqStatus 0;
BA_ "GenSigTimeoutTime_HU_A" SG_ 264 EngTrqDrvrReqStatus 0;
BA_ "GenSigTimeoutMsg_HU_B" SG_ 264 EngTrqDrvrReqStatus 0;
BA_ "GenSigTimeoutMsg_HU_A" SG_ 264 EngTrqDrvrReqStatus 0;
BA_ "GenSigSendType" SG_ 264 EngTrqDrvrReqStatus 7;
BA_ "GenSigCycleTimeActive" SG_ 264 EngTrqDrvrReqStatus 10;
BA_ "GenSigCycleTime" SG_ 264 EngTrqDrvrReqStatus 10;
BA_ "GenSigTimeoutTime_HU_B" SG_ 264 EmsRecovery 0;
BA_ "GenSigTimeoutTime_HU_A" SG_ 264 EmsRecovery 0;
BA_ "GenSigTimeoutMsg_HU_B" SG_ 264 EmsRecovery 0;
BA_ "GenSigTimeoutMsg_HU_A" SG_ 264 EmsRecovery 0;
BA_ "GenSigSendType" SG_ 264 EmsRecovery 7;
BA_ "GenSigCycleTimeActive" SG_ 264 EmsRecovery 10;
BA_ "GenSigCycleTime" SG_ 264 EmsRecovery 10;
BA_ "GenSigTimeoutTime_HU_B" SG_ 264 CreepInhibitCmd 0;
BA_ "GenSigTimeoutTime_HU_A" SG_ 264 CreepInhibitCmd 0;
BA_ "GenSigTimeoutMsg_HU_B" SG_ 264 CreepInhibitCmd 0;
BA_ "GenSigTimeoutMsg_HU_A" SG_ 264 CreepInhibitCmd 0;
BA_ "GenSigSendType" SG_ 264 CreepInhibitCmd 7;
BA_ "GenSigCycleTimeActive" SG_ 264 CreepInhibitCmd 10;
BA_ "GenSigCycleTime" SG_ 264 CreepInhibitCmd 10;
BA_ "GenSigTimeoutTime_HU_B" SG_ 264 ModeSelectionSwStateEMSstatus 0;
BA_ "GenSigTimeoutTime_HU_A" SG_ 264 ModeSelectionSwStateEMSstatus 0;
BA_ "GenSigTimeoutMsg_HU_B" SG_ 264 ModeSelectionSwStateEMSstatus 0;
BA_ "GenSigTimeoutMsg_HU_A" SG_ 264 ModeSelectionSwStateEMSstatus 0;
BA_ "GenSigSendType" SG_ 264 ModeSelectionSwStateEMSstatus 7;
BA_ "GenSigCycleTimeActive" SG_ 264 ModeSelectionSwStateEMSstatus 10;
BA_ "GenSigCycleTime" SG_ 264 ModeSelectionSwStateEMSstatus 10;
BA_ "GenSigSendType" SG_ 264 CruiseState 7;
BA_ "GenSigCycleTimeActive" SG_ 264 CruiseState 10;
BA_ "GenSigCycleTime" SG_ 264 CruiseState 10;
BA_ "GenSigTimeoutTime_HU_B" SG_ 264 CruiseOverride 0;
BA_ "GenSigTimeoutTime_HU_A" SG_ 264 CruiseOverride 0;
BA_ "GenSigTimeoutMsg_HU_B" SG_ 264 CruiseOverride 0;
BA_ "GenSigTimeoutMsg_HU_A" SG_ 264 CruiseOverride 0;
BA_ "GenSigSendType" SG_ 264 CruiseOverride 7;
BA_ "GenSigCycleTimeActive" SG_ 264 CruiseOverride 10;
BA_ "GenSigCycleTime" SG_ 264 CruiseOverride 10;
BA_ "GenSigTimeoutTime_HU_B" SG_ 264 CanErrEms 0;
BA_ "GenSigTimeoutTime_HU_A" SG_ 264 CanErrEms 0;
BA_ "GenSigTimeoutMsg_HU_B" SG_ 264 CanErrEms 0;
BA_ "GenSigTimeoutMsg_HU_A" SG_ 264 CanErrEms 0;
BA_ "GenSigSendType" SG_ 264 CanErrEms 7;
BA_ "GenSigCycleTimeActive" SG_ 264 CanErrEms 10;
BA_ "GenSigCycleTime" SG_ 264 CanErrEms 10;
BA_ "GenSigTimeoutTime_HU_B" SG_ 264 VirtualThrottleStatus 0;
BA_ "GenSigTimeoutTime_HU_A" SG_ 264 VirtualThrottleStatus 0;
BA_ "GenSigTimeoutMsg_HU_B" SG_ 264 VirtualThrottleStatus 0;
BA_ "GenSigTimeoutMsg_HU_A" SG_ 264 VirtualThrottleStatus 0;
BA_ "GenSigSendType" SG_ 264 VirtualThrottleStatus 7;
BA_ "GenSigCycleTimeActive" SG_ 264 VirtualThrottleStatus 10;
BA_ "GenSigCycleTime" SG_ 264 VirtualThrottleStatus 10;
BA_ "GenSigTimeoutTime_HU_B" SG_ 264 ModeSelectionSwStateEMS 0;
BA_ "GenSigTimeoutTime_HU_A" SG_ 264 ModeSelectionSwStateEMS 0;
BA_ "GenSigTimeoutMsg_HU_B" SG_ 264 ModeSelectionSwStateEMS 0;
BA_ "GenSigTimeoutMsg_HU_A" SG_ 264 ModeSelectionSwStateEMS 0;
BA_ "GenSigSendType" SG_ 264 ModeSelectionSwStateEMS 7;
BA_ "GenSigCycleTimeActive" SG_ 264 ModeSelectionSwStateEMS 10;
BA_ "GenSigCycleTime" SG_ 264 ModeSelectionSwStateEMS 10;
BA_ "GenSigTimeoutTime_HU_B" SG_ 264 EngTrqDrvrReqMsgRollCnt 0;
BA_ "GenSigTimeoutTime_HU_A" SG_ 264 EngTrqDrvrReqMsgRollCnt 0;
BA_ "GenSigTimeoutMsg_HU_B" SG_ 264 EngTrqDrvrReqMsgRollCnt 0;
BA_ "GenSigTimeoutMsg_HU_A" SG_ 264 EngTrqDrvrReqMsgRollCnt 0;
BA_ "GenSigSendType" SG_ 264 EngTrqDrvrReqMsgRollCnt 7;
BA_ "GenSigCycleTimeActive" SG_ 264 EngTrqDrvrReqMsgRollCnt 10;
BA_ "GenSigCycleTime" SG_ 264 EngTrqDrvrReqMsgRollCnt 10;
BA_ "GenSigTimeoutTime_HU_B" SG_ 264 VirtualThrottle 0;
BA_ "GenSigTimeoutTime_HU_A" SG_ 264 VirtualThrottle 0;
BA_ "GenSigTimeoutMsg_HU_B" SG_ 264 VirtualThrottle 0;
BA_ "GenSigTimeoutMsg_HU_A" SG_ 264 VirtualThrottle 0;
BA_ "GenSigSendType" SG_ 264 VirtualThrottle 7;
BA_ "GenSigCycleTimeActive" SG_ 264 VirtualThrottle 10;
BA_ "GenSigCycleTime" SG_ 264 VirtualThrottle 10;
BA_ "GenSigTimeoutTime_HU_B" SG_ 264 EngTrqDrvrReqMsgCRC 0;
BA_ "GenSigTimeoutTime_HU_A" SG_ 264 EngTrqDrvrReqMsgCRC 0;
BA_ "GenSigTimeoutMsg_HU_B" SG_ 264 EngTrqDrvrReqMsgCRC 0;
BA_ "GenSigTimeoutMsg_HU_A" SG_ 264 EngTrqDrvrReqMsgCRC 0;
BA_ "GenSigSendType" SG_ 264 EngTrqDrvrReqMsgCRC 7;
BA_ "GenSigCycleTimeActive" SG_ 264 EngTrqDrvrReqMsgCRC 10;
BA_ "GenSigCycleTime" SG_ 264 EngTrqDrvrReqMsgCRC 10;
BA_ "GenSigTimeoutTime_HU_Mid_X451" SG_ 266 EMSThrtlPos 0;
BA_ "GenSigTimeoutTime_HU_High_X451" SG_ 266 EMSThrtlPos 0;
BA_ "GenSigTimeoutTime_HU_B" SG_ 266 EMSThrtlPos 0;
BA_ "GenSigTimeoutTime_HU_A" SG_ 266 EMSThrtlPos 0;
BA_ "GenSigTimeoutMsg_HU_Mid_X451" SG_ 266 EMSThrtlPos 0;
BA_ "GenSigTimeoutMsg_HU_High_X451" SG_ 266 EMSThrtlPos 0;
BA_ "GenSigTimeoutMsg_HU_B" SG_ 266 EMSThrtlPos 0;
BA_ "GenSigTimeoutMsg_HU_A" SG_ 266 EMSThrtlPos 0;
BA_ "GenSigStartValue" SG_ 266 EMSThrtlPos 32;
BA_ "GenSigSendType" SG_ 266 EMSThrtlPos 7;
BA_ "GenSigCycleTimeActive" SG_ 266 EMSThrtlPos 10;
BA_ "GenSigCycleTime" SG_ 266 EMSThrtlPos 10;
BA_ "GenSigTimeoutTime_HU_Mid_X451" SG_ 266 IntakeAirTemp 0;
BA_ "GenSigTimeoutTime_HU_High_X451" SG_ 266 IntakeAirTemp 0;
BA_ "GenSigTimeoutTime_HU_B" SG_ 266 IntakeAirTemp 0;
BA_ "GenSigTimeoutTime_HU_A" SG_ 266 IntakeAirTemp 0;
BA_ "GenSigTimeoutMsg_HU_Mid_X451" SG_ 266 IntakeAirTemp 0;
BA_ "GenSigTimeoutMsg_HU_High_X451" SG_ 266 IntakeAirTemp 0;
BA_ "GenSigTimeoutMsg_HU_B" SG_ 266 IntakeAirTemp 0;
BA_ "GenSigTimeoutMsg_HU_A" SG_ 266 IntakeAirTemp 0;
BA_ "GenSigStartValue" SG_ 266 IntakeAirTemp 64;
BA_ "GenSigSendType" SG_ 266 IntakeAirTemp 7;
BA_ "GenSigCycleTimeActive" SG_ 266 IntakeAirTemp 10;
BA_ "GenSigCycleTime" SG_ 266 IntakeAirTemp 10;
BA_ "GenSigTimeoutTime_HU_Mid_X451" SG_ 266 MAfCrctnFactor 0;
BA_ "GenSigTimeoutTime_HU_High_X451" SG_ 266 MAfCrctnFactor 0;
BA_ "GenSigTimeoutTime_HU_B" SG_ 266 MAfCrctnFactor 0;
BA_ "GenSigTimeoutTime_HU_A" SG_ 266 MAfCrctnFactor 0;
BA_ "GenSigTimeoutMsg_HU_Mid_X451" SG_ 266 MAfCrctnFactor 0;
BA_ "GenSigTimeoutMsg_HU_High_X451" SG_ 266 MAfCrctnFactor 0;
BA_ "GenSigTimeoutMsg_HU_B" SG_ 266 MAfCrctnFactor 0;
BA_ "GenSigTimeoutMsg_HU_A" SG_ 266 MAfCrctnFactor 0;
BA_ "GenSigStartValue" SG_ 266 MAfCrctnFactor 128;
BA_ "GenSigSendType" SG_ 266 MAfCrctnFactor 7;
BA_ "GenSigCycleTimeActive" SG_ 266 MAfCrctnFactor 10;
BA_ "GenSigCycleTime" SG_ 266 MAfCrctnFactor 10;
BA_ "GenSigTimeoutTime_HU_Mid_X451" SG_ 266 GenDenominator 0;
BA_ "GenSigTimeoutTime_HU_High_X451" SG_ 266 GenDenominator 0;
BA_ "GenSigTimeoutTime_HU_B" SG_ 266 GenDenominator 0;
BA_ "GenSigTimeoutTime_HU_A" SG_ 266 GenDenominator 0;
BA_ "GenSigTimeoutMsg_HU_Mid_X451" SG_ 266 GenDenominator 0;
BA_ "GenSigTimeoutMsg_HU_High_X451" SG_ 266 GenDenominator 0;
BA_ "GenSigTimeoutMsg_HU_B" SG_ 266 GenDenominator 0;
BA_ "GenSigTimeoutMsg_HU_A" SG_ 266 GenDenominator 0;
BA_ "GenSigSendType" SG_ 266 GenDenominator 7;
BA_ "GenSigCycleTimeActive" SG_ 266 GenDenominator 10;
BA_ "GenSigCycleTime" SG_ 266 GenDenominator 10;
BA_ "GenSigTimeoutTime_HU_Mid_X451" SG_ 266 EngTrqPlaus 0;
BA_ "GenSigTimeoutTime_HU_High_X451" SG_ 266 EngTrqPlaus 0;
BA_ "GenSigTimeoutTime_HU_B" SG_ 266 EngTrqPlaus 0;
BA_ "GenSigTimeoutTime_HU_A" SG_ 266 EngTrqPlaus 0;
BA_ "GenSigTimeoutMsg_HU_Mid_X451" SG_ 266 EngTrqPlaus 0;
BA_ "GenSigTimeoutMsg_HU_High_X451" SG_ 266 EngTrqPlaus 0;
BA_ "GenSigTimeoutMsg_HU_B" SG_ 266 EngTrqPlaus 0;
BA_ "GenSigTimeoutMsg_HU_A" SG_ 266 EngTrqPlaus 0;
BA_ "GenSigSendType" SG_ 266 EngTrqPlaus 7;
BA_ "GenSigCycleTimeActive" SG_ 266 EngTrqPlaus 10;
BA_ "GenSigCycleTime" SG_ 266 EngTrqPlaus 10;
BA_ "GenSigTimeoutTime_HU_Mid_X451" SG_ 266 EngFuelcutoff 0;
BA_ "GenSigTimeoutTime_HU_High_X451" SG_ 266 EngFuelcutoff 0;
BA_ "GenSigTimeoutTime_HU_B" SG_ 266 EngFuelcutoff 0;
BA_ "GenSigTimeoutTime_HU_A" SG_ 266 EngFuelcutoff 0;
BA_ "GenSigTimeoutMsg_HU_Mid_X451" SG_ 266 EngFuelcutoff 0;
BA_ "GenSigTimeoutMsg_HU_High_X451" SG_ 266 EngFuelcutoff 0;
BA_ "GenSigTimeoutMsg_HU_B" SG_ 266 EngFuelcutoff 0;
BA_ "GenSigTimeoutMsg_HU_A" SG_ 266 EngFuelcutoff 0;
BA_ "GenSigSendType" SG_ 266 EngFuelcutoff 7;
BA_ "GenSigCycleTimeActive" SG_ 266 EngFuelcutoff 10;
BA_ "GenSigCycleTime" SG_ 266 EngFuelcutoff 10;
BA_ "GenSigTimeoutTime_HU_Mid_X451" SG_ 266 EMSThrtlPosStatus 0;
BA_ "GenSigTimeoutTime_HU_High_X451" SG_ 266 EMSThrtlPosStatus 0;
BA_ "GenSigTimeoutTime_HU_B" SG_ 266 EMSThrtlPosStatus 0;
BA_ "GenSigTimeoutTime_HU_A" SG_ 266 EMSThrtlPosStatus 0;
BA_ "GenSigTimeoutMsg_HU_Mid_X451" SG_ 266 EMSThrtlPosStatus 0;
BA_ "GenSigTimeoutMsg_HU_High_X451" SG_ 266 EMSThrtlPosStatus 0;
BA_ "GenSigTimeoutMsg_HU_B" SG_ 266 EMSThrtlPosStatus 0;
BA_ "GenSigTimeoutMsg_HU_A" SG_ 266 EMSThrtlPosStatus 0;
BA_ "GenSigSendType" SG_ 266 EMSThrtlPosStatus 7;
BA_ "GenSigCycleTimeActive" SG_ 266 EMSThrtlPosStatus 10;
BA_ "GenSigCycleTime" SG_ 266 EMSThrtlPosStatus 10;
BA_ "GenSigTimeoutTime_HU_Mid_X451" SG_ 266 IntakeAirTempStatus 0;
BA_ "GenSigTimeoutTime_HU_High_X451" SG_ 266 IntakeAirTempStatus 0;
BA_ "GenSigTimeoutTime_HU_B" SG_ 266 IntakeAirTempStatus 0;
BA_ "GenSigTimeoutTime_HU_A" SG_ 266 IntakeAirTempStatus 0;
BA_ "GenSigTimeoutMsg_HU_Mid_X451" SG_ 266 IntakeAirTempStatus 0;
BA_ "GenSigTimeoutMsg_HU_High_X451" SG_ 266 IntakeAirTempStatus 0;
BA_ "GenSigTimeoutMsg_HU_B" SG_ 266 IntakeAirTempStatus 0;
BA_ "GenSigTimeoutMsg_HU_A" SG_ 266 IntakeAirTempStatus 0;
BA_ "GenSigSendType" SG_ 266 IntakeAirTempStatus 7;
BA_ "GenSigCycleTimeActive" SG_ 266 IntakeAirTempStatus 10;
BA_ "GenSigCycleTime" SG_ 266 IntakeAirTempStatus 10;
BA_ "GenSigTimeoutTime_HU_Mid_X451" SG_ 266 EngLoadOBD 0;
BA_ "GenSigTimeoutTime_HU_High_X451" SG_ 266 EngLoadOBD 0;
BA_ "GenSigTimeoutTime_HU_B" SG_ 266 EngLoadOBD 0;
BA_ "GenSigTimeoutTime_HU_A" SG_ 266 EngLoadOBD 0;
BA_ "GenSigTimeoutMsg_HU_Mid_X451" SG_ 266 EngLoadOBD 0;
BA_ "GenSigTimeoutMsg_HU_High_X451" SG_ 266 EngLoadOBD 0;
BA_ "GenSigTimeoutMsg_HU_B" SG_ 266 EngLoadOBD 0;
BA_ "GenSigTimeoutMsg_HU_A" SG_ 266 EngLoadOBD 0;
BA_ "GenSigSendType" SG_ 266 EngLoadOBD 7;
BA_ "GenSigCycleTimeActive" SG_ 266 EngLoadOBD 10;
BA_ "GenSigCycleTime" SG_ 266 EngLoadOBD 10;
BA_ "GenSigTimeoutTime_HU_Mid_X451" SG_ 268 LeadingEngTrq 0;
BA_ "GenSigTimeoutTime_HU_High_X451" SG_ 268 LeadingEngTrq 0;
BA_ "GenSigTimeoutTime_HU_B" SG_ 268 LeadingEngTrq 0;
BA_ "GenSigTimeoutTime_HU_A" SG_ 268 LeadingEngTrq 0;
BA_ "GenSigTimeoutMsg_HU_Mid_X451" SG_ 268 LeadingEngTrq 0;
BA_ "GenSigTimeoutMsg_HU_High_X451" SG_ 268 LeadingEngTrq 0;
BA_ "GenSigTimeoutMsg_HU_B" SG_ 268 LeadingEngTrq 0;
BA_ "GenSigTimeoutMsg_HU_A" SG_ 268 LeadingEngTrq 0;
BA_ "GenSigStartValue" SG_ 268 LeadingEngTrq 8192;
BA_ "GenSigSendType" SG_ 268 LeadingEngTrq 7;
BA_ "GenSigCycleTimeActive" SG_ 268 LeadingEngTrq 10;
BA_ "GenSigCycleTime" SG_ 268 LeadingEngTrq 10;
BA_ "GenSigTimeoutTime_HU_Mid_X451" SG_ 268 LeadingEngTrqStatus 0;
BA_ "GenSigTimeoutTime_HU_High_X451" SG_ 268 LeadingEngTrqStatus 0;
BA_ "GenSigTimeoutTime_HU_B" SG_ 268 LeadingEngTrqStatus 0;
BA_ "GenSigTimeoutTime_HU_A" SG_ 268 LeadingEngTrqStatus 0;
BA_ "GenSigTimeoutMsg_HU_Mid_X451" SG_ 268 LeadingEngTrqStatus 0;
BA_ "GenSigTimeoutMsg_HU_High_X451" SG_ 268 LeadingEngTrqStatus 0;
BA_ "GenSigTimeoutMsg_HU_B" SG_ 268 LeadingEngTrqStatus 0;
BA_ "GenSigTimeoutMsg_HU_A" SG_ 268 LeadingEngTrqStatus 0;
BA_ "GenSigSendType" SG_ 268 LeadingEngTrqStatus 7;
BA_ "GenSigCycleTimeActive" SG_ 268 LeadingEngTrqStatus 10;
BA_ "GenSigCycleTime" SG_ 268 LeadingEngTrqStatus 10;
BA_ "GenSigTimeoutTime_HU_Mid_X451" SG_ 268 EstEngTrq 0;
BA_ "GenSigTimeoutTime_HU_High_X451" SG_ 268 EstEngTrq 0;
BA_ "GenSigTimeoutTime_HU_B" SG_ 268 EstEngTrq 0;
BA_ "GenSigTimeoutTime_HU_A" SG_ 268 EstEngTrq 0;
BA_ "GenSigTimeoutMsg_HU_Mid_X451" SG_ 268 EstEngTrq 0;
BA_ "GenSigTimeoutMsg_HU_High_X451" SG_ 268 EstEngTrq 0;
BA_ "GenSigTimeoutMsg_HU_B" SG_ 268 EstEngTrq 0;
BA_ "GenSigTimeoutMsg_HU_A" SG_ 268 EstEngTrq 0;
BA_ "GenSigStartValue" SG_ 268 EstEngTrq 8192;
BA_ "GenSigSendType" SG_ 268 EstEngTrq 7;
BA_ "GenSigCycleTimeActive" SG_ 268 EstEngTrq 10;
BA_ "GenSigCycleTime" SG_ 268 EstEngTrq 10;
BA_ "GenSigTimeoutTime_HU_Mid_X451" SG_ 268 EstEngTrqStatus 0;
BA_ "GenSigTimeoutTime_HU_High_X451" SG_ 268 EstEngTrqStatus 0;
BA_ "GenSigTimeoutTime_HU_B" SG_ 268 EstEngTrqStatus 0;
BA_ "GenSigTimeoutTime_HU_A" SG_ 268 EstEngTrqStatus 0;
BA_ "GenSigTimeoutMsg_HU_Mid_X451" SG_ 268 EstEngTrqStatus 0;
BA_ "GenSigTimeoutMsg_HU_High_X451" SG_ 268 EstEngTrqStatus 0;
BA_ "GenSigTimeoutMsg_HU_B" SG_ 268 EstEngTrqStatus 0;
BA_ "GenSigTimeoutMsg_HU_A" SG_ 268 EstEngTrqStatus 0;
BA_ "GenSigSendType" SG_ 268 EstEngTrqStatus 7;
BA_ "GenSigCycleTimeActive" SG_ 268 EstEngTrqStatus 10;
BA_ "GenSigCycleTime" SG_ 268 EstEngTrqStatus 10;
BA_ "GenSigTimeoutTime_HU_Mid_X451" SG_ 268 TrqMsgRollCnt 0;
BA_ "GenSigTimeoutTime_HU_High_X451" SG_ 268 TrqMsgRollCnt 0;
BA_ "GenSigTimeoutTime_HU_B" SG_ 268 TrqMsgRollCnt 0;
BA_ "GenSigTimeoutTime_HU_A" SG_ 268 TrqMsgRollCnt 0;
BA_ "GenSigTimeoutMsg_HU_Mid_X451" SG_ 268 TrqMsgRollCnt 0;
BA_ "GenSigTimeoutMsg_HU_High_X451" SG_ 268 TrqMsgRollCnt 0;
BA_ "GenSigTimeoutMsg_HU_B" SG_ 268 TrqMsgRollCnt 0;
BA_ "GenSigTimeoutMsg_HU_A" SG_ 268 TrqMsgRollCnt 0;
BA_ "GenSigSendType" SG_ 268 TrqMsgRollCnt 7;
BA_ "GenSigCycleTimeActive" SG_ 268 TrqMsgRollCnt 10;
BA_ "GenSigCycleTime" SG_ 268 TrqMsgRollCnt 10;
BA_ "GenSigTimeoutTime_HU_Mid_X451" SG_ 268 TrqMsgCRC 0;
BA_ "GenSigTimeoutTime_HU_High_X451" SG_ 268 TrqMsgCRC 0;
BA_ "GenSigTimeoutTime_HU_B" SG_ 268 TrqMsgCRC 0;
BA_ "GenSigTimeoutTime_HU_A" SG_ 268 TrqMsgCRC 0;
BA_ "GenSigTimeoutMsg_HU_Mid_X451" SG_ 268 TrqMsgCRC 0;
BA_ "GenSigTimeoutMsg_HU_High_X451" SG_ 268 TrqMsgCRC 0;
BA_ "GenSigTimeoutMsg_HU_B" SG_ 268 TrqMsgCRC 0;
BA_ "GenSigTimeoutMsg_HU_A" SG_ 268 TrqMsgCRC 0;
BA_ "GenSigSendType" SG_ 268 TrqMsgCRC 7;
BA_ "GenSigCycleTimeActive" SG_ 268 TrqMsgCRC 10;
BA_ "GenSigCycleTime" SG_ 268 TrqMsgCRC 10;
BA_ "GenSigTimeoutTime_HU_Mid_X451" SG_ 270 GenDenominator 0;
BA_ "GenSigTimeoutTime_HU_High_X451" SG_ 270 GenDenominator 0;
BA_ "GenSigTimeoutTime_HU_B" SG_ 270 GenDenominator 0;
BA_ "GenSigTimeoutTime_HU_A" SG_ 270 GenDenominator 0;
BA_ "GenSigTimeoutMsg_HU_Mid_X451" SG_ 270 GenDenominator 0;
BA_ "GenSigTimeoutMsg_HU_High_X451" SG_ 270 GenDenominator 0;
BA_ "GenSigTimeoutMsg_HU_B" SG_ 270 GenDenominator 0;
BA_ "GenSigTimeoutMsg_HU_A" SG_ 270 GenDenominator 0;
BA_ "GenSigSendType" SG_ 270 GenDenominator 7;
BA_ "GenSigCycleTimeActive" SG_ 270 GenDenominator 10;
BA_ "GenSigCycleTime" SG_ 270 GenDenominator 10;
BA_ "GenSigTimeoutTime_HU_Mid_X451" SG_ 270 EngCalLoadOBD 0;
BA_ "GenSigTimeoutTime_HU_High_X451" SG_ 270 EngCalLoadOBD 0;
BA_ "GenSigTimeoutTime_HU_B" SG_ 270 EngCalLoadOBD 0;
BA_ "GenSigTimeoutTime_HU_A" SG_ 270 EngCalLoadOBD 0;
BA_ "GenSigTimeoutMsg_HU_Mid_X451" SG_ 270 EngCalLoadOBD 0;
BA_ "GenSigTimeoutMsg_HU_High_X451" SG_ 270 EngCalLoadOBD 0;
BA_ "GenSigTimeoutMsg_HU_B" SG_ 270 EngCalLoadOBD 0;
BA_ "GenSigTimeoutMsg_HU_A" SG_ 270 EngCalLoadOBD 0;
BA_ "GenSigSendType" SG_ 270 EngCalLoadOBD 7;
BA_ "GenSigCycleTimeActive" SG_ 270 EngCalLoadOBD 10;
BA_ "GenSigCycleTime" SG_ 270 EngCalLoadOBD 10;
BA_ "GenSigTimeoutTime_HU_Mid_X451" SG_ 270 DynEngTrqMax 0;
BA_ "GenSigTimeoutTime_HU_High_X451" SG_ 270 DynEngTrqMax 0;
BA_ "GenSigTimeoutTime_HU_B" SG_ 270 DynEngTrqMax 0;
BA_ "GenSigTimeoutTime_HU_A" SG_ 270 DynEngTrqMax 0;
BA_ "GenSigTimeoutMsg_HU_Mid_X451" SG_ 270 DynEngTrqMax 0;
BA_ "GenSigTimeoutMsg_HU_High_X451" SG_ 270 DynEngTrqMax 0;
BA_ "GenSigTimeoutMsg_HU_B" SG_ 270 DynEngTrqMax 0;
BA_ "GenSigTimeoutMsg_HU_A" SG_ 270 DynEngTrqMax 0;
BA_ "GenSigStartValue" SG_ 270 DynEngTrqMax 8192;
BA_ "GenSigSendType" SG_ 270 DynEngTrqMax 7;
BA_ "GenSigCycleTimeActive" SG_ 270 DynEngTrqMax 10;
BA_ "GenSigCycleTime" SG_ 270 DynEngTrqMax 10;
BA_ "GenSigTimeoutTime_HU_Mid_X451" SG_ 270 DynEngTrqMaxStatus 0;
BA_ "GenSigTimeoutTime_HU_High_X451" SG_ 270 DynEngTrqMaxStatus 0;
BA_ "GenSigTimeoutTime_HU_B" SG_ 270 DynEngTrqMaxStatus 0;
BA_ "GenSigTimeoutTime_HU_A" SG_ 270 DynEngTrqMaxStatus 0;
BA_ "GenSigTimeoutMsg_HU_Mid_X451" SG_ 270 DynEngTrqMaxStatus 0;
BA_ "GenSigTimeoutMsg_HU_High_X451" SG_ 270 DynEngTrqMaxStatus 0;
BA_ "GenSigTimeoutMsg_HU_B" SG_ 270 DynEngTrqMaxStatus 0;
BA_ "GenSigTimeoutMsg_HU_A" SG_ 270 DynEngTrqMaxStatus 0;
BA_ "GenSigSendType" SG_ 270 DynEngTrqMaxStatus 7;
BA_ "GenSigCycleTimeActive" SG_ 270 DynEngTrqMaxStatus 10;
BA_ "GenSigCycleTime" SG_ 270 DynEngTrqMaxStatus 10;
BA_ "GenSigTimeoutTime_HU_Mid_X451" SG_ 270 EngTrqMinWOfuelcut 0;
BA_ "GenSigTimeoutTime_HU_High_X451" SG_ 270 EngTrqMinWOfuelcut 0;
BA_ "GenSigTimeoutTime_HU_B" SG_ 270 EngTrqMinWOfuelcut 0;
BA_ "GenSigTimeoutTime_HU_A" SG_ 270 EngTrqMinWOfuelcut 0;
BA_ "GenSigTimeoutMsg_HU_Mid_X451" SG_ 270 EngTrqMinWOfuelcut 0;
BA_ "GenSigTimeoutMsg_HU_High_X451" SG_ 270 EngTrqMinWOfuelcut 0;
BA_ "GenSigTimeoutMsg_HU_B" SG_ 270 EngTrqMinWOfuelcut 0;
BA_ "GenSigTimeoutMsg_HU_A" SG_ 270 EngTrqMinWOfuelcut 0;
BA_ "GenSigSendType" SG_ 270 EngTrqMinWOfuelcut 7;
BA_ "GenSigCycleTimeActive" SG_ 270 EngTrqMinWOfuelcut 10;
BA_ "GenSigCycleTime" SG_ 270 EngTrqMinWOfuelcut 10;
BA_ "GenSigTimeoutTime_HU_Mid_X451" SG_ 270 EngTrqMinWOfuelcutStatus 0;
BA_ "GenSigTimeoutTime_HU_High_X451" SG_ 270 EngTrqMinWOfuelcutStatus 0;
BA_ "GenSigTimeoutTime_HU_B" SG_ 270 EngTrqMinWOfuelcutStatus 0;
BA_ "GenSigTimeoutTime_HU_A" SG_ 270 EngTrqMinWOfuelcutStatus 0;
BA_ "GenSigTimeoutMsg_HU_Mid_X451" SG_ 270 EngTrqMinWOfuelcutStatus 0;
BA_ "GenSigTimeoutMsg_HU_High_X451" SG_ 270 EngTrqMinWOfuelcutStatus 0;
BA_ "GenSigTimeoutMsg_HU_B" SG_ 270 EngTrqMinWOfuelcutStatus 0;
BA_ "GenSigTimeoutMsg_HU_A" SG_ 270 EngTrqMinWOfuelcutStatus 0;
BA_ "GenSigSendType" SG_ 270 EngTrqMinWOfuelcutStatus 7;
BA_ "GenSigCycleTimeActive" SG_ 270 EngTrqMinWOfuelcutStatus 10;
BA_ "GenSigCycleTime" SG_ 270 EngTrqMinWOfuelcutStatus 10;
BA_ "GenSigTimeoutTime_HU_Mid_X451" SG_ 270 Odometer_value 0;
BA_ "GenSigTimeoutTime_HU_High_X451" SG_ 270 Odometer_value 0;
BA_ "GenSigTimeoutTime_HU_B" SG_ 270 Odometer_value 0;
BA_ "GenSigTimeoutTime_HU_A" SG_ 270 Odometer_value 0;
BA_ "GenSigTimeoutMsg_HU_Mid_X451" SG_ 270 Odometer_value 0;
BA_ "GenSigTimeoutMsg_HU_High_X451" SG_ 270 Odometer_value 0;
BA_ "GenSigTimeoutMsg_HU_B" SG_ 270 Odometer_value 0;
BA_ "GenSigTimeoutMsg_HU_A" SG_ 270 Odometer_value 0;
BA_ "GenSigSendType" SG_ 270 Odometer_value 7;
BA_ "GenSigCycleTimeActive" SG_ 270 Odometer_value 10;
BA_ "GenSigCycleTime" SG_ 270 Odometer_value 10;
BA_ "GenSigTimeoutTime_HU_Mid_X451" SG_ 270 EngWarmupReq 0;
BA_ "GenSigTimeoutTime_HU_High_X451" SG_ 270 EngWarmupReq 0;
BA_ "GenSigTimeoutTime_HU_B" SG_ 270 EngWarmupReq 0;
BA_ "GenSigTimeoutTime_HU_A" SG_ 270 EngWarmupReq 0;
BA_ "GenSigTimeoutMsg_HU_Mid_X451" SG_ 270 EngWarmupReq 0;
BA_ "GenSigTimeoutMsg_HU_High_X451" SG_ 270 EngWarmupReq 0;
BA_ "GenSigTimeoutMsg_HU_B" SG_ 270 EngWarmupReq 0;
BA_ "GenSigTimeoutMsg_HU_A" SG_ 270 EngWarmupReq 0;
BA_ "GenSigSendType" SG_ 270 EngWarmupReq 7;
BA_ "GenSigCycleTimeActive" SG_ 270 EngWarmupReq 10;
BA_ "GenSigCycleTime" SG_ 270 EngWarmupReq 10;
BA_ "GenSigTimeoutTime_HU_Mid_X451" SG_ 270 PwrTrnOpenReq 0;
BA_ "GenSigTimeoutTime_HU_High_X451" SG_ 270 PwrTrnOpenReq 0;
BA_ "GenSigTimeoutTime_HU_B" SG_ 270 PwrTrnOpenReq 0;
BA_ "GenSigTimeoutTime_HU_A" SG_ 270 PwrTrnOpenReq 0;
BA_ "GenSigTimeoutMsg_HU_Mid_X451" SG_ 270 PwrTrnOpenReq 0;
BA_ "GenSigTimeoutMsg_HU_High_X451" SG_ 270 PwrTrnOpenReq 0;
BA_ "GenSigTimeoutMsg_HU_B" SG_ 270 PwrTrnOpenReq 0;
BA_ "GenSigTimeoutMsg_HU_A" SG_ 270 PwrTrnOpenReq 0;
BA_ "GenSigSendType" SG_ 270 PwrTrnOpenReq 7;
BA_ "GenSigCycleTimeActive" SG_ 270 PwrTrnOpenReq 10;
BA_ "GenSigCycleTime" SG_ 270 PwrTrnOpenReq 10;
BA_ "GenSigTimeoutTime_HU_Mid_X451" SG_ 270 FuelCutOffTCU 0;
BA_ "GenSigTimeoutTime_HU_High_X451" SG_ 270 FuelCutOffTCU 0;
BA_ "GenSigTimeoutTime_HU_B" SG_ 270 FuelCutOffTCU 0;
BA_ "GenSigTimeoutTime_HU_A" SG_ 270 FuelCutOffTCU 0;
BA_ "GenSigTimeoutMsg_HU_Mid_X451" SG_ 270 FuelCutOffTCU 0;
BA_ "GenSigTimeoutMsg_HU_High_X451" SG_ 270 FuelCutOffTCU 0;
BA_ "GenSigTimeoutMsg_HU_B" SG_ 270 FuelCutOffTCU 0;
BA_ "GenSigTimeoutMsg_HU_A" SG_ 270 FuelCutOffTCU 0;
BA_ "GenSigSendType" SG_ 270 FuelCutOffTCU 7;
BA_ "GenSigCycleTimeActive" SG_ 270 FuelCutOffTCU 10;
BA_ "GenSigCycleTime" SG_ 270 FuelCutOffTCU 10;
BA_ "GenSigSendType" SG_ 277 SteerAngEPAS 7;
BA_ "GenSigCycleTimeActive" SG_ 277 SteerAngEPAS 10;
BA_ "GenSigCycleTime" SG_ 277 SteerAngEPAS 10;
BA_ "GenSigSendType" SG_ 277 SteerAngEPAsDir 7;
BA_ "GenSigCycleTimeActive" SG_ 277 SteerAngEPAsDir 10;
BA_ "GenSigCycleTime" SG_ 277 SteerAngEPAsDir 10;
BA_ "GenSigStartValue" SG_ 277 SteerAngEPASStatus 2;
BA_ "GenSigSendType" SG_ 277 SteerAngEPASStatus 7;
BA_ "GenSigCycleTimeActive" SG_ 277 SteerAngEPASStatus 10;
BA_ "GenSigCycleTime" SG_ 277 SteerAngEPASStatus 10;
BA_ "GenSigTimeoutTime_HU_B" SG_ 279 SAsCcw 0;
BA_ "GenSigTimeoutTime_HU_A" SG_ 279 SAsCcw 0;
BA_ "GenSigTimeoutMsg_HU_B" SG_ 279 SAsCcw 0;
BA_ "GenSigTimeoutMsg_HU_A" SG_ 279 SAsCcw 0;
BA_ "GenSigSendType" SG_ 279 SAsCcw 7;
BA_ "GenSigCycleTimeActive" SG_ 279 SAsCcw 10;
BA_ "GenSigCycleTime" SG_ 279 SAsCcw 10;
BA_ "GenSigTimeoutTime_HU_B" SG_ 288 RESSEnableStatus 0;
BA_ "GenSigTimeoutTime_HU_A" SG_ 288 RESSEnableStatus 0;
BA_ "GenSigTimeoutMsg_HU_B" SG_ 288 RESSEnableStatus 0;
BA_ "GenSigTimeoutMsg_HU_A" SG_ 288 RESSEnableStatus 0;
BA_ "GenSigSendType" SG_ 288 RESSEnableStatus 7;
BA_ "GenSigCycleTimeActive" SG_ 288 RESSEnableStatus 10;
BA_ "GenSigCycleTime" SG_ 288 RESSEnableStatus 10;
BA_ "GenSigTimeoutTime_HU_B" SG_ 288 RESSEnable 0;
BA_ "GenSigTimeoutTime_HU_A" SG_ 288 RESSEnable 0;
BA_ "GenSigTimeoutMsg_HU_B" SG_ 288 RESSEnable 0;
BA_ "GenSigTimeoutMsg_HU_A" SG_ 288 RESSEnable 0;
BA_ "GenSigSendType" SG_ 288 RESSEnable 7;
BA_ "GenSigCycleTimeActive" SG_ 288 RESSEnable 10;
BA_ "GenSigCycleTime" SG_ 288 RESSEnable 10;
BA_ "GenSigTimeoutTime_HU_B" SG_ 288 EngTrqReq 0;
BA_ "GenSigTimeoutTime_HU_A" SG_ 288 EngTrqReq 0;
BA_ "GenSigTimeoutMsg_HU_B" SG_ 288 EngTrqReq 0;
BA_ "GenSigTimeoutMsg_HU_A" SG_ 288 EngTrqReq 0;
BA_ "GenSigSendType" SG_ 288 EngTrqReq 7;
BA_ "GenSigCycleTimeActive" SG_ 288 EngTrqReq 10;
BA_ "GenSigCycleTime" SG_ 288 EngTrqReq 10;
BA_ "GenSigTimeoutTime_HU_B" SG_ 288 EngTrqReqStatus 0;
BA_ "GenSigTimeoutTime_HU_A" SG_ 288 EngTrqReqStatus 0;
BA_ "GenSigTimeoutMsg_HU_B" SG_ 288 EngTrqReqStatus 0;
BA_ "GenSigTimeoutMsg_HU_A" SG_ 288 EngTrqReqStatus 0;
BA_ "GenSigSendType" SG_ 288 EngTrqReqStatus 7;
BA_ "GenSigCycleTimeActive" SG_ 288 EngTrqReqStatus 10;
BA_ "GenSigCycleTime" SG_ 288 EngTrqReqStatus 10;
BA_ "GenSigTimeoutTime_HU_B" SG_ 288 EngTrqReqComplement 0;
BA_ "GenSigTimeoutTime_HU_A" SG_ 288 EngTrqReqComplement 0;
BA_ "GenSigTimeoutMsg_HU_B" SG_ 288 EngTrqReqComplement 0;
BA_ "GenSigTimeoutMsg_HU_A" SG_ 288 EngTrqReqComplement 0;
BA_ "GenSigSendType" SG_ 288 EngTrqReqComplement 7;
BA_ "GenSigCycleTimeActive" SG_ 288 EngTrqReqComplement 10;
BA_ "GenSigCycleTime" SG_ 288 EngTrqReqComplement 10;
BA_ "GenSigSendType" SG_ 288 CluEngagedStatus 7;
BA_ "GenSigCycleTimeActive" SG_ 288 CluEngagedStatus 10;
BA_ "GenSigCycleTime" SG_ 288 CluEngagedStatus 10;
BA_ "GenSigSendType" SG_ 288 CluEngagedTCU 7;
BA_ "GenSigCycleTimeActive" SG_ 288 CluEngagedTCU 10;
BA_ "GenSigCycleTime" SG_ 288 CluEngagedTCU 10;
BA_ "GenSigTimeoutTime_HU_B" SG_ 288 MessageCounterAmt 0;
BA_ "GenSigTimeoutTime_HU_A" SG_ 288 MessageCounterAmt 0;
BA_ "GenSigTimeoutMsg_HU_B" SG_ 288 MessageCounterAmt 0;
BA_ "GenSigTimeoutMsg_HU_A" SG_ 288 MessageCounterAmt 0;
BA_ "GenSigSendType" SG_ 288 MessageCounterAmt 7;
BA_ "GenSigCycleTimeActive" SG_ 288 MessageCounterAmt 10;
BA_ "GenSigCycleTime" SG_ 288 MessageCounterAmt 10;
BA_ "GenSigTimeoutTime_HU_B" SG_ 288 TransLimpHomeActive 0;
BA_ "GenSigTimeoutTime_HU_A" SG_ 288 TransLimpHomeActive 0;
BA_ "GenSigTimeoutMsg_HU_B" SG_ 288 TransLimpHomeActive 0;
BA_ "GenSigTimeoutMsg_HU_A" SG_ 288 TransLimpHomeActive 0;
BA_ "GenSigSendType" SG_ 288 TransLimpHomeActive 7;
BA_ "GenSigCycleTimeActive" SG_ 288 TransLimpHomeActive 10;
BA_ "GenSigCycleTime" SG_ 288 TransLimpHomeActive 10;
BA_ "GenSigTimeoutTime_HU_B" SG_ 288 EngStopReq 0;
BA_ "GenSigTimeoutTime_HU_A" SG_ 288 EngStopReq 0;
BA_ "GenSigTimeoutMsg_HU_B" SG_ 288 EngStopReq 0;
BA_ "GenSigTimeoutMsg_HU_A" SG_ 288 EngStopReq 0;
BA_ "GenSigSendType" SG_ 288 EngStopReq 7;
BA_ "GenSigCycleTimeActive" SG_ 288 EngStopReq 10;
BA_ "GenSigCycleTime" SG_ 288 EngStopReq 10;
BA_ "GenSigTimeoutTime_HU_B" SG_ 288 CrnkEnable 0;
BA_ "GenSigTimeoutTime_HU_A" SG_ 288 CrnkEnable 0;
BA_ "GenSigTimeoutMsg_HU_B" SG_ 288 CrnkEnable 0;
BA_ "GenSigTimeoutMsg_HU_A" SG_ 288 CrnkEnable 0;
BA_ "GenSigSendType" SG_ 288 CrnkEnable 7;
BA_ "GenSigCycleTimeActive" SG_ 288 CrnkEnable 10;
BA_ "GenSigCycleTime" SG_ 288 CrnkEnable 10;
BA_ "GenSigTimeoutTime_HU_B" SG_ 288 EngTrqCtrlActive 0;
BA_ "GenSigTimeoutTime_HU_A" SG_ 288 EngTrqCtrlActive 0;
BA_ "GenSigTimeoutMsg_HU_B" SG_ 288 EngTrqCtrlActive 0;
BA_ "GenSigTimeoutMsg_HU_A" SG_ 288 EngTrqCtrlActive 0;
BA_ "GenSigSendType" SG_ 288 EngTrqCtrlActive 7;
BA_ "GenSigCycleTimeActive" SG_ 288 EngTrqCtrlActive 10;
BA_ "GenSigCycleTime" SG_ 288 EngTrqCtrlActive 10;
BA_ "GenSigTimeoutTime_HU_B" SG_ 288 HydraulicPumpActive 0;
BA_ "GenSigTimeoutTime_HU_A" SG_ 288 HydraulicPumpActive 0;
BA_ "GenSigTimeoutMsg_HU_B" SG_ 288 HydraulicPumpActive 0;
BA_ "GenSigTimeoutMsg_HU_A" SG_ 288 HydraulicPumpActive 0;
BA_ "GenSigSendType" SG_ 288 HydraulicPumpActive 7;
BA_ "GenSigCycleTimeActive" SG_ 288 HydraulicPumpActive 10;
BA_ "GenSigCycleTime" SG_ 288 HydraulicPumpActive 10;
BA_ "GenSigTimeoutTime_HU_B" SG_ 288 ReqTrqValueActive 0;
BA_ "GenSigTimeoutTime_HU_A" SG_ 288 ReqTrqValueActive 0;
BA_ "GenSigTimeoutMsg_HU_B" SG_ 288 ReqTrqValueActive 0;
BA_ "GenSigTimeoutMsg_HU_A" SG_ 288 ReqTrqValueActive 0;
BA_ "GenSigSendType" SG_ 288 ReqTrqValueActive 7;
BA_ "GenSigCycleTimeActive" SG_ 288 ReqTrqValueActive 10;
BA_ "GenSigCycleTime" SG_ 288 ReqTrqValueActive 10;
BA_ "GenSigTimeoutTime_HU_B" SG_ 288 EngTrqIncActive 0;
BA_ "GenSigTimeoutTime_HU_A" SG_ 288 EngTrqIncActive 0;
BA_ "GenSigTimeoutMsg_HU_B" SG_ 288 EngTrqIncActive 0;
BA_ "GenSigTimeoutMsg_HU_A" SG_ 288 EngTrqIncActive 0;
BA_ "GenSigSendType" SG_ 288 EngTrqIncActive 7;
BA_ "GenSigCycleTimeActive" SG_ 288 EngTrqIncActive 10;
BA_ "GenSigCycleTime" SG_ 288 EngTrqIncActive 10;
BA_ "GenSigTimeoutTime_HU_B" SG_ 288 EngTrqRednActive 0;
BA_ "GenSigTimeoutTime_HU_A" SG_ 288 EngTrqRednActive 0;
BA_ "GenSigTimeoutMsg_HU_B" SG_ 288 EngTrqRednActive 0;
BA_ "GenSigTimeoutMsg_HU_A" SG_ 288 EngTrqRednActive 0;
BA_ "GenSigSendType" SG_ 288 EngTrqRednActive 7;
BA_ "GenSigCycleTimeActive" SG_ 288 EngTrqRednActive 10;
BA_ "GenSigCycleTime" SG_ 288 EngTrqRednActive 10;
BA_ "GenSigSendType" SG_ 288 CurGearTcuStatus 7;
BA_ "GenSigCycleTimeActive" SG_ 288 CurGearTcuStatus 10;
BA_ "GenSigCycleTime" SG_ 288 CurGearTcuStatus 10;
BA_ "GenSigSendType" SG_ 288 CurGearTcu 7;
BA_ "GenSigCycleTimeActive" SG_ 288 CurGearTcu 10;
BA_ "GenSigCycleTime" SG_ 288 CurGearTcu 10;
BA_ "GenSigTimeoutTime_HU_B" SG_ 288 EngStopReqComplement 0;
BA_ "GenSigTimeoutTime_HU_A" SG_ 288 EngStopReqComplement 0;
BA_ "GenSigTimeoutMsg_HU_B" SG_ 288 EngStopReqComplement 0;
BA_ "GenSigTimeoutMsg_HU_A" SG_ 288 EngStopReqComplement 0;
BA_ "GenSigSendType" SG_ 288 EngStopReqComplement 7;
BA_ "GenSigCycleTimeActive" SG_ 288 EngStopReqComplement 10;
BA_ "GenSigCycleTime" SG_ 288 EngStopReqComplement 10;
BA_ "GenSigTimeoutTime_HU_B" SG_ 290 CreepingCluTgtTrq 0;
BA_ "GenSigTimeoutTime_HU_A" SG_ 290 CreepingCluTgtTrq 0;
BA_ "GenSigTimeoutMsg_HU_B" SG_ 290 CreepingCluTgtTrq 0;
BA_ "GenSigTimeoutMsg_HU_A" SG_ 290 CreepingCluTgtTrq 0;
BA_ "GenSigSendType" SG_ 290 CreepingCluTgtTrq 7;
BA_ "GenSigCycleTimeActive" SG_ 290 CreepingCluTgtTrq 10;
BA_ "GenSigCycleTime" SG_ 290 CreepingCluTgtTrq 10;
BA_ "GenSigTimeoutTime_HU_B" SG_ 290 CreepingCluTgtTrqStatus 0;
BA_ "GenSigTimeoutTime_HU_A" SG_ 290 CreepingCluTgtTrqStatus 0;
BA_ "GenSigTimeoutMsg_HU_B" SG_ 290 CreepingCluTgtTrqStatus 0;
BA_ "GenSigTimeoutMsg_HU_A" SG_ 290 CreepingCluTgtTrqStatus 0;
BA_ "GenSigSendType" SG_ 290 CreepingCluTgtTrqStatus 7;
BA_ "GenSigCycleTimeActive" SG_ 290 CreepingCluTgtTrqStatus 10;
BA_ "GenSigCycleTime" SG_ 290 CreepingCluTgtTrqStatus 10;
BA_ "GenSigTimeoutTime_HU_B" SG_ 290 CreepingCluTrq 0;
BA_ "GenSigTimeoutTime_HU_A" SG_ 290 CreepingCluTrq 0;
BA_ "GenSigTimeoutMsg_HU_B" SG_ 290 CreepingCluTrq 0;
BA_ "GenSigTimeoutMsg_HU_A" SG_ 290 CreepingCluTrq 0;
BA_ "GenSigSendType" SG_ 290 CreepingCluTrq 7;
BA_ "GenSigCycleTimeActive" SG_ 290 CreepingCluTrq 10;
BA_ "GenSigCycleTime" SG_ 290 CreepingCluTrq 10;
BA_ "GenSigTimeoutTime_HU_B" SG_ 290 CreepingCluTrqStatus 0;
BA_ "GenSigTimeoutTime_HU_A" SG_ 290 CreepingCluTrqStatus 0;
BA_ "GenSigTimeoutMsg_HU_B" SG_ 290 CreepingCluTrqStatus 0;
BA_ "GenSigTimeoutMsg_HU_A" SG_ 290 CreepingCluTrqStatus 0;
BA_ "GenSigSendType" SG_ 290 CreepingCluTrqStatus 7;
BA_ "GenSigCycleTimeActive" SG_ 290 CreepingCluTrqStatus 10;
BA_ "GenSigCycleTime" SG_ 290 CreepingCluTrqStatus 10;
BA_ "GenSigTimeoutTime_HU_B" SG_ 290 CreepingEnable 0;
BA_ "GenSigTimeoutTime_HU_A" SG_ 290 CreepingEnable 0;
BA_ "GenSigTimeoutMsg_HU_B" SG_ 290 CreepingEnable 0;
BA_ "GenSigTimeoutMsg_HU_A" SG_ 290 CreepingEnable 0;
BA_ "GenSigSendType" SG_ 290 CreepingEnable 7;
BA_ "GenSigCycleTimeActive" SG_ 290 CreepingEnable 10;
BA_ "GenSigCycleTime" SG_ 290 CreepingEnable 10;
BA_ "GenSigTimeoutTime_HU_B" SG_ 290 TargGearPos 0;
BA_ "GenSigTimeoutTime_HU_A" SG_ 290 TargGearPos 0;
BA_ "GenSigTimeoutMsg_HU_B" SG_ 290 TargGearPos 0;
BA_ "GenSigTimeoutMsg_HU_A" SG_ 290 TargGearPos 0;
BA_ "GenSigSendType" SG_ 290 TargGearPos 7;
BA_ "GenSigCycleTimeActive" SG_ 290 TargGearPos 10;
BA_ "GenSigCycleTime" SG_ 290 TargGearPos 10;
BA_ "GenSigTimeoutTime_HU_B" SG_ 290 TargGearPosStatus 0;
BA_ "GenSigTimeoutTime_HU_A" SG_ 290 TargGearPosStatus 0;
BA_ "GenSigTimeoutMsg_HU_B" SG_ 290 TargGearPosStatus 0;
BA_ "GenSigTimeoutMsg_HU_A" SG_ 290 TargGearPosStatus 0;
BA_ "GenSigSendType" SG_ 290 TargGearPosStatus 7;
BA_ "GenSigCycleTimeActive" SG_ 290 TargGearPosStatus 10;
BA_ "GenSigCycleTime" SG_ 290 TargGearPosStatus 10;
BA_ "GenSigTimeoutTime_HU_B" SG_ 290 GearBoxModestatus 0;
BA_ "GenSigTimeoutTime_HU_A" SG_ 290 GearBoxModestatus 0;
BA_ "GenSigTimeoutMsg_HU_B" SG_ 290 GearBoxModestatus 0;
BA_ "GenSigTimeoutMsg_HU_A" SG_ 290 GearBoxModestatus 0;
BA_ "GenSigSendType" SG_ 290 GearBoxModestatus 7;
BA_ "GenSigCycleTimeActive" SG_ 290 GearBoxModestatus 10;
BA_ "GenSigCycleTime" SG_ 290 GearBoxModestatus 10;
BA_ "GenSigTimeoutTime_HU_B" SG_ 290 GearBoxMode 0;
BA_ "GenSigTimeoutTime_HU_A" SG_ 290 GearBoxMode 0;
BA_ "GenSigTimeoutMsg_HU_B" SG_ 290 GearBoxMode 0;
BA_ "GenSigTimeoutMsg_HU_A" SG_ 290 GearBoxMode 0;
BA_ "GenSigSendType" SG_ 290 GearBoxMode 7;
BA_ "GenSigCycleTimeActive" SG_ 290 GearBoxMode 10;
BA_ "GenSigCycleTime" SG_ 290 GearBoxMode 10;
BA_ "GenSigTimeoutTime_HU_B" SG_ 290 AutoTransGrSftDirectFl 0;
BA_ "GenSigTimeoutTime_HU_A" SG_ 290 AutoTransGrSftDirectFl 0;
BA_ "GenSigTimeoutMsg_HU_B" SG_ 290 AutoTransGrSftDirectFl 0;
BA_ "GenSigTimeoutMsg_HU_A" SG_ 290 AutoTransGrSftDirectFl 0;
BA_ "GenSigSendType" SG_ 290 AutoTransGrSftDirectFl 7;
BA_ "GenSigCycleTimeActive" SG_ 290 AutoTransGrSftDirectFl 10;
BA_ "GenSigCycleTime" SG_ 290 AutoTransGrSftDirectFl 10;
BA_ "GenSigTimeoutTime_HU_B" SG_ 290 AutoTransGrSftDirect 0;
BA_ "GenSigTimeoutTime_HU_A" SG_ 290 AutoTransGrSftDirect 0;
BA_ "GenSigTimeoutMsg_HU_B" SG_ 290 AutoTransGrSftDirect 0;
BA_ "GenSigTimeoutMsg_HU_A" SG_ 290 AutoTransGrSftDirect 0;
BA_ "GenSigSendType" SG_ 290 AutoTransGrSftDirect 7;
BA_ "GenSigCycleTimeActive" SG_ 290 AutoTransGrSftDirect 10;
BA_ "GenSigCycleTime" SG_ 290 AutoTransGrSftDirect 10;
BA_ "GenSigTimeoutTime_HU_B" SG_ 291 ReserveTorqueRequestIntervention 0;
BA_ "GenSigTimeoutTime_HU_A" SG_ 291 ReserveTorqueRequestIntervention 0;
BA_ "GenSigTimeoutMsg_HU_B" SG_ 291 ReserveTorqueRequestIntervention 0;
BA_ "GenSigTimeoutMsg_HU_A" SG_ 291 ReserveTorqueRequestIntervention 0;
BA_ "GenSigSendType" SG_ 291 ReserveTorqueRequestIntervention 7;
BA_ "GenSigCycleTimeActive" SG_ 291 ReserveTorqueRequestIntervention 10;
BA_ "GenSigCycleTime" SG_ 291 ReserveTorqueRequestIntervention 10;
BA_ "GenSigTimeoutTime_HU_B" SG_ 291 ReserveTorqueRequest 0;
BA_ "GenSigTimeoutTime_HU_A" SG_ 291 ReserveTorqueRequest 0;
BA_ "GenSigTimeoutMsg_HU_B" SG_ 291 ReserveTorqueRequest 0;
BA_ "GenSigTimeoutMsg_HU_A" SG_ 291 ReserveTorqueRequest 0;
BA_ "GenSigSendType" SG_ 291 ReserveTorqueRequest 7;
BA_ "GenSigCycleTimeActive" SG_ 291 ReserveTorqueRequest 10;
BA_ "GenSigCycleTime" SG_ 291 ReserveTorqueRequest 10;
BA_ "GenSigTimeoutTime_HU_B" SG_ 291 DctPepsLockState 0;
BA_ "GenSigTimeoutTime_HU_A" SG_ 291 DctPepsLockState 0;
BA_ "GenSigTimeoutMsg_HU_B" SG_ 291 DctPepsLockState 0;
BA_ "GenSigTimeoutMsg_HU_A" SG_ 291 DctPepsLockState 0;
BA_ "GenSigSendType" SG_ 291 DctPepsLockState 7;
BA_ "GenSigCycleTimeActive" SG_ 291 DctPepsLockState 10;
BA_ "GenSigCycleTime" SG_ 291 DctPepsLockState 10;
BA_ "GenSigTimeoutTime_HU_B" SG_ 291 RESSEnableDctStatus 0;
BA_ "GenSigTimeoutTime_HU_A" SG_ 291 RESSEnableDctStatus 0;
BA_ "GenSigTimeoutMsg_HU_B" SG_ 291 RESSEnableDctStatus 0;
BA_ "GenSigTimeoutMsg_HU_A" SG_ 291 RESSEnableDctStatus 0;
BA_ "GenSigSendType" SG_ 291 RESSEnableDctStatus 7;
BA_ "GenSigCycleTimeActive" SG_ 291 RESSEnableDctStatus 10;
BA_ "GenSigCycleTime" SG_ 291 RESSEnableDctStatus 10;
BA_ "GenSigTimeoutTime_HU_B" SG_ 291 RESSEnableDct 0;
BA_ "GenSigTimeoutTime_HU_A" SG_ 291 RESSEnableDct 0;
BA_ "GenSigTimeoutMsg_HU_B" SG_ 291 RESSEnableDct 0;
BA_ "GenSigTimeoutMsg_HU_A" SG_ 291 RESSEnableDct 0;
BA_ "GenSigSendType" SG_ 291 RESSEnableDct 7;
BA_ "GenSigCycleTimeActive" SG_ 291 RESSEnableDct 10;
BA_ "GenSigCycleTime" SG_ 291 RESSEnableDct 10;
BA_ "GenSigSendType" SG_ 291 CreepState 7;
BA_ "GenSigCycleTimeActive" SG_ 291 CreepState 10;
BA_ "GenSigCycleTime" SG_ 291 CreepState 10;
BA_ "GenSigSendType" SG_ 291 TCUTxFastTrqMsgRollCnt 7;
BA_ "GenSigCycleTimeActive" SG_ 291 TCUTxFastTrqMsgRollCnt 10;
BA_ "GenSigCycleTime" SG_ 291 TCUTxFastTrqMsgRollCnt 10;
BA_ "GenSigSendType" SG_ 291 TCUTxFastTrqMsgCRC 7;
BA_ "GenSigCycleTimeActive" SG_ 291 TCUTxFastTrqMsgCRC 10;
BA_ "GenSigCycleTime" SG_ 291 TCUTxFastTrqMsgCRC 10;
BA_ "GenSigTimeoutTime_HU_Mid_X451" SG_ 291 TxmnGearRatio 0;
BA_ "GenSigTimeoutTime_HU_High_X451" SG_ 291 TxmnGearRatio 0;
BA_ "GenSigTimeoutTime_HU_B" SG_ 291 TxmnGearRatio 0;
BA_ "GenSigTimeoutTime_HU_A" SG_ 291 TxmnGearRatio 0;
BA_ "GenSigTimeoutMsg_HU_Mid_X451" SG_ 291 TxmnGearRatio 0;
BA_ "GenSigTimeoutMsg_HU_High_X451" SG_ 291 TxmnGearRatio 0;
BA_ "GenSigTimeoutMsg_HU_B" SG_ 291 TxmnGearRatio 0;
BA_ "GenSigTimeoutMsg_HU_A" SG_ 291 TxmnGearRatio 0;
BA_ "GenSigStartValue" SG_ 291 TxmnGearRatio 1000;
BA_ "GenSigSendType" SG_ 291 TxmnGearRatio 7;
BA_ "GenSigCycleTimeActive" SG_ 291 TxmnGearRatio 10;
BA_ "GenSigCycleTime" SG_ 291 TxmnGearRatio 10;
BA_ "GenSigTimeoutTime_HU_B" SG_ 291 TransLimpHomeActive 0;
BA_ "GenSigTimeoutTime_HU_A" SG_ 291 TransLimpHomeActive 0;
BA_ "GenSigTimeoutMsg_HU_B" SG_ 291 TransLimpHomeActive 0;
BA_ "GenSigTimeoutMsg_HU_A" SG_ 291 TransLimpHomeActive 0;
BA_ "GenSigSendType" SG_ 291 TransLimpHomeActive 7;
BA_ "GenSigCycleTimeActive" SG_ 291 TransLimpHomeActive 10;
BA_ "GenSigCycleTime" SG_ 291 TransLimpHomeActive 10;
BA_ "GenSigTimeoutTime_HU_Mid_X451" SG_ 291 FastTrqIntrvntnStatus 0;
BA_ "GenSigTimeoutTime_HU_High_X451" SG_ 291 FastTrqIntrvntnStatus 0;
BA_ "GenSigTimeoutTime_HU_B" SG_ 291 FastTrqIntrvntnStatus 0;
BA_ "GenSigTimeoutTime_HU_A" SG_ 291 FastTrqIntrvntnStatus 0;
BA_ "GenSigTimeoutMsg_HU_Mid_X451" SG_ 291 FastTrqIntrvntnStatus 0;
BA_ "GenSigTimeoutMsg_HU_High_X451" SG_ 291 FastTrqIntrvntnStatus 0;
BA_ "GenSigTimeoutMsg_HU_B" SG_ 291 FastTrqIntrvntnStatus 0;
BA_ "GenSigTimeoutMsg_HU_A" SG_ 291 FastTrqIntrvntnStatus 0;
BA_ "GenSigSendType" SG_ 291 FastTrqIntrvntnStatus 7;
BA_ "GenSigCycleTimeActive" SG_ 291 FastTrqIntrvntnStatus 10;
BA_ "GenSigCycleTime" SG_ 291 FastTrqIntrvntnStatus 10;
BA_ "GenSigTimeoutTime_HU_Mid_X451" SG_ 291 FastTrqIntrvntn 0;
BA_ "GenSigTimeoutTime_HU_High_X451" SG_ 291 FastTrqIntrvntn 0;
BA_ "GenSigTimeoutTime_HU_B" SG_ 291 FastTrqIntrvntn 0;
BA_ "GenSigTimeoutTime_HU_A" SG_ 291 FastTrqIntrvntn 0;
BA_ "GenSigTimeoutMsg_HU_Mid_X451" SG_ 291 FastTrqIntrvntn 0;
BA_ "GenSigTimeoutMsg_HU_High_X451" SG_ 291 FastTrqIntrvntn 0;
BA_ "GenSigTimeoutMsg_HU_B" SG_ 291 FastTrqIntrvntn 0;
BA_ "GenSigTimeoutMsg_HU_A" SG_ 291 FastTrqIntrvntn 0;
BA_ "GenSigSendType" SG_ 291 FastTrqIntrvntn 7;
BA_ "GenSigCycleTimeActive" SG_ 291 FastTrqIntrvntn 10;
BA_ "GenSigCycleTime" SG_ 291 FastTrqIntrvntn 10;
BA_ "GenSigTimeoutTime_HU_Mid_X451" SG_ 291 SlowTrqIntrvntnStatus 0;
BA_ "GenSigTimeoutTime_HU_High_X451" SG_ 291 SlowTrqIntrvntnStatus 0;
BA_ "GenSigTimeoutTime_HU_B" SG_ 291 SlowTrqIntrvntnStatus 0;
BA_ "GenSigTimeoutTime_HU_A" SG_ 291 SlowTrqIntrvntnStatus 0;
BA_ "GenSigTimeoutMsg_HU_Mid_X451" SG_ 291 SlowTrqIntrvntnStatus 0;
BA_ "GenSigTimeoutMsg_HU_High_X451" SG_ 291 SlowTrqIntrvntnStatus 0;
BA_ "GenSigTimeoutMsg_HU_B" SG_ 291 SlowTrqIntrvntnStatus 0;
BA_ "GenSigTimeoutMsg_HU_A" SG_ 291 SlowTrqIntrvntnStatus 0;
BA_ "GenSigSendType" SG_ 291 SlowTrqIntrvntnStatus 7;
BA_ "GenSigCycleTimeActive" SG_ 291 SlowTrqIntrvntnStatus 10;
BA_ "GenSigCycleTime" SG_ 291 SlowTrqIntrvntnStatus 10;
BA_ "GenSigTimeoutTime_HU_Mid_X451" SG_ 291 SlowTrqIntrvntn 0;
BA_ "GenSigTimeoutTime_HU_High_X451" SG_ 291 SlowTrqIntrvntn 0;
BA_ "GenSigTimeoutTime_HU_B" SG_ 291 SlowTrqIntrvntn 0;
BA_ "GenSigTimeoutTime_HU_A" SG_ 291 SlowTrqIntrvntn 0;
BA_ "GenSigTimeoutMsg_HU_Mid_X451" SG_ 291 SlowTrqIntrvntn 0;
BA_ "GenSigTimeoutMsg_HU_High_X451" SG_ 291 SlowTrqIntrvntn 0;
BA_ "GenSigTimeoutMsg_HU_B" SG_ 291 SlowTrqIntrvntn 0;
BA_ "GenSigTimeoutMsg_HU_A" SG_ 291 SlowTrqIntrvntn 0;
BA_ "GenSigSendType" SG_ 291 SlowTrqIntrvntn 7;
BA_ "GenSigCycleTimeActive" SG_ 291 SlowTrqIntrvntn 10;
BA_ "GenSigCycleTime" SG_ 291 SlowTrqIntrvntn 10;
BA_ "GenSigTimeoutTime_HU_B" SG_ 291 AutoTransGrSftDirect 0;
BA_ "GenSigTimeoutTime_HU_A" SG_ 291 AutoTransGrSftDirect 0;
BA_ "GenSigTimeoutMsg_HU_B" SG_ 291 AutoTransGrSftDirect 0;
BA_ "GenSigTimeoutMsg_HU_A" SG_ 291 AutoTransGrSftDirect 0;
BA_ "GenSigSendType" SG_ 291 AutoTransGrSftDirect 7;
BA_ "GenSigCycleTimeActive" SG_ 291 AutoTransGrSftDirect 10;
BA_ "GenSigCycleTime" SG_ 291 AutoTransGrSftDirect 10;
BA_ "GenSigSendType" SG_ 291 CurGearDctStatus 7;
BA_ "GenSigCycleTimeActive" SG_ 291 CurGearDctStatus 10;
BA_ "GenSigCycleTime" SG_ 291 CurGearDctStatus 10;
BA_ "GenSigSendType" SG_ 291 CurGearDct 7;
BA_ "GenSigCycleTimeActive" SG_ 291 CurGearDct 10;
BA_ "GenSigCycleTime" SG_ 291 CurGearDct 10;
BA_ "GenSigTimeoutTime_HU_Mid_X451" SG_ 291 TargGearPosDctStatus 0;
BA_ "GenSigTimeoutTime_HU_High_X451" SG_ 291 TargGearPosDctStatus 0;
BA_ "GenSigTimeoutTime_HU_B" SG_ 291 TargGearPosDctStatus 0;
BA_ "GenSigTimeoutTime_HU_A" SG_ 291 TargGearPosDctStatus 0;
BA_ "GenSigTimeoutMsg_HU_Mid_X451" SG_ 291 TargGearPosDctStatus 0;
BA_ "GenSigTimeoutMsg_HU_High_X451" SG_ 291 TargGearPosDctStatus 0;
BA_ "GenSigTimeoutMsg_HU_B" SG_ 291 TargGearPosDctStatus 0;
BA_ "GenSigTimeoutMsg_HU_A" SG_ 291 TargGearPosDctStatus 0;
BA_ "GenSigSendType" SG_ 291 TargGearPosDctStatus 7;
BA_ "GenSigCycleTimeActive" SG_ 291 TargGearPosDctStatus 10;
BA_ "GenSigCycleTime" SG_ 291 TargGearPosDctStatus 10;
BA_ "GenSigTimeoutTime_HU_Mid_X451" SG_ 291 TargGearPosDct 0;
BA_ "GenSigTimeoutTime_HU_High_X451" SG_ 291 TargGearPosDct 0;
BA_ "GenSigTimeoutTime_HU_B" SG_ 291 TargGearPosDct 0;
BA_ "GenSigTimeoutTime_HU_A" SG_ 291 TargGearPosDct 0;
BA_ "GenSigTimeoutMsg_HU_Mid_X451" SG_ 291 TargGearPosDct 0;
BA_ "GenSigTimeoutMsg_HU_High_X451" SG_ 291 TargGearPosDct 0;
BA_ "GenSigTimeoutMsg_HU_B" SG_ 291 TargGearPosDct 0;
BA_ "GenSigTimeoutMsg_HU_A" SG_ 291 TargGearPosDct 0;
BA_ "GenSigSendType" SG_ 291 TargGearPosDct 7;
BA_ "GenSigCycleTimeActive" SG_ 291 TargGearPosDct 10;
BA_ "GenSigCycleTime" SG_ 291 TargGearPosDct 10;
BA_ "GenSigTimeoutTime_HU_B" SG_ 291 AutoTransGrSftDirectFl 0;
BA_ "GenSigTimeoutTime_HU_A" SG_ 291 AutoTransGrSftDirectFl 0;
BA_ "GenSigTimeoutMsg_HU_B" SG_ 291 AutoTransGrSftDirectFl 0;
BA_ "GenSigTimeoutMsg_HU_A" SG_ 291 AutoTransGrSftDirectFl 0;
BA_ "GenSigSendType" SG_ 291 AutoTransGrSftDirectFl 7;
BA_ "GenSigCycleTimeActive" SG_ 291 AutoTransGrSftDirectFl 10;
BA_ "GenSigCycleTime" SG_ 291 AutoTransGrSftDirectFl 10;
BA_ "GenSigSendType" SG_ 383 IMGSMPosReq 7;
BA_ "GenSigCycleTimeActive" SG_ 383 IMGSMPosReq 20;
BA_ "GenSigCycleTime" SG_ 383 IMGSMPosReq 20;
BA_ "GenSigSendType" SG_ 383 IMGSMAliveCounter 7;
BA_ "GenSigCycleTimeActive" SG_ 383 IMGSMAliveCounter 20;
BA_ "GenSigCycleTime" SG_ 383 IMGSMAliveCounter 20;
BA_ "GenSigSendType" SG_ 383 IMGSMChecksum 7;
BA_ "GenSigCycleTimeActive" SG_ 383 IMGSMChecksum 20;
BA_ "GenSigCycleTime" SG_ 383 IMGSMChecksum 20;
BA_ "GenSigSendType" SG_ 383 IMGSMFaults 7;
BA_ "GenSigCycleTimeActive" SG_ 383 IMGSMFaults 20;
BA_ "GenSigCycleTime" SG_ 383 IMGSMFaults 20;
BA_ "GenSigSendType" SG_ 383 IMGSMWarning 7;
BA_ "GenSigCycleTimeActive" SG_ 383 IMGSMWarning 20;
BA_ "GenSigCycleTime" SG_ 383 IMGSMWarning 20;
BA_ "GenSigSendType" SG_ 294 TcuAccState 7;
BA_ "GenSigCycleTimeActive" SG_ 294 TcuAccState 10;
BA_ "GenSigCycleTime" SG_ 294 TcuAccState 10;
BA_ "GenSigTimeoutTime_HU_Mid_X451" SG_ 294 EngTrqLimReq 0;
BA_ "GenSigTimeoutTime_HU_High_X451" SG_ 294 EngTrqLimReq 0;
BA_ "GenSigTimeoutTime_HU_B" SG_ 294 EngTrqLimReq 0;
BA_ "GenSigTimeoutTime_HU_A" SG_ 294 EngTrqLimReq 0;
BA_ "GenSigTimeoutMsg_HU_Mid_X451" SG_ 294 EngTrqLimReq 0;
BA_ "GenSigTimeoutMsg_HU_High_X451" SG_ 294 EngTrqLimReq 0;
BA_ "GenSigTimeoutMsg_HU_B" SG_ 294 EngTrqLimReq 0;
BA_ "GenSigTimeoutMsg_HU_A" SG_ 294 EngTrqLimReq 0;
BA_ "GenSigStartValue" SG_ 294 EngTrqLimReq 255;
BA_ "GenSigSendType" SG_ 294 EngTrqLimReq 7;
BA_ "GenSigCycleTimeActive" SG_ 294 EngTrqLimReq 10;
BA_ "GenSigCycleTime" SG_ 294 EngTrqLimReq 10;
BA_ "GenSigSendType" SG_ 294 CurGearTcuAT 7;
BA_ "GenSigCycleTimeActive" SG_ 294 CurGearTcuAT 10;
BA_ "GenSigCycleTime" SG_ 294 CurGearTcuAT 10;
BA_ "GenSigTimeoutTime_HU_Mid_X451" SG_ 294 TargGearTCU 0;
BA_ "GenSigTimeoutTime_HU_High_X451" SG_ 294 TargGearTCU 0;
BA_ "GenSigTimeoutTime_HU_B" SG_ 294 TargGearTCU 0;
BA_ "GenSigTimeoutTime_HU_A" SG_ 294 TargGearTCU 0;
BA_ "GenSigTimeoutMsg_HU_Mid_X451" SG_ 294 TargGearTCU 0;
BA_ "GenSigTimeoutMsg_HU_High_X451" SG_ 294 TargGearTCU 0;
BA_ "GenSigTimeoutMsg_HU_B" SG_ 294 TargGearTCU 0;
BA_ "GenSigTimeoutMsg_HU_A" SG_ 294 TargGearTCU 0;
BA_ "GenSigSendType" SG_ 294 TargGearTCU 7;
BA_ "GenSigCycleTimeActive" SG_ 294 TargGearTCU 10;
BA_ "GenSigCycleTime" SG_ 294 TargGearTCU 10;
BA_ "GenSigTimeoutTime_HU_Mid_X451" SG_ 294 EngineSpdReq 0;
BA_ "GenSigTimeoutTime_HU_High_X451" SG_ 294 EngineSpdReq 0;
BA_ "GenSigTimeoutTime_HU_B" SG_ 294 EngineSpdReq 0;
BA_ "GenSigTimeoutTime_HU_A" SG_ 294 EngineSpdReq 0;
BA_ "GenSigTimeoutMsg_HU_Mid_X451" SG_ 294 EngineSpdReq 0;
BA_ "GenSigTimeoutMsg_HU_High_X451" SG_ 294 EngineSpdReq 0;
BA_ "GenSigTimeoutMsg_HU_B" SG_ 294 EngineSpdReq 0;
BA_ "GenSigTimeoutMsg_HU_A" SG_ 294 EngineSpdReq 0;
BA_ "GenSigStartValue" SG_ 294 EngineSpdReq 255;
BA_ "GenSigSendType" SG_ 294 EngineSpdReq 7;
BA_ "GenSigCycleTimeActive" SG_ 294 EngineSpdReq 10;
BA_ "GenSigCycleTime" SG_ 294 EngineSpdReq 10;
BA_ "GenSigSendType" SG_ 294 CurrGearTcuATStatus 7;
BA_ "GenSigCycleTimeActive" SG_ 294 CurrGearTcuATStatus 10;
BA_ "GenSigCycleTime" SG_ 294 CurrGearTcuATStatus 10;
BA_ "GenSigTimeoutTime_HU_Mid_X451" SG_ 294 ClutConvState 0;
BA_ "GenSigTimeoutTime_HU_High_X451" SG_ 294 ClutConvState 0;
BA_ "GenSigTimeoutTime_HU_B" SG_ 294 ClutConvState 0;
BA_ "GenSigTimeoutTime_HU_A" SG_ 294 ClutConvState 0;
BA_ "GenSigTimeoutMsg_HU_Mid_X451" SG_ 294 ClutConvState 0;
BA_ "GenSigTimeoutMsg_HU_High_X451" SG_ 294 ClutConvState 0;
BA_ "GenSigTimeoutMsg_HU_B" SG_ 294 ClutConvState 0;
BA_ "GenSigTimeoutMsg_HU_A" SG_ 294 ClutConvState 0;
BA_ "GenSigSendType" SG_ 294 ClutConvState 7;
BA_ "GenSigCycleTimeActive" SG_ 294 ClutConvState 10;
BA_ "GenSigCycleTime" SG_ 294 ClutConvState 10;
BA_ "GenSigTimeoutTime_HU_Mid_X451" SG_ 294 TargGearTCUStatus 0;
BA_ "GenSigTimeoutTime_HU_High_X451" SG_ 294 TargGearTCUStatus 0;
BA_ "GenSigTimeoutTime_HU_B" SG_ 294 TargGearTCUStatus 0;
BA_ "GenSigTimeoutTime_HU_A" SG_ 294 TargGearTCUStatus 0;
BA_ "GenSigTimeoutMsg_HU_Mid_X451" SG_ 294 TargGearTCUStatus 0;
BA_ "GenSigTimeoutMsg_HU_High_X451" SG_ 294 TargGearTCUStatus 0;
BA_ "GenSigTimeoutMsg_HU_B" SG_ 294 TargGearTCUStatus 0;
BA_ "GenSigTimeoutMsg_HU_A" SG_ 294 TargGearTCUStatus 0;
BA_ "GenSigSendType" SG_ 294 TargGearTCUStatus 7;
BA_ "GenSigCycleTimeActive" SG_ 294 TargGearTCUStatus 10;
BA_ "GenSigCycleTime" SG_ 294 TargGearTCUStatus 10;
BA_ "GenSigTimeoutTime_HU_Mid_X451" SG_ 294 GearShftActive 0;
BA_ "GenSigTimeoutTime_HU_High_X451" SG_ 294 GearShftActive 0;
BA_ "GenSigTimeoutTime_HU_B" SG_ 294 GearShftActive 0;
BA_ "GenSigTimeoutTime_HU_A" SG_ 294 GearShftActive 0;
BA_ "GenSigTimeoutMsg_HU_Mid_X451" SG_ 294 GearShftActive 0;
BA_ "GenSigTimeoutMsg_HU_High_X451" SG_ 294 GearShftActive 0;
BA_ "GenSigTimeoutMsg_HU_B" SG_ 294 GearShftActive 0;
BA_ "GenSigTimeoutMsg_HU_A" SG_ 294 GearShftActive 0;
BA_ "GenSigSendType" SG_ 294 GearShftActive 7;
BA_ "GenSigCycleTimeActive" SG_ 294 GearShftActive 10;
BA_ "GenSigCycleTime" SG_ 294 GearShftActive 10;
BA_ "GenSigTimeoutTime_HU_Mid_X451" SG_ 294 TCuMILReq 0;
BA_ "GenSigTimeoutTime_HU_High_X451" SG_ 294 TCuMILReq 0;
BA_ "GenSigTimeoutTime_HU_B" SG_ 294 TCuMILReq 0;
BA_ "GenSigTimeoutTime_HU_A" SG_ 294 TCuMILReq 0;
BA_ "GenSigTimeoutMsg_HU_Mid_X451" SG_ 294 TCuMILReq 0;
BA_ "GenSigTimeoutMsg_HU_High_X451" SG_ 294 TCuMILReq 0;
BA_ "GenSigTimeoutMsg_HU_B" SG_ 294 TCuMILReq 0;
BA_ "GenSigTimeoutMsg_HU_A" SG_ 294 TCuMILReq 0;
BA_ "GenSigSendType" SG_ 294 TCuMILReq 7;
BA_ "GenSigCycleTimeActive" SG_ 294 TCuMILReq 10;
BA_ "GenSigCycleTime" SG_ 294 TCuMILReq 10;
BA_ "GenSigTimeoutTime_HU_Mid_X451" SG_ 294 TCUTxEngSpdMsgRollCnt 0;
BA_ "GenSigTimeoutTime_HU_High_X451" SG_ 294 TCUTxEngSpdMsgRollCnt 0;
BA_ "GenSigTimeoutTime_HU_B" SG_ 294 TCUTxEngSpdMsgRollCnt 0;
BA_ "GenSigTimeoutTime_HU_A" SG_ 294 TCUTxEngSpdMsgRollCnt 0;
BA_ "GenSigTimeoutMsg_HU_Mid_X451" SG_ 294 TCUTxEngSpdMsgRollCnt 0;
BA_ "GenSigTimeoutMsg_HU_High_X451" SG_ 294 TCUTxEngSpdMsgRollCnt 0;
BA_ "GenSigTimeoutMsg_HU_B" SG_ 294 TCUTxEngSpdMsgRollCnt 0;
BA_ "GenSigTimeoutMsg_HU_A" SG_ 294 TCUTxEngSpdMsgRollCnt 0;
BA_ "GenSigSendType" SG_ 294 TCUTxEngSpdMsgRollCnt 7;
BA_ "GenSigCycleTimeActive" SG_ 294 TCUTxEngSpdMsgRollCnt 10;
BA_ "GenSigCycleTime" SG_ 294 TCUTxEngSpdMsgRollCnt 10;
BA_ "GenSigTimeoutTime_HU_Mid_X451" SG_ 294 TCU_NIC_State 0;
BA_ "GenSigTimeoutTime_HU_High_X451" SG_ 294 TCU_NIC_State 0;
BA_ "GenSigTimeoutTime_HU_B" SG_ 294 TCU_NIC_State 0;
BA_ "GenSigTimeoutTime_HU_A" SG_ 294 TCU_NIC_State 0;
BA_ "GenSigTimeoutMsg_HU_Mid_X451" SG_ 294 TCU_NIC_State 0;
BA_ "GenSigTimeoutMsg_HU_High_X451" SG_ 294 TCU_NIC_State 0;
BA_ "GenSigTimeoutMsg_HU_B" SG_ 294 TCU_NIC_State 0;
BA_ "GenSigTimeoutMsg_HU_A" SG_ 294 TCU_NIC_State 0;
BA_ "GenSigSendType" SG_ 294 TCU_NIC_State 7;
BA_ "GenSigCycleTimeActive" SG_ 294 TCU_NIC_State 10;
BA_ "GenSigCycleTime" SG_ 294 TCU_NIC_State 10;
BA_ "GenSigTimeoutTime_HU_Mid_X451" SG_ 294 EngSpdReqStatus 0;
BA_ "GenSigTimeoutTime_HU_High_X451" SG_ 294 EngSpdReqStatus 0;
BA_ "GenSigTimeoutTime_HU_B" SG_ 294 EngSpdReqStatus 0;
BA_ "GenSigTimeoutTime_HU_A" SG_ 294 EngSpdReqStatus 0;
BA_ "GenSigTimeoutMsg_HU_Mid_X451" SG_ 294 EngSpdReqStatus 0;
BA_ "GenSigTimeoutMsg_HU_High_X451" SG_ 294 EngSpdReqStatus 0;
BA_ "GenSigTimeoutMsg_HU_B" SG_ 294 EngSpdReqStatus 0;
BA_ "GenSigTimeoutMsg_HU_A" SG_ 294 EngSpdReqStatus 0;
BA_ "GenSigSendType" SG_ 294 EngSpdReqStatus 7;
BA_ "GenSigCycleTimeActive" SG_ 294 EngSpdReqStatus 10;
BA_ "GenSigCycleTime" SG_ 294 EngSpdReqStatus 10;
BA_ "GenSigTimeoutTime_HU_Mid_X451" SG_ 294 TCUTxEngSpdMsgCRC 0;
BA_ "GenSigTimeoutTime_HU_High_X451" SG_ 294 TCUTxEngSpdMsgCRC 0;
BA_ "GenSigTimeoutTime_HU_B" SG_ 294 TCUTxEngSpdMsgCRC 0;
BA_ "GenSigTimeoutTime_HU_A" SG_ 294 TCUTxEngSpdMsgCRC 0;
BA_ "GenSigTimeoutMsg_HU_Mid_X451" SG_ 294 TCUTxEngSpdMsgCRC 0;
BA_ "GenSigTimeoutMsg_HU_High_X451" SG_ 294 TCUTxEngSpdMsgCRC 0;
BA_ "GenSigTimeoutMsg_HU_B" SG_ 294 TCUTxEngSpdMsgCRC 0;
BA_ "GenSigTimeoutMsg_HU_A" SG_ 294 TCUTxEngSpdMsgCRC 0;
BA_ "GenSigSendType" SG_ 294 TCUTxEngSpdMsgCRC 7;
BA_ "GenSigCycleTimeActive" SG_ 294 TCUTxEngSpdMsgCRC 10;
BA_ "GenSigCycleTime" SG_ 294 TCUTxEngSpdMsgCRC 10;
BA_ "GenSigSendType" SG_ 296 GearShftLvrPos 7;
BA_ "GenSigCycleTimeActive" SG_ 296 GearShftLvrPos 10;
BA_ "GenSigCycleTime" SG_ 296 GearShftLvrPos 10;
BA_ "GenSigTimeoutTime_HU_Mid_X451" SG_ 296 GearBoxModeNew 0;
BA_ "GenSigTimeoutTime_HU_High_X451" SG_ 296 GearBoxModeNew 0;
BA_ "GenSigTimeoutTime_HU_B" SG_ 296 GearBoxModeNew 0;
BA_ "GenSigTimeoutTime_HU_A" SG_ 296 GearBoxModeNew 0;
BA_ "GenSigTimeoutMsg_HU_Mid_X451" SG_ 296 GearBoxModeNew 0;
BA_ "GenSigTimeoutMsg_HU_High_X451" SG_ 296 GearBoxModeNew 0;
BA_ "GenSigTimeoutMsg_HU_B" SG_ 296 GearBoxModeNew 0;
BA_ "GenSigTimeoutMsg_HU_A" SG_ 296 GearBoxModeNew 0;
BA_ "GenSigSendType" SG_ 296 GearBoxModeNew 7;
BA_ "GenSigCycleTimeActive" SG_ 296 GearBoxModeNew 10;
BA_ "GenSigCycleTime" SG_ 296 GearBoxModeNew 10;
BA_ "GenSigTimeoutTime_HU_Mid_X451" SG_ 296 InhFuelCutOff 0;
BA_ "GenSigTimeoutTime_HU_High_X451" SG_ 296 InhFuelCutOff 0;
BA_ "GenSigTimeoutTime_HU_B" SG_ 296 InhFuelCutOff 0;
BA_ "GenSigTimeoutTime_HU_A" SG_ 296 InhFuelCutOff 0;
BA_ "GenSigTimeoutMsg_HU_Mid_X451" SG_ 296 InhFuelCutOff 0;
BA_ "GenSigTimeoutMsg_HU_High_X451" SG_ 296 InhFuelCutOff 0;
BA_ "GenSigTimeoutMsg_HU_B" SG_ 296 InhFuelCutOff 0;
BA_ "GenSigTimeoutMsg_HU_A" SG_ 296 InhFuelCutOff 0;
BA_ "GenSigSendType" SG_ 296 InhFuelCutOff 7;
BA_ "GenSigCycleTimeActive" SG_ 296 InhFuelCutOff 10;
BA_ "GenSigCycleTime" SG_ 296 InhFuelCutOff 10;
BA_ "GenSigSendType" SG_ 296 GearShftLvrPosStatus 7;
BA_ "GenSigCycleTimeActive" SG_ 296 GearShftLvrPosStatus 10;
BA_ "GenSigCycleTime" SG_ 296 GearShftLvrPosStatus 10;
BA_ "GenSigTimeoutTime_HU_Mid_X451" SG_ 296 GearBoxModeNewStatus 0;
BA_ "GenSigTimeoutTime_HU_High_X451" SG_ 296 GearBoxModeNewStatus 0;
BA_ "GenSigTimeoutTime_HU_B" SG_ 296 GearBoxModeNewStatus 0;
BA_ "GenSigTimeoutTime_HU_A" SG_ 296 GearBoxModeNewStatus 0;
BA_ "GenSigTimeoutMsg_HU_Mid_X451" SG_ 296 GearBoxModeNewStatus 0;
BA_ "GenSigTimeoutMsg_HU_High_X451" SG_ 296 GearBoxModeNewStatus 0;
BA_ "GenSigTimeoutMsg_HU_B" SG_ 296 GearBoxModeNewStatus 0;
BA_ "GenSigTimeoutMsg_HU_A" SG_ 296 GearBoxModeNewStatus 0;
BA_ "GenSigSendType" SG_ 296 GearBoxModeNewStatus 7;
BA_ "GenSigCycleTimeActive" SG_ 296 GearBoxModeNewStatus 10;
BA_ "GenSigCycleTime" SG_ 296 GearBoxModeNewStatus 10;
BA_ "GenSigTimeoutTime_HU_Mid_X451" SG_ 296 EngTrqIncReq 0;
BA_ "GenSigTimeoutTime_HU_High_X451" SG_ 296 EngTrqIncReq 0;
BA_ "GenSigTimeoutTime_HU_B" SG_ 296 EngTrqIncReq 0;
BA_ "GenSigTimeoutTime_HU_A" SG_ 296 EngTrqIncReq 0;
BA_ "GenSigTimeoutMsg_HU_Mid_X451" SG_ 296 EngTrqIncReq 0;
BA_ "GenSigTimeoutMsg_HU_High_X451" SG_ 296 EngTrqIncReq 0;
BA_ "GenSigTimeoutMsg_HU_B" SG_ 296 EngTrqIncReq 0;
BA_ "GenSigTimeoutMsg_HU_A" SG_ 296 EngTrqIncReq 0;
BA_ "GenSigStartValue" SG_ 296 EngTrqIncReq 8192;
BA_ "GenSigSendType" SG_ 296 EngTrqIncReq 7;
BA_ "GenSigCycleTimeActive" SG_ 296 EngTrqIncReq 10;
BA_ "GenSigCycleTime" SG_ 296 EngTrqIncReq 10;
BA_ "GenSigTimeoutTime_HU_Mid_X451" SG_ 296 EngTrqRednReq 0;
BA_ "GenSigTimeoutTime_HU_High_X451" SG_ 296 EngTrqRednReq 0;
BA_ "GenSigTimeoutTime_HU_B" SG_ 296 EngTrqRednReq 0;
BA_ "GenSigTimeoutTime_HU_A" SG_ 296 EngTrqRednReq 0;
BA_ "GenSigTimeoutMsg_HU_Mid_X451" SG_ 296 EngTrqRednReq 0;
BA_ "GenSigTimeoutMsg_HU_High_X451" SG_ 296 EngTrqRednReq 0;
BA_ "GenSigTimeoutMsg_HU_B" SG_ 296 EngTrqRednReq 0;
BA_ "GenSigTimeoutMsg_HU_A" SG_ 296 EngTrqRednReq 0;
BA_ "GenSigStartValue" SG_ 296 EngTrqRednReq 16380;
BA_ "GenSigSendType" SG_ 296 EngTrqRednReq 7;
BA_ "GenSigCycleTimeActive" SG_ 296 EngTrqRednReq 10;
BA_ "GenSigCycleTime" SG_ 296 EngTrqRednReq 10;
BA_ "GenSigTimeoutTime_HU_Mid_X451" SG_ 296 TCUTxEngTrqIncReqMsgRollCnt 0;
BA_ "GenSigTimeoutTime_HU_High_X451" SG_ 296 TCUTxEngTrqIncReqMsgRollCnt 0;
BA_ "GenSigTimeoutTime_HU_B" SG_ 296 TCUTxEngTrqIncReqMsgRollCnt 0;
BA_ "GenSigTimeoutTime_HU_A" SG_ 296 TCUTxEngTrqIncReqMsgRollCnt 0;
BA_ "GenSigTimeoutMsg_HU_Mid_X451" SG_ 296 TCUTxEngTrqIncReqMsgRollCnt 0;
BA_ "GenSigTimeoutMsg_HU_High_X451" SG_ 296 TCUTxEngTrqIncReqMsgRollCnt 0;
BA_ "GenSigTimeoutMsg_HU_B" SG_ 296 TCUTxEngTrqIncReqMsgRollCnt 0;
BA_ "GenSigTimeoutMsg_HU_A" SG_ 296 TCUTxEngTrqIncReqMsgRollCnt 0;
BA_ "GenSigSendType" SG_ 296 TCUTxEngTrqIncReqMsgRollCnt 7;
BA_ "GenSigCycleTimeActive" SG_ 296 TCUTxEngTrqIncReqMsgRollCnt 10;
BA_ "GenSigCycleTime" SG_ 296 TCUTxEngTrqIncReqMsgRollCnt 10;
BA_ "GenSigTimeoutTime_HU_Mid_X451" SG_ 296 TCUTxEngTrqIncReqMsgCRC 0;
BA_ "GenSigTimeoutTime_HU_High_X451" SG_ 296 TCUTxEngTrqIncReqMsgCRC 0;
BA_ "GenSigTimeoutTime_HU_B" SG_ 296 TCUTxEngTrqIncReqMsgCRC 0;
BA_ "GenSigTimeoutTime_HU_A" SG_ 296 TCUTxEngTrqIncReqMsgCRC 0;
BA_ "GenSigTimeoutMsg_HU_Mid_X451" SG_ 296 TCUTxEngTrqIncReqMsgCRC 0;
BA_ "GenSigTimeoutMsg_HU_High_X451" SG_ 296 TCUTxEngTrqIncReqMsgCRC 0;
BA_ "GenSigTimeoutMsg_HU_B" SG_ 296 TCUTxEngTrqIncReqMsgCRC 0;
BA_ "GenSigTimeoutMsg_HU_A" SG_ 296 TCUTxEngTrqIncReqMsgCRC 0;
BA_ "GenSigSendType" SG_ 296 TCUTxEngTrqIncReqMsgCRC 7;
BA_ "GenSigCycleTimeActive" SG_ 296 TCUTxEngTrqIncReqMsgCRC 10;
BA_ "GenSigCycleTime" SG_ 296 TCUTxEngTrqIncReqMsgCRC 10;
BA_ "GenSigTimeoutTime_HU_Mid_X451" SG_ 298 FastTrqReq 0;
BA_ "GenSigTimeoutTime_HU_High_X451" SG_ 298 FastTrqReq 0;
BA_ "GenSigTimeoutTime_HU_B" SG_ 298 FastTrqReq 0;
BA_ "GenSigTimeoutTime_HU_A" SG_ 298 FastTrqReq 0;
BA_ "GenSigTimeoutMsg_HU_Mid_X451" SG_ 298 FastTrqReq 0;
BA_ "GenSigTimeoutMsg_HU_High_X451" SG_ 298 FastTrqReq 0;
BA_ "GenSigTimeoutMsg_HU_B" SG_ 298 FastTrqReq 0;
BA_ "GenSigTimeoutMsg_HU_A" SG_ 298 FastTrqReq 0;
BA_ "GenSigStartValue" SG_ 298 FastTrqReq 8192;
BA_ "GenSigSendType" SG_ 298 FastTrqReq 7;
BA_ "GenSigCycleTimeActive" SG_ 298 FastTrqReq 10;
BA_ "GenSigCycleTime" SG_ 298 FastTrqReq 10;
BA_ "GenSigTimeoutTime_HU_Mid_X451" SG_ 298 FastTrqReqStatus 0;
BA_ "GenSigTimeoutTime_HU_High_X451" SG_ 298 FastTrqReqStatus 0;
BA_ "GenSigTimeoutTime_HU_B" SG_ 298 FastTrqReqStatus 0;
BA_ "GenSigTimeoutTime_HU_A" SG_ 298 FastTrqReqStatus 0;
BA_ "GenSigTimeoutMsg_HU_Mid_X451" SG_ 298 FastTrqReqStatus 0;
BA_ "GenSigTimeoutMsg_HU_High_X451" SG_ 298 FastTrqReqStatus 0;
BA_ "GenSigTimeoutMsg_HU_B" SG_ 298 FastTrqReqStatus 0;
BA_ "GenSigTimeoutMsg_HU_A" SG_ 298 FastTrqReqStatus 0;
BA_ "GenSigSendType" SG_ 298 FastTrqReqStatus 7;
BA_ "GenSigCycleTimeActive" SG_ 298 FastTrqReqStatus 10;
BA_ "GenSigCycleTime" SG_ 298 FastTrqReqStatus 10;
BA_ "GenSigTimeoutTime_HU_Mid_X451" SG_ 298 SlowTrqReq 0;
BA_ "GenSigTimeoutTime_HU_High_X451" SG_ 298 SlowTrqReq 0;
BA_ "GenSigTimeoutTime_HU_B" SG_ 298 SlowTrqReq 0;
BA_ "GenSigTimeoutTime_HU_A" SG_ 298 SlowTrqReq 0;
BA_ "GenSigTimeoutMsg_HU_Mid_X451" SG_ 298 SlowTrqReq 0;
BA_ "GenSigTimeoutMsg_HU_High_X451" SG_ 298 SlowTrqReq 0;
BA_ "GenSigTimeoutMsg_HU_B" SG_ 298 SlowTrqReq 0;
BA_ "GenSigTimeoutMsg_HU_A" SG_ 298 SlowTrqReq 0;
BA_ "GenSigStartValue" SG_ 298 SlowTrqReq 8192;
BA_ "GenSigSendType" SG_ 298 SlowTrqReq 7;
BA_ "GenSigCycleTimeActive" SG_ 298 SlowTrqReq 10;
BA_ "GenSigCycleTime" SG_ 298 SlowTrqReq 10;
BA_ "GenSigTimeoutTime_HU_Mid_X451" SG_ 298 SlowTrqReqStatus 0;
BA_ "GenSigTimeoutTime_HU_High_X451" SG_ 298 SlowTrqReqStatus 0;
BA_ "GenSigTimeoutTime_HU_B" SG_ 298 SlowTrqReqStatus 0;
BA_ "GenSigTimeoutTime_HU_A" SG_ 298 SlowTrqReqStatus 0;
BA_ "GenSigTimeoutMsg_HU_Mid_X451" SG_ 298 SlowTrqReqStatus 0;
BA_ "GenSigTimeoutMsg_HU_High_X451" SG_ 298 SlowTrqReqStatus 0;
BA_ "GenSigTimeoutMsg_HU_B" SG_ 298 SlowTrqReqStatus 0;
BA_ "GenSigTimeoutMsg_HU_A" SG_ 298 SlowTrqReqStatus 0;
BA_ "GenSigSendType" SG_ 298 SlowTrqReqStatus 7;
BA_ "GenSigCycleTimeActive" SG_ 298 SlowTrqReqStatus 10;
BA_ "GenSigCycleTime" SG_ 298 SlowTrqReqStatus 10;
BA_ "GenSigTimeoutTime_HU_Mid_X451" SG_ 298 ClutchTrq 0;
BA_ "GenSigTimeoutTime_HU_High_X451" SG_ 298 ClutchTrq 0;
BA_ "GenSigTimeoutTime_HU_B" SG_ 298 ClutchTrq 0;
BA_ "GenSigTimeoutTime_HU_A" SG_ 298 ClutchTrq 0;
BA_ "GenSigTimeoutMsg_HU_Mid_X451" SG_ 298 ClutchTrq 0;
BA_ "GenSigTimeoutMsg_HU_High_X451" SG_ 298 ClutchTrq 0;
BA_ "GenSigTimeoutMsg_HU_B" SG_ 298 ClutchTrq 0;
BA_ "GenSigTimeoutMsg_HU_A" SG_ 298 ClutchTrq 0;
BA_ "GenSigStartValue" SG_ 298 ClutchTrq 8192;
BA_ "GenSigSendType" SG_ 298 ClutchTrq 7;
BA_ "GenSigCycleTimeActive" SG_ 298 ClutchTrq 10;
BA_ "GenSigCycleTime" SG_ 298 ClutchTrq 10;
BA_ "GenSigSendType" SG_ 298 CluEngagedTcuDCTStatus 7;
BA_ "GenSigCycleTimeActive" SG_ 298 CluEngagedTcuDCTStatus 10;
BA_ "GenSigCycleTime" SG_ 298 CluEngagedTcuDCTStatus 10;
BA_ "GenSigSendType" SG_ 298 TCUTxTrqMsgRollCnt 7;
BA_ "GenSigCycleTimeActive" SG_ 298 TCUTxTrqMsgRollCnt 10;
BA_ "GenSigCycleTime" SG_ 298 TCUTxTrqMsgRollCnt 10;
BA_ "GenSigTimeoutTime_HU_B" SG_ 298 CrnkEnable 0;
BA_ "GenSigTimeoutTime_HU_A" SG_ 298 CrnkEnable 0;
BA_ "GenSigTimeoutMsg_HU_B" SG_ 298 CrnkEnable 0;
BA_ "GenSigTimeoutMsg_HU_A" SG_ 298 CrnkEnable 0;
BA_ "GenSigSendType" SG_ 298 CrnkEnable 7;
BA_ "GenSigCycleTimeActive" SG_ 298 CrnkEnable 10;
BA_ "GenSigCycleTime" SG_ 298 CrnkEnable 10;
BA_ "GenSigTimeoutTime_HU_B" SG_ 298 FuelCutOffTCUReq 0;
BA_ "GenSigTimeoutTime_HU_A" SG_ 298 FuelCutOffTCUReq 0;
BA_ "GenSigTimeoutMsg_HU_B" SG_ 298 FuelCutOffTCUReq 0;
BA_ "GenSigTimeoutMsg_HU_A" SG_ 298 FuelCutOffTCUReq 0;
BA_ "GenSigSendType" SG_ 298 FuelCutOffTCUReq 7;
BA_ "GenSigCycleTimeActive" SG_ 298 FuelCutOffTCUReq 10;
BA_ "GenSigCycleTime" SG_ 298 FuelCutOffTCUReq 10;
BA_ "GenSigSendType" SG_ 298 CluEngagedTcuDCT 7;
BA_ "GenSigCycleTimeActive" SG_ 298 CluEngagedTcuDCT 10;
BA_ "GenSigCycleTime" SG_ 298 CluEngagedTcuDCT 10;
BA_ "GenSigSendType" SG_ 298 TCUTxTrqMsgCRC 7;
BA_ "GenSigCycleTimeActive" SG_ 298 TCUTxTrqMsgCRC 10;
BA_ "GenSigCycleTime" SG_ 298 TCUTxTrqMsgCRC 10;
BA_ "GenSigTimeoutTime_HU_Mid_X451" SG_ 300 TxmnLossTrq 0;
BA_ "GenSigTimeoutTime_HU_High_X451" SG_ 300 TxmnLossTrq 0;
BA_ "GenSigTimeoutTime_HU_B" SG_ 300 TxmnLossTrq 0;
BA_ "GenSigTimeoutTime_HU_A" SG_ 300 TxmnLossTrq 0;
BA_ "GenSigTimeoutMsg_HU_Mid_X451" SG_ 300 TxmnLossTrq 0;
BA_ "GenSigTimeoutMsg_HU_High_X451" SG_ 300 TxmnLossTrq 0;
BA_ "GenSigTimeoutMsg_HU_B" SG_ 300 TxmnLossTrq 0;
BA_ "GenSigTimeoutMsg_HU_A" SG_ 300 TxmnLossTrq 0;
BA_ "GenSigStartValue" SG_ 300 TxmnLossTrq 8192;
BA_ "GenSigSendType" SG_ 300 TxmnLossTrq 7;
BA_ "GenSigCycleTimeActive" SG_ 300 TxmnLossTrq 10;
BA_ "GenSigCycleTime" SG_ 300 TxmnLossTrq 10;
BA_ "GenSigTimeoutTime_HU_Mid_X451" SG_ 300 EngIdleSpdLiftUpReqStatus 0;
BA_ "GenSigTimeoutTime_HU_High_X451" SG_ 300 EngIdleSpdLiftUpReqStatus 0;
BA_ "GenSigTimeoutTime_HU_B" SG_ 300 EngIdleSpdLiftUpReqStatus 0;
BA_ "GenSigTimeoutTime_HU_A" SG_ 300 EngIdleSpdLiftUpReqStatus 0;
BA_ "GenSigTimeoutMsg_HU_Mid_X451" SG_ 300 EngIdleSpdLiftUpReqStatus 0;
BA_ "GenSigTimeoutMsg_HU_High_X451" SG_ 300 EngIdleSpdLiftUpReqStatus 0;
BA_ "GenSigTimeoutMsg_HU_B" SG_ 300 EngIdleSpdLiftUpReqStatus 0;
BA_ "GenSigTimeoutMsg_HU_A" SG_ 300 EngIdleSpdLiftUpReqStatus 0;
BA_ "GenSigSendType" SG_ 300 EngIdleSpdLiftUpReqStatus 7;
BA_ "GenSigCycleTimeActive" SG_ 300 EngIdleSpdLiftUpReqStatus 10;
BA_ "GenSigCycleTime" SG_ 300 EngIdleSpdLiftUpReqStatus 10;
BA_ "GenSigTimeoutTime_HU_Mid_X451" SG_ 300 EngIdleSpdLiftUpReq 0;
BA_ "GenSigTimeoutTime_HU_High_X451" SG_ 300 EngIdleSpdLiftUpReq 0;
BA_ "GenSigTimeoutTime_HU_B" SG_ 300 EngIdleSpdLiftUpReq 0;
BA_ "GenSigTimeoutTime_HU_A" SG_ 300 EngIdleSpdLiftUpReq 0;
BA_ "GenSigTimeoutMsg_HU_Mid_X451" SG_ 300 EngIdleSpdLiftUpReq 0;
BA_ "GenSigTimeoutMsg_HU_High_X451" SG_ 300 EngIdleSpdLiftUpReq 0;
BA_ "GenSigTimeoutMsg_HU_B" SG_ 300 EngIdleSpdLiftUpReq 0;
BA_ "GenSigTimeoutMsg_HU_A" SG_ 300 EngIdleSpdLiftUpReq 0;
BA_ "GenSigSendType" SG_ 300 EngIdleSpdLiftUpReq 7;
BA_ "GenSigCycleTimeActive" SG_ 300 EngIdleSpdLiftUpReq 10;
BA_ "GenSigCycleTime" SG_ 300 EngIdleSpdLiftUpReq 10;
BA_ "GenSigTimeoutTime_HU_Mid_X451" SG_ 300 EngSpdlimitReq 0;
BA_ "GenSigTimeoutTime_HU_High_X451" SG_ 300 EngSpdlimitReq 0;
BA_ "GenSigTimeoutTime_HU_B" SG_ 300 EngSpdlimitReq 0;
BA_ "GenSigTimeoutTime_HU_A" SG_ 300 EngSpdlimitReq 0;
BA_ "GenSigTimeoutMsg_HU_Mid_X451" SG_ 300 EngSpdlimitReq 0;
BA_ "GenSigTimeoutMsg_HU_High_X451" SG_ 300 EngSpdlimitReq 0;
BA_ "GenSigTimeoutMsg_HU_B" SG_ 300 EngSpdlimitReq 0;
BA_ "GenSigTimeoutMsg_HU_A" SG_ 300 EngSpdlimitReq 0;
BA_ "GenSigStartValue" SG_ 300 EngSpdlimitReq 8000;
BA_ "GenSigSendType" SG_ 300 EngSpdlimitReq 7;
BA_ "GenSigCycleTimeActive" SG_ 300 EngSpdlimitReq 10;
BA_ "GenSigCycleTime" SG_ 300 EngSpdlimitReq 10;
BA_ "GenSigTimeoutTime_HU_B" SG_ 300 GearBoxModestatus 0;
BA_ "GenSigTimeoutTime_HU_A" SG_ 300 GearBoxModestatus 0;
BA_ "GenSigTimeoutMsg_HU_B" SG_ 300 GearBoxModestatus 0;
BA_ "GenSigTimeoutMsg_HU_A" SG_ 300 GearBoxModestatus 0;
BA_ "GenSigSendType" SG_ 300 GearBoxModestatus 7;
BA_ "GenSigCycleTimeActive" SG_ 300 GearBoxModestatus 10;
BA_ "GenSigCycleTime" SG_ 300 GearBoxModestatus 10;
BA_ "GenSigSendType" SG_ 300 GearShftLvrPosDctStatus 7;
BA_ "GenSigCycleTimeActive" SG_ 300 GearShftLvrPosDctStatus 10;
BA_ "GenSigCycleTime" SG_ 300 GearShftLvrPosDctStatus 10;
BA_ "GenSigTimeoutTime_HU_Mid_X451" SG_ 300 IdleSpdLiftUpIntrvntn 0;
BA_ "GenSigTimeoutTime_HU_High_X451" SG_ 300 IdleSpdLiftUpIntrvntn 0;
BA_ "GenSigTimeoutTime_HU_B" SG_ 300 IdleSpdLiftUpIntrvntn 0;
BA_ "GenSigTimeoutTime_HU_A" SG_ 300 IdleSpdLiftUpIntrvntn 0;
BA_ "GenSigTimeoutMsg_HU_Mid_X451" SG_ 300 IdleSpdLiftUpIntrvntn 0;
BA_ "GenSigTimeoutMsg_HU_High_X451" SG_ 300 IdleSpdLiftUpIntrvntn 0;
BA_ "GenSigTimeoutMsg_HU_B" SG_ 300 IdleSpdLiftUpIntrvntn 0;
BA_ "GenSigTimeoutMsg_HU_A" SG_ 300 IdleSpdLiftUpIntrvntn 0;
BA_ "GenSigSendType" SG_ 300 IdleSpdLiftUpIntrvntn 7;
BA_ "GenSigCycleTimeActive" SG_ 300 IdleSpdLiftUpIntrvntn 10;
BA_ "GenSigCycleTime" SG_ 300 IdleSpdLiftUpIntrvntn 10;
BA_ "GenSigTimeoutTime_HU_Mid_X451" SG_ 300 IdleSpdLiftUpIntrvntnStatus 0;
BA_ "GenSigTimeoutTime_HU_High_X451" SG_ 300 IdleSpdLiftUpIntrvntnStatus 0;
BA_ "GenSigTimeoutTime_HU_B" SG_ 300 IdleSpdLiftUpIntrvntnStatus 0;
BA_ "GenSigTimeoutTime_HU_A" SG_ 300 IdleSpdLiftUpIntrvntnStatus 0;
BA_ "GenSigTimeoutMsg_HU_Mid_X451" SG_ 300 IdleSpdLiftUpIntrvntnStatus 0;
BA_ "GenSigTimeoutMsg_HU_High_X451" SG_ 300 IdleSpdLiftUpIntrvntnStatus 0;
BA_ "GenSigTimeoutMsg_HU_B" SG_ 300 IdleSpdLiftUpIntrvntnStatus 0;
BA_ "GenSigTimeoutMsg_HU_A" SG_ 300 IdleSpdLiftUpIntrvntnStatus 0;
BA_ "GenSigSendType" SG_ 300 IdleSpdLiftUpIntrvntnStatus 7;
BA_ "GenSigCycleTimeActive" SG_ 300 IdleSpdLiftUpIntrvntnStatus 10;
BA_ "GenSigCycleTime" SG_ 300 IdleSpdLiftUpIntrvntnStatus 10;
BA_ "GenSigTimeoutTime_HU_B" SG_ 300 GearBoxMode 0;
BA_ "GenSigTimeoutTime_HU_A" SG_ 300 GearBoxMode 0;
BA_ "GenSigTimeoutMsg_HU_B" SG_ 300 GearBoxMode 0;
BA_ "GenSigTimeoutMsg_HU_A" SG_ 300 GearBoxMode 0;
BA_ "GenSigSendType" SG_ 300 GearBoxMode 7;
BA_ "GenSigCycleTimeActive" SG_ 300 GearBoxMode 10;
BA_ "GenSigCycleTime" SG_ 300 GearBoxMode 10;
BA_ "GenSigSendType" SG_ 300 TCUTxEngSpdMsgRollCnt 7;
BA_ "GenSigCycleTimeActive" SG_ 300 TCUTxEngSpdMsgRollCnt 10;
BA_ "GenSigCycleTime" SG_ 300 TCUTxEngSpdMsgRollCnt 10;
BA_ "GenSigSendType" SG_ 300 GearShftLvrPosDct 7;
BA_ "GenSigCycleTimeActive" SG_ 300 GearShftLvrPosDct 10;
BA_ "GenSigCycleTime" SG_ 300 GearShftLvrPosDct 10;
BA_ "GenSigSendType" SG_ 300 TCUTxEngSpdMsgCRC 7;
BA_ "GenSigCycleTimeActive" SG_ 300 TCUTxEngSpdMsgCRC 10;
BA_ "GenSigCycleTime" SG_ 300 TCUTxEngSpdMsgCRC 10;
BA_ "GenSigStartValue" SG_ 352 EngTrqAct 1;
BA_ "GenSigSendType" SG_ 352 EngTrqAct 7;
BA_ "GenSigCycleTimeActive" SG_ 352 EngTrqAct 20;
BA_ "GenSigCycleTime" SG_ 352 EngTrqAct 20;
BA_ "GenSigSendType" SG_ 352 GearReqMax 7;
BA_ "GenSigCycleTimeActive" SG_ 352 GearReqMax 20;
BA_ "GenSigCycleTime" SG_ 352 GearReqMax 20;
BA_ "GenSigSendType" SG_ 352 EmsAccState 7;
BA_ "GenSigCycleTimeActive" SG_ 352 EmsAccState 20;
BA_ "GenSigCycleTime" SG_ 352 EmsAccState 20;
BA_ "GenSigTimeoutTime_HU_B" SG_ 352 TCsDTcAck 0;
BA_ "GenSigTimeoutTime_HU_A" SG_ 352 TCsDTcAck 0;
BA_ "GenSigTimeoutMsg_HU_B" SG_ 352 TCsDTcAck 0;
BA_ "GenSigTimeoutMsg_HU_A" SG_ 352 TCsDTcAck 0;
BA_ "GenSigSendType" SG_ 352 TCsDTcAck 7;
BA_ "GenSigCycleTimeActive" SG_ 352 TCsDTcAck 20;
BA_ "GenSigCycleTime" SG_ 352 TCsDTcAck 20;
BA_ "GenSigSendType" SG_ 352 ClutPressEMSStatus 7;
BA_ "GenSigCycleTimeActive" SG_ 352 ClutPressEMSStatus 20;
BA_ "GenSigCycleTime" SG_ 352 ClutPressEMSStatus 20;
BA_ "GenSigSendType" SG_ 352 ClutPressStateEMS 7;
BA_ "GenSigCycleTimeActive" SG_ 352 ClutPressStateEMS 20;
BA_ "GenSigCycleTime" SG_ 352 ClutPressStateEMS 20;
BA_ "GenSigSendType" SG_ 352 VehSpdEMSStatus 7;
BA_ "GenSigCycleTimeActive" SG_ 352 VehSpdEMSStatus 20;
BA_ "GenSigCycleTime" SG_ 352 VehSpdEMSStatus 20;
BA_ "GenSigSendType" SG_ 352 ClutPressEMSStatusNew 7;
BA_ "GenSigCycleTimeActive" SG_ 352 ClutPressEMSStatusNew 20;
BA_ "GenSigCycleTime" SG_ 352 ClutPressEMSStatusNew 20;
BA_ "GenSigSendType" SG_ 352 VehSpdEMS 7;
BA_ "GenSigCycleTimeActive" SG_ 352 VehSpdEMS 20;
BA_ "GenSigCycleTime" SG_ 352 VehSpdEMS 20;
BA_ "GenSigTimeoutTime_HU_B" SG_ 352 ModeSelectionSwStateEMSstatusNew 0;
BA_ "GenSigTimeoutTime_HU_A" SG_ 352 ModeSelectionSwStateEMSstatusNew 0;
BA_ "GenSigTimeoutMsg_HU_B" SG_ 352 ModeSelectionSwStateEMSstatusNew 0;
BA_ "GenSigTimeoutMsg_HU_A" SG_ 352 ModeSelectionSwStateEMSstatusNew 0;
BA_ "GenSigSendType" SG_ 352 ModeSelectionSwStateEMSstatusNew 7;
BA_ "GenSigCycleTimeActive" SG_ 352 ModeSelectionSwStateEMSstatusNew 20;
BA_ "GenSigCycleTime" SG_ 352 ModeSelectionSwStateEMSstatusNew 20;
BA_ "GenSigSendType" SG_ 352 ClutPressStateEMSNew 7;
BA_ "GenSigCycleTimeActive" SG_ 352 ClutPressStateEMSNew 20;
BA_ "GenSigCycleTime" SG_ 352 ClutPressStateEMSNew 20;
BA_ "GenSigTimeoutTime_HU_B" SG_ 352 ModeSelectionSwStateEMSNew 0;
BA_ "GenSigTimeoutTime_HU_A" SG_ 352 ModeSelectionSwStateEMSNew 0;
BA_ "GenSigTimeoutMsg_HU_B" SG_ 352 ModeSelectionSwStateEMSNew 0;
BA_ "GenSigTimeoutMsg_HU_A" SG_ 352 ModeSelectionSwStateEMSNew 0;
BA_ "GenSigSendType" SG_ 352 ModeSelectionSwStateEMSNew 7;
BA_ "GenSigCycleTimeActive" SG_ 352 ModeSelectionSwStateEMSNew 20;
BA_ "GenSigCycleTime" SG_ 352 ModeSelectionSwStateEMSNew 20;
BA_ "GenSigTimeoutTime_HU_B" SG_ 356 HCURequest 0;
BA_ "GenSigTimeoutTime_HU_A" SG_ 356 HCURequest 0;
BA_ "GenSigTimeoutMsg_HU_B" SG_ 356 HCURequest 0;
BA_ "GenSigTimeoutMsg_HU_A" SG_ 356 HCURequest 0;
BA_ "GenSigSendType" SG_ 356 HCURequest 7;
BA_ "GenSigCycleTimeActive" SG_ 356 HCURequest 20;
BA_ "GenSigCycleTime" SG_ 356 HCURequest 20;
BA_ "GenSigTimeoutTime_HU_B" SG_ 356 RadFanOn 0;
BA_ "GenSigTimeoutTime_HU_A" SG_ 356 RadFanOn 0;
BA_ "GenSigTimeoutMsg_HU_B" SG_ 356 RadFanOn 0;
BA_ "GenSigTimeoutMsg_HU_A" SG_ 356 RadFanOn 0;
BA_ "GenSigSendType" SG_ 356 RadFanOn 7;
BA_ "GenSigCycleTimeActive" SG_ 356 RadFanOn 20;
BA_ "GenSigCycleTime" SG_ 356 RadFanOn 20;
BA_ "GenSigTimeoutTime_HU_B" SG_ 356 HCUStopReq 0;
BA_ "GenSigTimeoutTime_HU_A" SG_ 356 HCUStopReq 0;
BA_ "GenSigTimeoutMsg_HU_B" SG_ 356 HCUStopReq 0;
BA_ "GenSigTimeoutMsg_HU_A" SG_ 356 HCUStopReq 0;
BA_ "GenSigSendType" SG_ 356 HCUStopReq 7;
BA_ "GenSigCycleTimeActive" SG_ 356 HCUStopReq 20;
BA_ "GenSigCycleTime" SG_ 356 HCUStopReq 20;
BA_ "GenSigTimeoutTime_HU_B" SG_ 359 AltTrq 0;
BA_ "GenSigTimeoutTime_HU_A" SG_ 359 AltTrq 0;
BA_ "GenSigTimeoutMsg_HU_B" SG_ 359 AltTrq 0;
BA_ "GenSigTimeoutMsg_HU_A" SG_ 359 AltTrq 0;
BA_ "GenSigSendType" SG_ 359 AltTrq 7;
BA_ "GenSigCycleTimeActive" SG_ 359 AltTrq 20;
BA_ "GenSigCycleTime" SG_ 359 AltTrq 20;
BA_ "GenSigStartValue" SG_ 368 EngTrqInc 8192;
BA_ "GenSigSendType" SG_ 368 EngTrqInc 7;
BA_ "GenSigCycleTimeActive" SG_ 368 EngTrqInc 20;
BA_ "GenSigCycleTime" SG_ 368 EngTrqInc 20;
BA_ "GenSigSendType" SG_ 368 EngTrqIncStatus 7;
BA_ "GenSigCycleTimeActive" SG_ 368 EngTrqIncStatus 20;
BA_ "GenSigCycleTime" SG_ 368 EngTrqIncStatus 20;
BA_ "GenSigTimeoutTime_HU_B" SG_ 368 EngTrqLimFast 0;
BA_ "GenSigTimeoutTime_HU_A" SG_ 368 EngTrqLimFast 0;
BA_ "GenSigTimeoutMsg_HU_B" SG_ 368 EngTrqLimFast 0;
BA_ "GenSigTimeoutMsg_HU_A" SG_ 368 EngTrqLimFast 0;
BA_ "GenSigStartValue" SG_ 368 EngTrqLimFast 8192;
BA_ "GenSigSendType" SG_ 368 EngTrqLimFast 7;
BA_ "GenSigCycleTimeActive" SG_ 368 EngTrqLimFast 20;
BA_ "GenSigCycleTime" SG_ 368 EngTrqLimFast 20;
BA_ "GenSigTimeoutTime_HU_B" SG_ 368 EngTrqLimFastStatus 0;
BA_ "GenSigTimeoutTime_HU_A" SG_ 368 EngTrqLimFastStatus 0;
BA_ "GenSigTimeoutMsg_HU_B" SG_ 368 EngTrqLimFastStatus 0;
BA_ "GenSigTimeoutMsg_HU_A" SG_ 368 EngTrqLimFastStatus 0;
BA_ "GenSigSendType" SG_ 368 EngTrqLimFastStatus 7;
BA_ "GenSigCycleTimeActive" SG_ 368 EngTrqLimFastStatus 20;
BA_ "GenSigCycleTime" SG_ 368 EngTrqLimFastStatus 20;
BA_ "GenSigTimeoutTime_HU_B" SG_ 368 EngTrqLimSlow 0;
BA_ "GenSigTimeoutTime_HU_A" SG_ 368 EngTrqLimSlow 0;
BA_ "GenSigTimeoutMsg_HU_B" SG_ 368 EngTrqLimSlow 0;
BA_ "GenSigTimeoutMsg_HU_A" SG_ 368 EngTrqLimSlow 0;
BA_ "GenSigStartValue" SG_ 368 EngTrqLimSlow 8192;
BA_ "GenSigSendType" SG_ 368 EngTrqLimSlow 7;
BA_ "GenSigCycleTimeActive" SG_ 368 EngTrqLimSlow 20;
BA_ "GenSigCycleTime" SG_ 368 EngTrqLimSlow 20;
BA_ "GenSigTimeoutTime_HU_B" SG_ 368 EngTrqLimSlowStatus 0;
BA_ "GenSigTimeoutTime_HU_A" SG_ 368 EngTrqLimSlowStatus 0;
BA_ "GenSigTimeoutMsg_HU_B" SG_ 368 EngTrqLimSlowStatus 0;
BA_ "GenSigTimeoutMsg_HU_A" SG_ 368 EngTrqLimSlowStatus 0;
BA_ "GenSigSendType" SG_ 368 EngTrqLimSlowStatus 7;
BA_ "GenSigCycleTimeActive" SG_ 368 EngTrqLimSlowStatus 20;
BA_ "GenSigCycleTime" SG_ 368 EngTrqLimSlowStatus 20;
BA_ "GenSigTimeoutTime_HU_B" SG_ 368 EngTrqMsgRollCnt 0;
BA_ "GenSigTimeoutTime_HU_A" SG_ 368 EngTrqMsgRollCnt 0;
BA_ "GenSigTimeoutMsg_HU_B" SG_ 368 EngTrqMsgRollCnt 0;
BA_ "GenSigTimeoutMsg_HU_A" SG_ 368 EngTrqMsgRollCnt 0;
BA_ "GenSigSendType" SG_ 368 EngTrqMsgRollCnt 7;
BA_ "GenSigCycleTimeActive" SG_ 368 EngTrqMsgRollCnt 20;
BA_ "GenSigCycleTime" SG_ 368 EngTrqMsgRollCnt 20;
BA_ "GenSigTimeoutTime_HU_B" SG_ 368 EngTrqMsgCRC 0;
BA_ "GenSigTimeoutTime_HU_A" SG_ 368 EngTrqMsgCRC 0;
BA_ "GenSigTimeoutMsg_HU_B" SG_ 368 EngTrqMsgCRC 0;
BA_ "GenSigTimeoutMsg_HU_A" SG_ 368 EngTrqMsgCRC 0;
BA_ "GenSigSendType" SG_ 368 EngTrqMsgCRC 7;
BA_ "GenSigCycleTimeActive" SG_ 368 EngTrqMsgCRC 20;
BA_ "GenSigCycleTime" SG_ 368 EngTrqMsgCRC 20;
VAL_ 579 VcuHazardLampReqStatus 3 "Reserved" 2 "Information given is implausible due to a detected failure" 1 "Reserved" 0 "Information given correct and according to specification" ;
VAL_ 579 VcuHazardLampReq 1 "Request to activate Hazard Lamp" 0 "No Request for Hazard Lamp" ;
VAL_ 579 VCuPresence 1 "Reserved" 0 "VCU is present" ;
VAL_ 579 BrkVacPumpStatus 1 "Brake Vaccum Pump Malfunction" 0 "Brake Vaccum Pump Normal" ;
VAL_ 579 DriveMotorStatus 1 "Drive Motor Malfunction" 0 "Drive Motor  Normal" ;
VAL_ 579 HvBattSoh 1 "HV Batt SOH Not OK" 0 "HV Batt SOH OK" ;
VAL_ 579 HvBattPackVolStatus 3 "Reserved" 2 "Information is implausible due to a detected failure " 1 "Reserved" 0 "Information is correct and according to specification" ;
VAL_ 579 AvgEnergyConsmption 511 "Information Initialization in progress due to Reset" ;
VAL_ 579 AvgEnergyConsmptionStatus 3 "Signal Not Available" 2 "Information given is implausible due to a detected failure" 1 "Reserved" 0 "Information given is correct and according to specification" ;
VAL_ 579 MotorHightempStatus 3 "Reserved" 2 "Information given is implausible due to a detected failure" 1 "Reserved" 0 "Information given is correct and according to specification" ;
VAL_ 579 MotorHightemp 3 " Reserved for future use" 2 "Motor Temp lamp ON" 1 "Motor Temp lamp Flashing" 0 "Motor Temp lamp is OFF. " ;
VAL_ 579 VcuGearSelectionChangeTxt 3 "Low SoC, Sports mode De-Activated" 2 "Gear Selections selection is not possible due to System failure" 1 "Press The Brake for Gear selection " 0 "Gear selection possible" ;
VAL_ 579 ImmoStatusVcu 1 "VCU is immobilized" 0 "VCU is mobilized" ;
VAL_ 579 ClntTempVcuStatus 3 "Reserved for future use" 2 "Value is implausible" 1 "Reserved for future use" 0 "ClntTemp signal is correct" ;
VAL_ 579 GearForDisplayVcu 15 "Information Initialization in progress" 14 "Reserved" 13 "Reserved" 12 "Reserved" 11 "Reserved" 10 "Reserved" 9 "Reserved" 8 "Reserved" 7 "Reserved" 6 "Reserved" 5 "Sport" 4 "Forward/Drive" 3 "Neutral" 2 "Reverse" 1 "Park" 0 "Not Used" ;
VAL_ 579 GearForDisplayVcuStatus 3 "Signal Not Available" 2 "Information given is implausible due to a detected failure" 1 "Reserved" 0 "Information given correct and according to specification" ;
VAL_ 273 CurrentTorqueAtMotorStatus 3 "Reserved" 2 "Information given is implausible" 1 "Reserved" 0 "Information given is correct" ;
VAL_ 273 RecuprationActualTorqueStatus 3 "Reserved" 2 "Information given is implausible" 1 "Reserved" 0 "Information given is correct" ;
VAL_ 273 CurrentTorqueToWheelStatus 3 "Reserved for future use" 2 "Information given  is implausible" 1 "Reserved for future use" 0 "Information given is correct " ;
VAL_ 273 AccPedPosnVcuStatus 3 "Reserved" 2 "Information given is implausible" 1 "Reserved" 0 "Information given is correct" ;
VAL_ 273 BrkPressStateVcu 1 "Brake is not pressed" 0 "Brake is pressed" ;
VAL_ 273 BrkPressStatusVcu 3 "Reserved" 2 "Information given is implausible due to a detected failure" 1 "Reserved" 0 "Information given is correct and according to specification" ;
VAL_ 192 TRIM 1 "Sensor Trimmed" 0 "Sensor Not trimmed" ;
VAL_ 192 OK 1 "Sensor Informatio is valid" 0 "Sensor Information is invalid, Internal sensor failure occurred" ;
VAL_ 192 CAL 1 "SAS Sensor is calibrated" 0 "SAS Sensor not calibrated" ;
VAL_ 256 MCU_LOCK_STATUS 1 "EMS/MCU is locked" 0 "EMS/MCU is unlocked" ;
VAL_ 256 MCU_KEY_REQUEST 1 "EMS request PEPS to look again for a valid key" 0 "EMS have no request" ;
VAL_ 256 MCU_INTERN_STATUS 3 "EMS/MCu is learned and working (AES SK code known)" 2 "EMS/MCU is in unexpected unknown states" 1 "AES_SK is learned, but not locked" 0 "EMS/MCU is blank, AES SK learning required" ;
VAL_ 256 MCU_DATA_FIELD 3 "Data field contains AES SK value for automatic pairing" 2 "Data field contains R5icu" 1 "Data field contains RNmcu" 0 "Data field is empty, or noise" ;
VAL_ 256 ICU_recog_OK 3 "PEPS authenticated" 2 "No authentication running" 1 "No authentication running" 0 "Response R5mcu send by PEPS is not valid" ;
VAL_ 256 Automatic_AES_Key_write 3 "Lock AES key in PEPS Command" 2 "Automatic AES key write sequence Enable" 1 "Automatic AES key write sequence Disable" 0 "PEPS Status Request" ;
VAL_ 256 Automatic_AES_Key_Sequence 3 "Automatic AES key seq_01 (Sk12-Sk15)" 2 "Automatic AES key seq_02 (Sk8-Sk11)" 1 "Automatic AES key seq_03 (Sk4-Sk7)" 0 "Automatic AES key seq_04 (Sk0- Sk3)" ;
VAL_ 257 MCU_recog_OK 3 "EMS/MCU authenticated" 2 "No authentication running" 1 "PEPS is in anti-scanning (request refused)" 0 "Response R5icu send by EMS/MCU is not valid" ;
VAL_ 257 MCU_UNLOCK_AUTHORIZED 1 "EMS/MCU can be unlocked" 0 "EMS/MCU must stay in its current status" ;
VAL_ 257 ICU_KEY_NUMBER 7 "7 Key Learned" 6 "6 Key Learned" 5 "5 Key Learned" 4 "4 Key Learned" 3 "3 Key Learned" 2 "2 Key Learned" 1 "1 Key Learned" 0 "No key learned" ;
VAL_ 257 ICU_KEY_DETECTION 3 "A valid key was detected in the last preconfigured delay" 2 "Valid key no more available after preconfigured delay expires" 1 "Key detection running" 0 "No valid key detected since IGN ON or MCU request" ;
VAL_ 257 ICU_INTERN_STATUS 3 "PEPS is learned (AES SK code known)" 2 "PEPS is in unexpected unknown states" 1 "AES_SK is learned, but not locked" 0 "PEPS is blank, AES SK code learning required" ;
VAL_ 257 ICU_DATA_FIELD 3 "AES key data received in last frame" 2 "Data field contains R5mcu" 1 "Data field contains RNicu" 0 "data field is empty, or noise" ;
VAL_ 257 Automatic_AES_Key_write_ACKLG 7 "Automatic AES key seq_01 (Sk12-Sk15)" 6 "Automatic AES key seq_02 (Sk8-Sk11)" 5 "Automatic AES key seq_03 (Sk4-Sk7)" 4 "Automatic AES key seq_04 (Sk0- Sk3)" 3 "PEPS Locked Feedback" 2 "Auto AES key Acknowledge" 1 "AES key generated" 0 "No Acknowledge" ;
VAL_ 259 CrashOutputSignalStatus 3 "Signal Not Available" 2 "Implausible" 1 "Reserved" 0 "Plausible" ;
VAL_ 259 RrMiddleSeatBeltSwitchState 1 "Not Buckled" 0 "Buckled" ;
VAL_ 259 RrDrvSeatBeltSwitchState 1 "Not Buckled" 0 "Buckled" ;
VAL_ 259 RrPassSeatBeltSwitchState 1 "Not Buckled" 0 "Buckled" ;
VAL_ 259 FrPassSeatBeltSwitchState 1 "Not Buckled" 0 "Buckled" ;
VAL_ 259 FrDrvSeatBeltSwitchState 1 "Not Buckled" 0 "Buckled" ;
VAL_ 259 FrDrvSBRChime 3 "Reserved" 2 "Chime Level 2" 1 "Chime Level 1" 0 "Chime OFF" ;
VAL_ 259 FrDrvSBRIndication 1 "Indicator ON" 0 "Indicator OFF" ;
VAL_ 259 CrashoutputSignal 16 "Left hand side deploy crash" 8 "Right hand side deploy crash" 4 "Rear Crash" 2 "Front Deploy Crash" 1 "No Fire Crash" 0 "No Crash" ;
VAL_ 259 RearDrvSBRChime 3 "reserved" 2 "Chime Level 2" 1 "Chime Level 1" 0 "Chime OFF" ;
VAL_ 259 RearmiddlePassSBRChime 3 "reserved" 2 "Chime Level 2" 1 "Chime Level 1" 0 "Chime OFF" ;
VAL_ 259 FrPassSBRChime 3 "reserved" 2 "Chime Level 2" 1 "Chime Level 1" 0 "Chime OFF" ;
VAL_ 259 RearPassSBRChime 3 "reserved" 2 "Chime Level 2" 1 "Chime Level 1" 0 "Chime OFF" ;
VAL_ 259 RearDrvSBRIndication 1 "Indicator ON" 0 "Indicator OFF" ;
VAL_ 259 RearmiddlePassSBRIndication 1 "Indicator ON" 0 "Indicator OFF" ;
VAL_ 259 RearPassSBRIndication 1 "Indicator ON" 0 "Indicator OFF" ;
VAL_ 259 FrPassSBRIndication 1 "Indicator ON" 0 "Indicator OFF" ;
VAL_ 259 SRSWarningLamp 1 "AWL ON" 0 "AWL OFF" ;
VAL_ 259 PassAirbagDeActIndi 1 "PADI ON" 0 "PADI OFF" ;
VAL_ 260 EngTrqMeStatus 3 "Signal not available" 2 "EngTrqME signal is implausible" 1 "Reserved for future use" 0 "EngTrqMe is correct" ;
VAL_ 260 EngTrqLossStatus 3 "Signal not available" 2 "Value is implausible" 1 "Reserved" 0 "Value is valid" ;
VAL_ 260 EngTrqMaxStatus 3 "Signal not available" 2 "Value is impluasible" 1 "Reserved" 0 "Value is valid" ;
VAL_ 260 EngTrqTgtWoTcuStatus 3 "Signal not avilable" 2 "Value is implausible" 1 "Reserved" 0 "Value is valid" ;
VAL_ 262 BrkPressStatus 3 "Signal not available" 2 "Value is implausible" 1 "Reserved for future" 0 "Value is correct" ;
VAL_ 262 BrkPressState 1 "Brake pedal Released" 0 "Brake pedal pressed" ;
VAL_ 262 EngSpdStatus 3 "Reserved for future use" 2 "Value is implausible" 1 "Reserved for future use" 0 "EngSpd signal is correct" ;
VAL_ 262 AccPedRocStatus 3 "Signal not available" 2 "Signal  AccPedROC is implausible" 1 "Reserved for future use" 0 "Signal  AccPedROC is correct" ;
VAL_ 262 EngIdleSpdStatus 3 "Signal not available" 2 "Value is implausible" 1 "Reserved" 0 "Value is correct" ;
VAL_ 262 AccPedPosnStatus 3 "Signal not available" 2 "AccPedPosn signal value is implausible" 1 "Reserved for future use" 0 "Signal AccPedPosn is correct " ;
VAL_ 264 EngTrqDrvrReqStatus 3 "Reserved" 2 "Signal is implausible" 1 "Reserved " 0 "Signal is correct" ;
VAL_ 264 EmsRecovery 128 "Single Pedal track fault" 64 "Coolant sensor fault" 32 "Eng Trq Accuracy > +/-10%" 16 "Eng Trq Accuracy < +/-10%" 8 "Engine start disabled" 4 "Limp home(Pedal)" 2 "Reduced Trq Mode" 1 "Engine Stopped" 0 "Normal Mode" ;
VAL_ 264 CreepInhibitCmd 128 "TBD" 64 "TBD" 32 "TBD" 16 "TBD" 8 "TBD" 4 "TBD" 2 "TBD" 1 "Disable Creeping" 0 "Allow Creeping" ;
VAL_ 264 ModeSelectionSwStateEMSstatus 3 "Signal is not availalbe" 2 "Signal value is implausible" 1 "Reserved" 0 "Signal value is plausible" ;
VAL_ 264 CruiseState 3 "Function not present" 2 "Cruise is Enabled and Inactive" 1 "Cruise is  enabled and active" 0 "Cruise is  disabled" ;
VAL_ 264 CruiseOverride 3 "Not applicable or  Not supported" 2 "Reserved" 1 "Cruise override is active" 0 "Cruise override is not active" ;
VAL_ 264 CanErrEms 3 "Implausible commmand received from  TCU" 2 "Implausible CAN frames received  from TCU " 1 "CAN frames not received from TCU unit" 0 "No CAN error" ;
VAL_ 264 VirtualThrottleStatus 3 "Signal not available" 2 "Value is implausible " 1 "Reserved for future use" 0 "Signal is correct" ;
VAL_ 264 ModeSelectionSwStateEMS 7 "Reserved" 6 "Reserved" 5 "Reserved" 4 "Reserved" 3 "Reserved" 2 "Economy Mode" 1 "Sports Mode" 0 "Normal / City Mode" ;
VAL_ 266 GenDenominator 1 "True" 0 "False" ;
VAL_ 266 EngTrqPlaus 1 "Error on Torque measurement / Calculation" 0 "No Error on Torque Measurement / Calculation" ;
VAL_ 266 EngFuelcutoff 1 "Engine in Fuel Cut off" 0 "Engine not in fuel cut off" ;
VAL_ 266 EMSThrtlPosStatus 3 "Reserved for future use" 2 "Implausible" 1 "Reserved for future use" 0 "Plausible" ;
VAL_ 266 IntakeAirTempStatus 3 "Reserved for future use" 2 "Implausible" 1 "Reserved for future use" 0 "Plausible" ;
VAL_ 268 LeadingEngTrqStatus 3 "Reserved for Future used Not applicable or  Not supported" 2 "information given at EngTorqMe is implausible due to a detected failure at EMS ECU" 1 "Reserved for Future used" 0 "information given at EngTorqMe is correct and according to specification" ;
VAL_ 268 EstEngTrqStatus 3 "Signal is not available" 2 "Signal value is implausible" 1 "Reserved" 0 "Signal value is plausible" ;
VAL_ 270 GenDenominator 1 "True" 0 "False" ;
VAL_ 270 DynEngTrqMaxStatus 3 "Signal is not available" 2 "Signal value is implausible" 1 "Reserved" 0 "Signal value is plausible" ;
VAL_ 270 EngTrqMinWOfuelcutStatus 3 "Signal is not available" 2 "Signal value is implausible" 1 "Reserved" 0 "Signal value is plausible" ;
VAL_ 270 EngWarmupReq 1 "Engine warmup support request active" 0 "Engine warmup support request inactive" ;
VAL_ 270 PwrTrnOpenReq 1 "Opening request" 0 "No request" ;
VAL_ 270 FuelCutOffTCU 1 "TCU allowed to make fuel cut off request" 0 "TCU not allowed to make fuel cut off request" ;
VAL_ 277 SteerAngEPAsDir 1 "Counter Clockwise Direct" 0 "Clockwise Direction" ;
VAL_ 277 SteerAngEPASStatus 3 "Reserved" 2 "Signal is implausible" 1 "Reserved " 0 "Signal is correct" ;
VAL_ 288 RESSEnableStatus 3 "Signal Not available" 2 "Information given  is implausible" 1 "Reserved for future use" 0 "Information given is correct and according to specification" ;
VAL_ 288 RESSEnable 1 "RESSEnable active" 0 "RESSEnable deactive" ;
VAL_ 288 EngTrqReqStatus 3 "signal not available" 2 "Value is implausible" 1 "Reserved" 0 "Value is plausible" ;
VAL_ 288 CluEngagedStatus 3 "Signal not available" 2 "Value is implausible" 1 "Reserved" 0 "Value is plausible" ;
VAL_ 288 CluEngagedTCU 3 "open/disengaged" 2 "clutchslipping after disengaging" 1 "clutchslipping before engagement" 0 "closed" ;
VAL_ 288 TransLimpHomeActive 1 "Limp home active" 0 "Limp home not active" ;
VAL_ 288 EngStopReq 1 "req active" 0 "req not active" ;
VAL_ 288 CrnkEnable 1 "Enabled" 0 "Disabled" ;
VAL_ 288 EngTrqCtrlActive 1 "Eng torque control active" 0 "Eng torque control inactive" ;
VAL_ 288 HydraulicPumpActive 1 "Hydrauclic Pump Relay On" 0 "Hydraulic Pump Relay Off" ;
VAL_ 288 ReqTrqValueActive 1 "Engine speed ctrl active" 0 "Engine speed ctrl not active" ;
VAL_ 288 EngTrqIncActive 1 "torque increase request active" 0 "torque increase request inactive" ;
VAL_ 288 EngTrqRednActive 1 "Trq reduction request active" 0 "Trq reduction request inactive" ;
VAL_ 288 CurGearTcuStatus 3 "Signal not available" 2 "Value is implausible" 1 "Reserved " 0 "Value is plausible" ;
VAL_ 288 CurGearTcu 15 "Reserved" 14 "Reserved" 13 "Reserved" 12 "Reserved" 11 "Reserved" 10 "Reserved" 9 "Reserved" 8 "Reverse gear" 7 "Sixth gear" 6 "Fifth gear" 5 "Fourth gear" 4 "Third gear" 3 "Second gear" 2 "First gear" 1 "Neutral" 0 "Reserved " ;
VAL_ 290 CreepingCluTgtTrqStatus 3 "Signal not available" 2 "Value is implausible" 1 "Reserved" 0 "Value is plausible" ;
VAL_ 290 CreepingCluTrqStatus 3 "Signal not available" 2 "Value is implausible" 1 "Reserved" 0 "Value is plausible" ;
VAL_ 290 CreepingEnable 1 "Creeping Phase active" 0 "Creeping Phase inactive" ;
VAL_ 290 TargGearPos 7 "Reverse Gear" 6 "Sixth Gear" 5 "Fifth Gear" 4 "Fourth Gear" 3 "Third Gear" 2 "Second Gear" 1 "First Gear" 0 "No gear engaged / Neutral" ;
VAL_ 290 TargGearPosStatus 3 "Reserved for future" 2 "Value is implausible" 1 "Reserved for future" 0 "Value is plausible" ;
VAL_ 290 GearBoxModestatus 3 "Signal not available" 2 "value is implausible" 1 "Reserved" 0 "Value is plausible" ;
VAL_ 290 GearBoxMode 7 "Reserved" 6 "Reserved" 5 "Auto Economy" 4 "Auto Sports" 3 "Auto Normal / City" 2 "Tiptronic Eco Mode" 1 "Tiptronic Sports Mode" 0 "Tiptronic Normal / City Mode" ;
VAL_ 290 AutoTransGrSftDirectFl 1 "TRUE" 0 "FALSE" ;
VAL_ 290 AutoTransGrSftDirect 3 "Reserved" 2 "Downshift in progress" 1 "Upshift in progress" 0 "No shift in progress" ;
VAL_ 291 ReserveTorqueRequestIntervention 1 "Torque reserve requested" 0 "No Torque reserve" ;
VAL_ 291 DctPepsLockState 3 "Unlocked: Locking is not active." 2 "Unlocking: The TCU is in the process of unlocking the Park-position. This is typically during the authentication sequence PEPS" 1 "Locked: transmission is in the Park-position and will only allow a gear-change after a successfull authentication sequence PEPS" 0 "not used" ;
VAL_ 291 RESSEnableDctStatus 3 "Signal Not available" 2 "Information given  is implausible" 1 "Reserved for future use" 0 "Information given is correct and according to specification" ;
VAL_ 291 RESSEnableDct 1 "RESSEnable active" 0 "RESSEnable deactive" ;
VAL_ 291 CreepState 1 "CREEP ACTIVE" 0 "CREEP INACTIVE" ;
VAL_ 291 TransLimpHomeActive 1 "Limp home active" 0 "Limp home not active" ;
VAL_ 291 FastTrqIntrvntnStatus 3 "Signal is not available" 2 "Signal value is implausible" 1 "Reserved" 0 "Signal value is plausible" ;
VAL_ 291 FastTrqIntrvntn 3 "Reserved for future " 2 "Fast torque increase" 1 "Fast torque reduction" 0 "No fast torque Intervention" ;
VAL_ 291 SlowTrqIntrvntnStatus 3 "Signal is not available" 2 "Signal value is implausible" 1 "Reserved" 0 "Signal value is plausible" ;
VAL_ 291 SlowTrqIntrvntn 3 "Reserved for future " 2 "Slow torque increase" 1 "Slow torque reduction" 0 "No Slow torque Intervention" ;
VAL_ 291 AutoTransGrSftDirect 3 "Reserved" 2 "Downshift in progress" 1 "Upshift in progress" 0 "No shift in progress" ;
VAL_ 291 CurGearDctStatus 3 "Signal not available" 2 "Value is implausible" 1 "Reserved " 0 "Value is plausible" ;
VAL_ 291 CurGearDct 15 "Reserved" 14 "Reverse gear" 13 "Reserved" 12 "Reserved" 11 "Reserved" 10 "Reserved" 9 "Reserved" 8 "Seventh Gear" 7 "Sixth gear" 6 "Fifth gear" 5 "Fourth gear" 4 "Third gear" 3 "Second gear" 2 "First gear" 1 "Neutral" 0 "Park" ;
VAL_ 291 TargGearPosDctStatus 3 "Signal is not available" 2 "Signal value is implausible" 1 "Reserved" 0 "Signal value is plausible" ;
VAL_ 291 TargGearPosDct 15 "Reserved" 14 "Reverse gear" 13 "Reserved" 12 "Reserved" 11 "Reserved" 10 "Reserved" 9 "Reserved" 8 "Seventh  gear" 7 "sixth gear" 6 "fifth gear" 5 "fourth gear" 4 "third gear" 3 "second gear" 2 "first gear" 1 "neutral" 0 "Reserved" ;
VAL_ 291 AutoTransGrSftDirectFl 1 "TRUE" 0 "FALSE" ;
VAL_ 383 IMGSMPosReq 15 "Un-confirmed position" 14 "Fault" 13 "Interrupt 2" 12 "Interrupt 1" 11 "RESERVED" 10 "RESERVED" 9 "Sport request Repeat" 8 "Drive request Repeat" 7 "Neutral request Repeat" 6 "Reverse request Repeat" 5 "Park request Repeat" 4 "Sport request" 3 "Drive request" 2 "Neutral request" 1 "Reverse request" 0 "Park Request" ;
VAL_ 294 TcuAccState 3 "Reserved" 2 "Fault" 1 "Active" 0 "Inactive" ;
VAL_ 294 CurGearTcuAT 15 "Reserved" 14 "Reverse gear" 13 "Reserved" 12 "Reserved" 11 "Reserved" 10 "Reserved" 9 "Reserved" 8 "Reserved" 7 "sixth gear" 6 "fifth gear" 5 "fourth gear" 4 "third gear" 3 "second gear	

" 2 "first gear" 1 "neutral" 0 "Reserved" ;
VAL_ 294 TargGearTCU 15 "Reserved" 14 "Reverse gear" 13 "Reserved" 12 "Reserved" 11 "Reserved" 10 "Reserved" 9 "Reserved" 8 "Reserved" 7 "sixth gear" 6 "fifth gear" 5 "fourth gear" 4 "third gear" 3 "second gear" 2 "first gear" 1 "neutral" 0 "Reserved" ;
VAL_ 294 CurrGearTcuATStatus 3 "Signal is not available" 2 "Signal value is implausible" 1 "Reserved" 0 "Signal value is plausible" ;
VAL_ 294 ClutConvState 3 "Coast lock up(Sleep)" 2 "Fully lock up " 1 "Slip lock up " 0 "No lock up control " ;
VAL_ 294 TargGearTCUStatus 3 "Signal is not available" 2 "Signal value is implausible" 1 "Reserved" 0 "Signal value is plausible" ;
VAL_ 294 GearShftActive 1 "gear change is active" 0 "no gear change " ;
VAL_ 294 TCuMILReq 1 "MIL on request" 0 "No MIL on request" ;
VAL_ 294 TCU_NIC_State 3 "NIC Exit (TCU exit the NIC)" 2 "In neutral (TCU is in Neutral)" 1 "NIC Start ( TCU start to enter NIC)" 0 "NIC OFF  (TCU is not in NIC state)" ;
VAL_ 294 EngSpdReqStatus 1 "Engine speed increase is requested" 0 "No request " ;
VAL_ 296 GearShftLvrPos 15 "Reserved" 14 "Intermediate Position" 13 "Reserved" 12 "Reserved" 11 "Sports mode" 10 "Tiptronic Down" 9 "Tiptronic UP" 8 "Manual" 7 "Reverse position" 6 "neutral position" 5 "Drive position" 4 "Reserved" 3 "Reserved" 2 "Reserved" 1 "Reserved" 0 "Park Position" ;
VAL_ 296 GearBoxModeNew 15 "Reserved" 14 "Reserved" 13 "Reserved" 12 "Reserved" 11 "Reserved" 10 "Reserved" 9 "Reserved" 8 "Manual mode" 7 "Rough Road" 6 "Wet/Rain" 5 "Sand" 4 "Mud / Ruts " 3 "Gravel/Grass/Snow" 2 "Economy mode" 1 "Sport mode" 0 "Normal/City mode" ;
VAL_ 296 InhFuelCutOff 1 "request from TCU to inhibit the fuel cut off" 0 "no request from TCU to inhibit the fuel cut off" ;
VAL_ 296 GearShftLvrPosStatus 3 "Signal is not available" 2 "Signal value is implausible" 1 "Reserved" 0 "Signal value is plausible" ;
VAL_ 296 GearBoxModeNewStatus 3 "Signal is not available" 2 "Signal value is implausible" 1 "Reserved" 0 "Signal value is plausible" ;
VAL_ 298 FastTrqReqStatus 3 "Signal is not available" 2 "Signal value is implausible" 1 "Reserved" 0 "Signal value is plausible" ;
VAL_ 298 SlowTrqReqStatus 3 "Signal is not available" 2 "Signal value is implausible" 1 "Reserved" 0 "Signal value is plausible" ;
VAL_ 298 CluEngagedTcuDCTStatus 3 "Signal is not available" 2 "Signal value is implausible" 1 "Reserved" 0 "Signal value is plausible" ;
VAL_ 298 CrnkEnable 1 "Enabled" 0 "Disabled" ;
VAL_ 298 FuelCutOffTCUReq 1 "Fuel cut-off request" 0 "No  Fuel cut-off request" ;
VAL_ 298 CluEngagedTcuDCT 3 "reserved" 2 "CLOSED" 1 "SLIPPING" 0 "OPEN" ;
VAL_ 300 EngIdleSpdLiftUpReqStatus 3 "Signal is not available" 2 "Signal value is implausible" 1 "Reserved" 0 "Signal value is plausible" ;
VAL_ 300 GearBoxModestatus 3 "Signal not available" 2 "value is implausible" 1 "Reserved" 0 "Value is plausible" ;
VAL_ 300 GearShftLvrPosDctStatus 3 "Signal is not available" 2 "Signal value is implausible" 1 "Reserved" 0 "Signal value is plausible" ;
VAL_ 300 IdleSpdLiftUpIntrvntn 1 "Idle speed Lift up requested" 0 "Idle speed Lift up not requested" ;
VAL_ 300 IdleSpdLiftUpIntrvntnStatus 3 "Signal is not available" 2 "Signal value is implausible" 1 "Reserved" 0 "Signal value is plausible" ;
VAL_ 300 GearBoxMode 7 "Reserved" 6 "Reserved" 5 "Auto Economy" 4 "Auto Sports" 3 "Auto Normal / City" 2 "Tiptronic Eco Mode" 1 "Tiptronic Sports Mode" 0 "Tiptronic Normal / City Mode" ;
VAL_ 300 GearShftLvrPosDct 15 "Reserved" 14 "Intermediate Position" 13 "Reserved" 12 "Reserved" 11 "Sports mode" 10 "Tiptronic Down" 9 "Tiptronic UP" 8 "Manual" 7 "Reverse position" 6 "neutral position" 5 "Drive position" 4 "Reserved" 3 "Reserved" 2 "Reserved" 1 "Reserved" 0 "Park Position" ;
VAL_ 352 EngTrqAct 1 "TRUE" 0 "FALSE" ;
VAL_ 352 GearReqMax 15 "Reserved" 14 "Reserved" 13 "Reserved" 12 "Reserved" 11 "Reserved" 10 "Reserved" 9 "G9" 8 "G8" 7 "G7" 6 "G6" 5 "G5" 4 "G4" 3 "G3" 2 "G2" 1 "G1" 0 "Passive" ;
VAL_ 352 EmsAccState 3 "Reserved" 2 "Fault" 1 "Active" 0 "Inactive" ;
VAL_ 352 TCsDTcAck 1 "Troque control  is possible by EMS." 0 "Torque control is not possible by  EMS" ;
VAL_ 352 ClutPressEMSStatus 3 "Signal not available" 2 "Information given is implausible" 1 "Reserved for future" 0 "Value is plausible" ;
VAL_ 352 ClutPressStateEMS 1 "clutch pedal Released" 0 "clutch pedal pressed" ;
VAL_ 352 VehSpdEMSStatus 3 "Signal not available" 2 "Information is implausible" 1 "Reserved for future use" 0 "Information given  is correct" ;
VAL_ 352 ClutPressEMSStatusNew 3 "Signal not available" 2 "Information given is implausible due to a detected failure at Clutch switch" 1 "Reserved for future" 0 "Information given is correct and according to specification" ;
VAL_ 352 ModeSelectionSwStateEMSstatusNew 3 "Signal is not availalbe" 2 "Signal value is implausible" 1 "Reserved" 0 "Signal value is plausible" ;
VAL_ 352 ClutPressStateEMSNew 3 "Reserved" 2 "Clutch pedal fully pressed state (Top & Bottom inputs available)" 1 "Clutch pedal half pressed state (Top input available & Bottom input not available)" 0 "Clutch pedal released state (Top & Bottom inputs not available)" ;
VAL_ 352 ModeSelectionSwStateEMSNew 15 "Reserved" 14 "Reserved" 13 "Reserved" 12 "Reserved" 11 "Reserved" 10 "Reserved" 9 "Reserved" 8 "Reserved" 7 "Rough Road" 6 "Wet/Rain" 5 "Sand" 4 "Mud / Ruts / Gravel" 3 "Grass / Snow" 2 "Economy mode" 1 "Sport mode" 0 "Normal/City mode" ;
VAL_ 356 HCURequest 3 "HCU failure mode EMS to continue normal operation. " 2 "HCU failure mode EMS to switch on battery not charging lam" 1 "Advance signal to EMS requesting to be prepared for stop." 0 "Advance signal to EMS requesting to be prepared for cranking" ;
VAL_ 356 RadFanOn 1 "Request Radiator fan to switch on" 0 "No Fan request" ;
VAL_ 356 HCUStopReq 1 "Engine stop through fuel cut off " 0 "No fuel cut off request" ;
VAL_ 368 EngTrqIncStatus 3 "Signal is not available" 2 "Value is impluasible due to detected Failure at brake system" 1 "Signal is Correctt.Dragtrqcontrol active.Trqintervention requested" 0 "Value  is Correct.Dragtrqcontrol not active.NoTrqIntervention" ;
VAL_ 368 EngTrqLimFastStatus 3 "Signal is not available" 2 "Value is impluasible due to detected Failure at brake system" 1 "Value is correct.TCS/ESP intervention active.Trqintervention Req" 0 "Value is correct.TCS/ESP intervention notactive.NoTrqintervention Req" ;
VAL_ 368 EngTrqLimSlowStatus 3 "Signal is not available" 2 "Value is implausible due to deteced failurre at brake system" 1 "Value is correct.TCS/ESP intervention active.Trqintervention Req" 0 "Value is correct.TCS/ESP intervention notactive.NoTrqintervention Req" ;
